VERSION "12.2.7"

NS_ :

BS_:

BU_: AMP CPD EASC HUD MHU XGW_Info PAS_Info PAS_LITE FCAM_Info

BO_ 1153 BCM_WarnMsg: 8 XGW_Info
 SG_ CHSKM_BCM_WarnMsg : 7|8@0+ (1,0) [0|255] "" MHU
 SG_ ALV_BCM_WarnMsg : 11|4@0+ (1,0) [0|14] "" MHU
 SG_ BCM_NoValidKey_1 : 12|1@0+ (1,0) [0|1] "" MHU
 SG_ BCM_SSB_defect : 13|1@0+ (1,0) [0|1] "" MHU
 SG_ BCM_WrongGearPosToStart : 14|1@0+ (1,0) [0|1] "" MHU
 SG_ BCM_NoValidKey_2 : 15|1@0+ (1,0) [0|1] "" MHU
 SG_ BCM_PressBrakeToStart : 16|1@0+ (1,0) [0|1] "" MHU
 SG_ BCM_TurnOffPosLightRemindr : 17|1@0+ (1,0) [0|1] "" MHU
 SG_ BCM_KeyFob_LowBattery : 18|1@0+ (1,0) [0|1] "" MHU
 SG_ BCM_StopLightDefect : 19|1@0+ (1,0) [0|1] "" MHU
 SG_ BCM_LowBeamDefect : 20|1@0+ (1,0) [0|1] "" MHU
 SG_ BCM_HighBeamDefect : 21|1@0+ (1,0) [0|1] "" MHU
 SG_ BCM_PositionLightDefect : 22|1@0+ (1,0) [0|1] "" MHU
 SG_ BCM_CHMLS_Defect : 23|1@0+ (1,0) [0|1] "" MHU
 SG_ BCM_LicencePlateLight_Defect : 24|1@0+ (1,0) [0|1] "" MHU
 SG_ BCM_FrontFog_Defect : 25|1@0+ (1,0) [0|1] "" MHU
 SG_ BCM_RearFog_Defect : 26|1@0+ (1,0) [0|1] "" MHU
 SG_ BCM_ReverseLightDefect : 27|1@0+ (1,0) [0|1] "" MHU
 SG_ BCM_RLS_Malfunction : 28|1@0+ (1,0) [0|1] "" MHU
 SG_ BCM_12VBattery_LowLevel : 29|1@0+ (1,0) [0|1] "" MHU
 SG_ BCM_ForgetKeyFOBInCar : 30|1@0+ (1,0) [0|1] "" MHU
 SG_ BCM_12VBattery_Discharging : 31|1@0+ (1,0) [0|1] "" MHU
 SG_ BCM_TurnIndicatorDefect : 32|1@0+ (1,0) [0|1] "" MHU,FCAM_Info
 SG_ BCM_dTPMS_Malfunc : 33|1@0+ (1,0) [0|1] "" MHU
 SG_ BCM_dTPMS_Malfunc_LostSensor : 34|1@0+ (1,0) [0|1] "" MHU
 SG_ BCM_dTPMS_LowPressure : 35|1@0+ (1,0) [0|1] "" MHU
 SG_ BCM_dTPMS_RapidLeak : 36|1@0+ (1,0) [0|1] "" MHU
 SG_ BCM_dTPMS_HighTemperature : 37|1@0+ (1,0) [0|1] "" MHU
 SG_ BCM_dTPMS_HighPressure : 38|1@0+ (1,0) [0|1] "" MHU
 SG_ BCM_dTPMS_LowBattery : 39|1@0+ (1,0) [0|1] "" MHU
 SG_ BCM_Keyfob_Leftcar : 40|1@0+ (1,0) [0|1] "" MHU
 SG_ BCM_IDB_Brakelight_Malfunction : 41|1@0+ (1,0) [0|1] "" MHU
 SG_ BCM_VCU_Brakelight_Malfunction : 42|1@0+ (1,0) [0|1] "" MHU
 SG_ BCM_ADAS_Turnlight_Malfunction : 43|1@0+ (1,0) [0|1] "" MHU
 SG_ BCM_ADAS_Highbeam_Malfunction : 44|1@0+ (1,0) [0|1] "" MHU
 SG_ BCM_ADAS_LowBeam_Malfunction : 45|1@0+ (1,0) [0|1] "" MHU
 SG_ BCM_MHU_Malfunction : 46|1@0+ (1,0) [0|1] "" MHU
 SG_ BCM_BCM_Malfunction : 47|1@0+ (1,0) [0|1] "" MHU
 SG_ BCM_SCM_Malfunction : 48|1@0+ (1,0) [0|1] "" MHU
 SG_ BCM_CrashSignalDefect : 49|1@0+ (1,0) [0|1] "" MHU
 SG_ BCM_FrontWiperDefect : 51|1@0+ (1,0) [0|1] "" MHU
 SG_ BCM_Rear_RightDoorLockDefect : 52|1@0+ (1,0) [0|1] "" MHU
 SG_ BCM_RearLeftDoorLockDefect : 53|1@0+ (1,0) [0|1] "" MHU
 SG_ BCM_Front_RightDoorLockDefect : 54|1@0+ (1,0) [0|1] "" MHU
 SG_ BCM_FrontLeftDoorLockDefect : 55|1@0+ (1,0) [0|1] "" MHU
 SG_ BCM_LDML_Malfunction : 56|1@0+ (1,0) [0|1] "" MHU
 SG_ BCM_LDMR_Malfunction : 57|1@0+ (1,0) [0|1] "" MHU
 SG_ BCM_RLBL_Malfunction : 58|1@0+ (1,0) [0|1] "" MHU
 SG_ BCM_RLBR_Malfunction : 59|1@0+ (1,0) [0|1] "" MHU
 SG_ BCM_RLT_Malfunction : 60|1@0+ (1,0) [0|1] "" MHU
 SG_ BCM_BCM_POWER_Malfunction : 61|1@0+ (1,0) [0|1] "" MHU
 SG_ BCM_IDB_AutoHazardBlinking_Malf : 62|1@0+ (1,0) [0|1] "" MHU
 SG_ BCM_AutoHLLevelingFault : 63|1@0+ (1,0) [0|1] "" MHU

BO_ 1154 XGW_WarnMsg: 8 XGW_Info
  SG_ CHSKM_XGW_WarnMsg : 7|8@0+ (1,0) [0|255] "" MHU
  SG_ ALV_XGW_WarnMsg : 11|4@0+ (1,0) [0|14] "" MHU
  SG_ XGW_AutoHLLevelingFault : 12|1@0+ (1,0) [0|1] "-" MHU
  SG_ XGW_WasherFluidLvlSw : 13|1@0+ (1,0) [0|1] "-" MHU
  SG_ XGW_Warning_Flag_3 : 14|1@0+ (1,0) [0|1] "-" MHU
  SG_ XGW_Warning_Flag_4 : 15|1@0+ (1,0) [0|1] "-" MHU
  SG_ XGW_Warning_Flag_5 : 16|1@0+ (1,0) [0|1] "-" MHU
  SG_ XGW_Warning_Flag_6 : 17|1@0+ (1,0) [0|1] "-" MHU
  SG_ XGW_Warning_Flag_7 : 18|1@0+ (1,0) [0|1] "-" MHU
  SG_ XGW_Warning_Flag_8 : 19|1@0+ (1,0) [0|1] "-" MHU
  SG_ XGW_Warning_Flag_9 : 20|1@0+ (1,0) [0|1] "-" MHU
  SG_ XGW_Warning_Flag_10 : 21|1@0+ (1,0) [0|1] "-" MHU
  SG_ XGW_Warning_Flag_11 : 22|1@0+ (1,0) [0|1] "-" MHU
  SG_ XGW_Warning_Flag_12 : 23|1@0+ (1,0) [0|1] "-" MHU
  SG_ XGW_Reserved_signal1 : 31|8@0+ (1,0) [0|255] "-" MHU
  SG_ XGW_Reserved_signal2 : 39|8@0+ (1,0) [0|255] "-" MHU
  SG_ XGW_Reserved_signal3 : 47|8@0+ (1,0) [0|255] "-" MHU
  SG_ XGW_Reserved_signal4 : 55|8@0+ (1,0) [0|255] "-" MHU
  SG_ XGW_Reserved_signal5 : 63|8@0+ (1,0) [0|255] "-" MHU

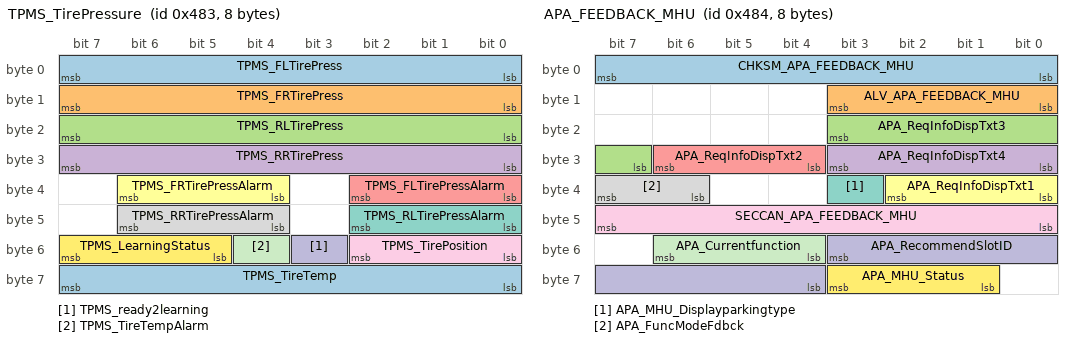
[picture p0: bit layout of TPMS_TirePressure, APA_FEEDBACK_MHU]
BO_ 1155 TPMS_TirePressure: 8 XGW_Info
  SG_ TPMS_FLTirePress : 7|8@0+ (1.373,0) [0|350] "kPa" MHU
  SG_ TPMS_FRTirePress : 15|8@0+ (1.373,0) [0|350] "kPa" MHU
  SG_ TPMS_RLTirePress : 23|8@0+ (1.373,0) [0|350] "kPa" MHU
  SG_ TPMS_RRTirePress : 31|8@0+ (1.373,0) [0|350] "kPa" MHU
  SG_ TPMS_FLTirePressAlarm : 34|3@0+ (1,0) [0|7] "" FCAM_Info,MHU
  SG_ TPMS_FRTirePressAlarm : 38|3@0+ (1,0) [0|7] "" FCAM_Info,MHU
  SG_ TPMS_RLTirePressAlarm : 42|3@0+ (1,0) [0|7] "" FCAM_Info,MHU
  SG_ TPMS_RRTirePressAlarm : 46|3@0+ (1,0) [0|7] "" FCAM_Info,MHU
  SG_ TPMS_TirePosition : 50|3@0+ (1,0) [0|7] "-" MHU
  SG_ TPMS_ready2learning : 51|1@0+ (1,0) [0|1] "-" MHU
  SG_ TPMS_TireTempAlarm : 52|1@0+ (1,0) [0|1] "-" MHU
  SG_ TPMS_LearningStatus : 55|3@0+ (1,0) [0|7] "-" MHU
  SG_ TPMS_TireTemp : 63|8@0+ (1,-40) [-40|215] "Degree C" MHU

BO_ 1156 APA_FEEDBACK_MHU: 8 PAS_Info
  SG_ CHKSM_APA_FEEDBACK_MHU : 7|8@0+ (1,0) [0|255] "" MHU,XGW_Info
  SG_ ALV_APA_FEEDBACK_MHU : 11|4@0+ (1,0) [0|14] "" MHU,XGW_Info
  SG_ APA_ReqInfoDispTxt3 : 19|5@0+ (1,0) [0|31] "-" MHU
  SG_ APA_ReqInfoDispTxt4 : 27|4@0+ (1,0) [0|15] "-" MHU
  SG_ APA_ReqInfoDispTxt2 : 30|3@0+ (1,0) [0|7] "-" MHU
  SG_ APA_ReqInfoDispTxt1 : 34|3@0+ (1,0) [0|7] "-" MHU
  SG_ APA_MHU_Displayparkingtype : 35|1@0+ (1,0) [0|1] "-" MHU
  SG_ APA_FuncModeFdbck : 39|2@0+ (1,0) [0|3] "-" MHU
  SG_ SECCAN_APA_FEEDBACK_MHU : 47|8@0+ (1,0) [0|255] ""  MHU
  SG_ APA_RecommendSlotID : 51|8@0+ (1,0) [0|255] "-" MHU
  SG_ APA_Currentfunction : 54|3@0+ (1,0) [0|7] "-" MHU
  SG_ APA_MHU_Status : 59|3@0+ (1,0) [0|7] "-" MHU,XGW_Info

BO_ 1157 TBox_RemVehCtrlAssist_SecOC3: 8 MHU
 SG_ TBOX_RPADirSel : 15|4@0+ (1,0) [0|15] ""  PAS_Info

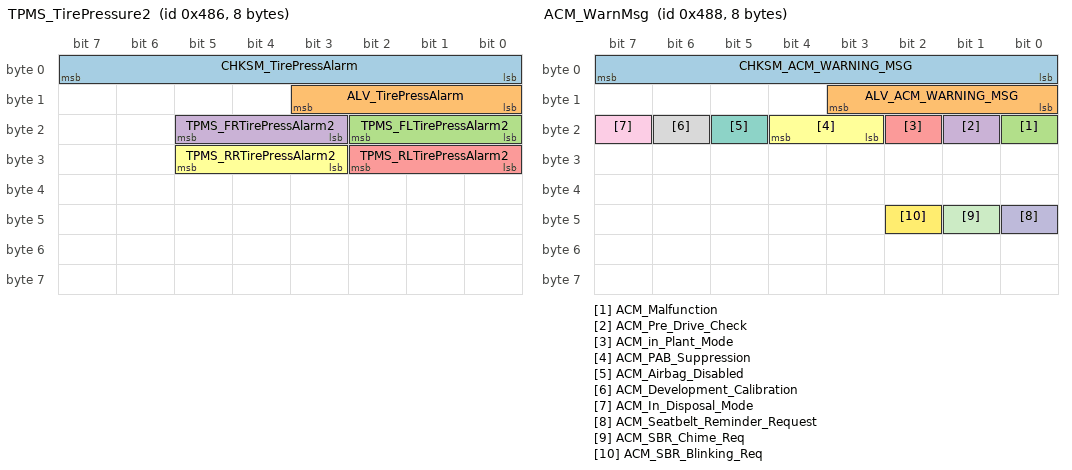
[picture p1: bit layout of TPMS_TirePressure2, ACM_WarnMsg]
BO_ 1158 TPMS_TirePressure2: 8 XGW_Info
 SG_ CHKSM_TirePressAlarm : 7|8@0+ (1,0) [0|255] ""  FCAM_Info,MHU
 SG_ ALV_TirePressAlarm : 11|4@0+ (1,0) [0|14] ""  FCAM_Info,MHU
 SG_ TPMS_FLTirePressAlarm2 : 18|3@0+ (1,0) [0|7] ""  FCAM_Info,MHU
 SG_ TPMS_FRTirePressAlarm2 : 21|3@0+ (1,0) [0|7] ""  FCAM_Info,MHU
 SG_ TPMS_RLTirePressAlarm2 : 26|3@0+ (1,0) [0|7] ""  FCAM_Info,MHU
 SG_ TPMS_RRTirePressAlarm2 : 29|3@0+ (1,0) [0|7] ""  FCAM_Info,MHU

BO_ 1160 ACM_WarnMsg: 8 XGW_Info
  SG_ CHKSM_ACM_WARNING_MSG : 7|8@0+ (1,0) [0|255] "" FCAM_Info,MHU
  SG_ ALV_ACM_WARNING_MSG : 11|4@0+ (1,0) [0|14] "" FCAM_Info,MHU
  SG_ ACM_Malfunction : 16|1@0+ (1,0) [0|1] "" FCAM_Info,MHU
  SG_ ACM_Pre_Drive_Check : 17|1@0+ (1,0) [0|1] "Bit" FCAM_Info,MHU
  SG_ ACM_in_Plant_Mode : 18|1@0+ (1,0) [0|1] "Bit" FCAM_Info,MHU
  SG_ ACM_PAB_Suppression : 20|2@0+ (1,0) [0|3] "Bit" FCAM_Info,MHU
  SG_ ACM_Airbag_Disabled : 21|1@0+ (1,0) [0|1] "" FCAM_Info,MHU
  SG_ ACM_Development_Calibration : 22|1@0+ (1,0) [0|1] "" FCAM_Info,MHU
  SG_ ACM_In_Disposal_Mode : 23|1@0+ (1,0) [0|1] "" FCAM_Info,MHU
  SG_ ACM_Seatbelt_Reminder_Request : 40|1@0+ (1,0) [0|1] "" FCAM_Info,MHU
  SG_ ACM_SBR_Chime_Req : 41|1@0+ (1,0) [0|1] "" FCAM_Info,MHU
  SG_ ACM_SBR_Blinking_Req : 42|1@0+ (1,0) [0|1] "" FCAM_Info,MHU

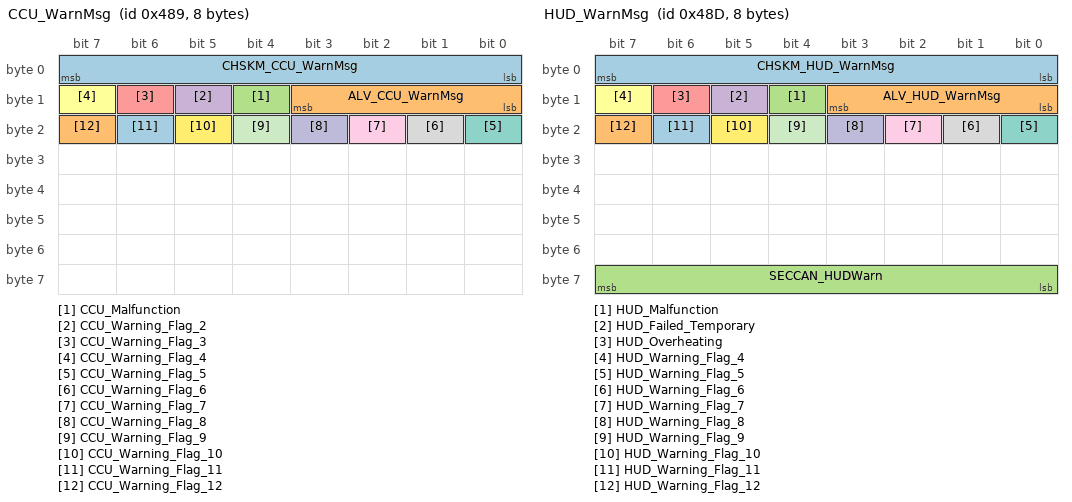
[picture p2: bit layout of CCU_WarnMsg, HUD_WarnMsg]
BO_ 1161 CCU_WarnMsg: 8 XGW_Info
  SG_ CHSKM_CCU_WarnMsg : 7|8@0+ (1,0) [0|255] "" MHU
  SG_ ALV_CCU_WarnMsg : 11|4@0+ (1,0) [0|14] "" MHU
  SG_ CCU_Malfunction : 12|1@0+ (1,0) [0|1] "" MHU
  SG_ CCU_Warning_Flag_2 : 13|1@0+ (1,0) [0|1] "-" MHU
  SG_ CCU_Warning_Flag_3 : 14|1@0+ (1,0) [0|1] "" MHU
  SG_ CCU_Warning_Flag_4 : 15|1@0+ (1,0) [0|1] "-" MHU
  SG_ CCU_Warning_Flag_5 : 16|1@0+ (1,0) [0|1] "-" MHU
  SG_ CCU_Warning_Flag_6 : 17|1@0+ (1,0) [0|1] "-" MHU
  SG_ CCU_Warning_Flag_7 : 18|1@0+ (1,0) [0|1] "-" MHU
  SG_ CCU_Warning_Flag_8 : 19|1@0+ (1,0) [0|1] "" MHU
  SG_ CCU_Warning_Flag_9 : 20|1@0+ (1,0) [0|1] "" MHU
  SG_ CCU_Warning_Flag_10 : 21|1@0+ (1,0) [0|1] "" MHU
  SG_ CCU_Warning_Flag_11 : 22|1@0+ (1,0) [0|1] "" MHU
  SG_ CCU_Warning_Flag_12 : 23|1@0+ (1,0) [0|1] "" MHU

BO_ 1165 HUD_WarnMsg: 8 HUD
  SG_ CHSKM_HUD_WarnMsg : 7|8@0+ (1,0) [0|255] "" MHU
  SG_ ALV_HUD_WarnMsg : 11|4@0+ (1,0) [0|14] "" MHU
  SG_ HUD_Malfunction : 12|1@0+ (1,0) [0|1] "-" MHU
  SG_ HUD_Failed_Temporary : 13|1@0+ (1,0) [0|1] "-" MHU
  SG_ HUD_Overheating : 14|1@0+ (1,0) [0|1] "-" MHU
  SG_ HUD_Warning_Flag_4 : 15|1@0+ (1,0) [0|1] "-" MHU
  SG_ HUD_Warning_Flag_5 : 16|1@0+ (1,0) [0|1] "-" MHU
  SG_ HUD_Warning_Flag_6 : 17|1@0+ (1,0) [0|1] "-" MHU
  SG_ HUD_Warning_Flag_7 : 18|1@0+ (1,0) [0|1] "-" MHU
  SG_ HUD_Warning_Flag_8 : 19|1@0+ (1,0) [0|1] "-" MHU
  SG_ HUD_Warning_Flag_9 : 20|1@0+ (1,0) [0|1] "-" MHU
  SG_ HUD_Warning_Flag_10 : 21|1@0+ (1,0) [0|1] "-" MHU
  SG_ HUD_Warning_Flag_11 : 22|1@0+ (1,0) [0|1] "-" MHU
  SG_ HUD_Warning_Flag_12 : 23|1@0+ (1,0) [0|1] "-" MHU
  SG_ SECCAN_HUDWarn : 63|8@0+ (1,0) [0|255] "" MHU

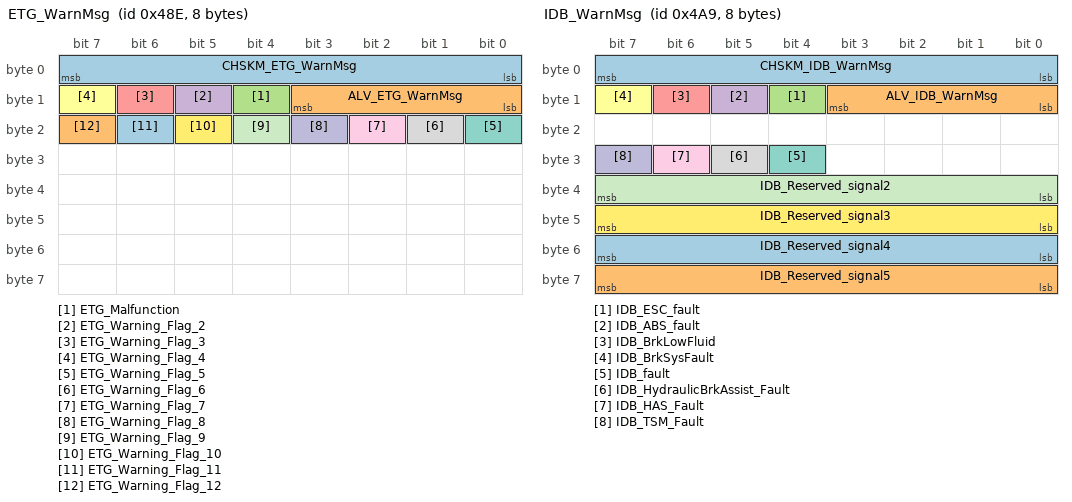
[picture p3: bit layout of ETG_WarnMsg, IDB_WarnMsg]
BO_ 1166 ETG_WarnMsg: 8 XGW_Info
  SG_ CHSKM_ETG_WarnMsg : 7|8@0+ (1,0) [0|255] "" MHU
  SG_ ALV_ETG_WarnMsg : 11|4@0+ (1,0) [0|14] "" MHU
  SG_ ETG_Malfunction : 12|1@0+ (1,0) [0|1] "-" MHU
  SG_ ETG_Warning_Flag_2 : 13|1@0+ (1,0) [0|1] "-" MHU
  SG_ ETG_Warning_Flag_3 : 14|1@0+ (1,0) [0|1] "" MHU
  SG_ ETG_Warning_Flag_4 : 15|1@0+ (1,0) [0|1] "" MHU
  SG_ ETG_Warning_Flag_5 : 16|1@0+ (1,0) [0|1] "-" MHU
  SG_ ETG_Warning_Flag_6 : 17|1@0+ (1,0) [0|1] "-" MHU
  SG_ ETG_Warning_Flag_7 : 18|1@0+ (1,0) [0|1] "-" MHU
  SG_ ETG_Warning_Flag_8 : 19|1@0+ (1,0) [0|1] "" MHU
  SG_ ETG_Warning_Flag_9 : 20|1@0+ (1,0) [0|1] "" MHU
  SG_ ETG_Warning_Flag_10 : 21|1@0+ (1,0) [0|1] "" MHU
  SG_ ETG_Warning_Flag_11 : 22|1@0+ (1,0) [0|1] "-" MHU
  SG_ ETG_Warning_Flag_12 : 23|1@0+ (1,0) [0|1] "" MHU

BO_ 1168 GS_WarnMsg: 8 XGW_Info
  SG_ CHSKM_GS_WarnMsg : 7|8@0+ (1,0) [0|255] "" MHU
  SG_ ALV_GS_WarnMsg : 11|4@0+ (1,0) [0|14] "" MHU
  SG_ GS_Warning_Flag_1 : 12|1@0+ (1,0) [0|1] "" MHU
  SG_ GS_Warning_Flag_2 : 13|1@0+ (1,0) [0|1] "" MHU
  SG_ GS_Warning_Flag_3 : 14|1@0+ (1,0) [0|1] "-" MHU
  SG_ GS_Warning_Flag_4 : 15|1@0+ (1,0) [0|1] "-" MHU
  SG_ GS_Warning_Flag_5 : 16|1@0+ (1,0) [0|1] "" MHU
  SG_ GS_Warning_Flag_6 : 17|1@0+ (1,0) [0|1] "-" MHU
  SG_ GS_Warning_Flag_7 : 18|1@0+ (1,0) [0|1] "" MHU
  SG_ GS_Warning_Flag_8 : 19|1@0+ (1,0) [0|1] "" MHU
  SG_ GS_Warning_Flag_9 : 20|1@0+ (1,0) [0|1] "-" MHU
  SG_ GS_Warning_Flag_10 : 21|1@0+ (1,0) [0|1] "-" MHU
  SG_ GS_Warning_Flag_11 : 22|1@0+ (1,0) [0|1] "" MHU
  SG_ GS_Warning_Flag_12 : 23|1@0+ (1,0) [0|1] "" MHU
  SG_ GS_Reserved_signal1 : 31|8@0+ (1,0) [0|255] "-" MHU
  SG_ GS_Reserved_signal2 : 39|8@0+ (1,0) [0|255] "" MHU
  SG_ GS_Reserved_signal3 : 47|8@0+ (1,0) [0|255] "" MHU
  SG_ GS_Reserved_signal4 : 55|8@0+ (1,0) [0|255] "-" MHU
  SG_ GS_Reserved_signal5 : 63|8@0+ (1,0) [0|255] "" MHU

BO_ 1171 BMS_WarnMsg: 8 XGW_Info
  SG_ CHSKM_BMS_WarnMsg : 7|8@0+ (1,0) [0|255] "" HUD,MHU
  SG_ ALV_BMS_WarnMsg : 11|4@0+ (1,0) [0|14] "" HUD,MHU
  SG_ BMS_PackTempSts : 13|2@0+ (1,0) [0|3] "" MHU
  SG_ BMS_ThermalRunaway : 14|1@0+ (1,0) [0|1] "" HUD,MHU
  SG_ BMS_BatteryReplacement : 15|1@0+ (1,0) [0|1] "" MHU
  SG_ BMS_Warning_PowerDegrade : 16|1@0+ (1,0) [0|1] "" MHU
  SG_ BMS_Warning_DeltaSoC : 17|1@0+ (1,0) [0|1] "" MHU
  SG_ BMS_Warning_HVILSts : 18|1@0+ (1,0) [0|1] "" MHU
  SG_ BMS_Warning_Isolation : 19|1@0+ (1,0) [0|1] "" MHU
  SG_ BMS_Warning_CoolantLeakage : 20|1@0+ (1,0) [0|1] "" MHU
  SG_ BMS_MalfunctionSts : 21|1@0+ (1,0) [0|1] "" MHU
  SG_ BMS_LowBattery : 23|2@0+ (1,0) [0|3] "" HUD,MHU
  SG_ BMS_Warning_DeltaTemperature : 31|8@0+ (1,0) [0|255] "" MHU
  SG_ BMS_Warning_BDUTemperatureSts : 39|8@0+ (1,0) [0|255] "" MHU
  SG_ BMS_Warning_Contactor_Aging : 47|1@0+ (1,0) [0|1] "" MHU
  SG_ BMS_Reserved_signal4 : 55|8@0+ (1,0) [0|255] "" MHU
  SG_ BMS_Reserved_signal5 : 63|8@0+ (1,0) [0|255] "" MHU

BO_ 1178 EDS_R_WarnMsg: 8 XGW_Info
  SG_ CHSKM_EDS_R_WarnMsg : 7|8@0+ (1,0) [0|255] "" MHU
  SG_ ALV_EDS_R_WarnMsg : 11|4@0+ (1,0) [0|14] "" MHU
  SG_ EDS_R_Warning_Flag_1 : 12|1@0+ (1,0) [0|1] "" MHU
  SG_ EDS_R_Warning_Flag_2 : 13|1@0+ (1,0) [0|1] "" MHU
  SG_ EDS_R_Warning_Flag_3 : 14|1@0+ (1,0) [0|1] "" MHU
  SG_ EDS_R_Warning_Flag_4 : 15|1@0+ (1,0) [0|1] "-" MHU
  SG_ EDS_R_Warning_Flag_5 : 16|1@0+ (1,0) [0|1] "" MHU
  SG_ EDS_R_Warning_Flag_6 : 17|1@0+ (1,0) [0|1] "-" MHU
  SG_ EDS_R_Warning_Flag_7 : 18|1@0+ (1,0) [0|1] "" MHU
  SG_ EDS_R_Warning_Flag_8 : 19|1@0+ (1,0) [0|1] "" MHU
  SG_ EDS_R_Warning_Flag_9 : 20|1@0+ (1,0) [0|1] "-" MHU
  SG_ EDS_R_Warning_Flag_10 : 21|1@0+ (1,0) [0|1] "" MHU
  SG_ EDS_R_Warning_Flag_11 : 22|1@0+ (1,0) [0|1] "" MHU
  SG_ EDS_R_Warning_Flag_12 : 23|1@0+ (1,0) [0|1] "-" MHU
  SG_ EDS_R_Reserved_signal1 : 31|8@0+ (1,0) [0|255] "" MHU
  SG_ EDS_R_Reserved_signal2 : 39|8@0+ (1,0) [0|255] "" MHU
  SG_ EDS_R_Reserved_signal3 : 47|8@0+ (1,0) [0|255] "-" MHU
  SG_ EDS_R_Reserved_signal4 : 55|8@0+ (1,0) [0|255] "-" MHU
  SG_ EDS_R_Reserved_signal5 : 63|8@0+ (1,0) [0|255] "-" MHU

BO_ 1179 EDS_F_WarnMsg: 8 XGW_Info
  SG_ CHSKM_EDS_F_WarnMsg : 7|8@0+ (1,0) [0|255] "" MHU
  SG_ ALV_EDS_F_WarnMsg : 11|4@0+ (1,0) [0|14] "" MHU
  SG_ EDS_F_Warning_Flag_1 : 12|1@0+ (1,0) [0|1] "" MHU
  SG_ EDS_F_Warning_Flag_2 : 13|1@0+ (1,0) [0|1] "-" MHU
  SG_ EDS_F_Warning_Flag_3 : 14|1@0+ (1,0) [0|1] "-" MHU
  SG_ EDS_F_Warning_Flag_4 : 15|1@0+ (1,0) [0|1] "" MHU
  SG_ EDS_F_Warning_Flag_5 : 16|1@0+ (1,0) [0|1] "" MHU
  SG_ EDS_F_Warning_Flag_6 : 17|1@0+ (1,0) [0|1] "-" MHU
  SG_ EDS_F_Warning_Flag_7 : 18|1@0+ (1,0) [0|1] "-" MHU
  SG_ EDS_F_Warning_Flag_8 : 19|1@0+ (1,0) [0|1] "" MHU
  SG_ EDS_F_Warning_Flag_9 : 20|1@0+ (1,0) [0|1] "" MHU
  SG_ EDS_F_Warning_Flag_10 : 21|1@0+ (1,0) [0|1] "-" MHU
  SG_ EDS_F_Warning_Flag_11 : 22|1@0+ (1,0) [0|1] "-" MHU
  SG_ EDS_F_Warning_Flag_12 : 23|1@0+ (1,0) [0|1] "" MHU
  SG_ EDS_F_Reserved_signal1 : 31|8@0+ (1,0) [0|255] "" MHU
  SG_ EDS_F_Reserved_signal2 : 39|8@0+ (1,0) [0|255] "-" MHU
  SG_ EDS_F_Reserved_signal3 : 47|8@0+ (1,0) [0|255] "" MHU
  SG_ EDS_F_Reserved_signal4 : 55|8@0+ (1,0) [0|255] "-" MHU
  SG_ EDS_F_Reserved_signal5 : 63|8@0+ (1,0) [0|255] "" MHU

BO_ 1191 RCU_WarnMsg: 8 XGW_Info
  SG_ CHSKM_RCU_WarnMsg : 7|8@0+ (1,0) [0|255] "" MHU
  SG_ ALV_RCU_WarnMsg : 11|4@0+ (1,0) [0|14] "" MHU
  SG_ RCU_DAA_NoOpDoorOpen : 12|1@0+ (1,0) [0|1] "" MHU
  SG_ RCU_EHandBrk_fault : 13|1@0+ (1,0) [0|1] "" MHU
  SG_ RCU_EOL_NotDone : 14|1@0+ (1,0) [0|1] "" MHU
  SG_ RCU_ECD_RWU_active : 15|1@0+ (1,0) [0|1] "" MHU
  SG_ RCU_ParkOnSteepInclination : 16|1@0+ (1,0) [0|1] "" MHU
  SG_ RCU_BrkForceNotEnough : 17|1@0+ (1,0) [0|1] "" MHU
  SG_ RCU_ReleaseEPB_Wo_PressBrk : 20|1@0+ (1,0) [0|1] "" MHU
  SG_ RCU_ParkBrkApplied : 21|1@0+ (1,0) [0|1] "" MHU
  SG_ RCU_Swch_Mafnc : 27|1@0+ (1,0) [0|1] "" MHU
  SG_ RCU_DAA_NoOpBeltUnbuckled : 28|1@0+ (1,0) [0|1] "" MHU
  SG_ RCU_RollerBenchMode : 29|1@0+ (1,0) [0|1] "" MHU
  SG_ RCU_EPB_ParkLampState : 31|2@0+ (1,0) [0|3] "" MHU
  SG_ RCU_EPB_WarnLampState : 34|2@0+ (1,0) [0|3] "" MHU
  SG_ RCU_WflagRes36 : 36|1@0+ (1,0) [0|1] "" MHU
  SG_ RCU_WflagRes37 : 37|1@0+ (1,0) [0|1] "" MHU
  SG_ RCU_WflagRes38 : 38|1@0+ (1,0) [0|1] "" MHU
  SG_ RCU_WflagRes39 : 39|1@0+ (1,0) [0|1] "" MHU
  SG_ RCU_WflagRes40 : 40|1@0+ (1,0) [0|1] "" MHU
  SG_ RCU_WflagRes41 : 41|1@0+ (1,0) [0|1] "" MHU
  SG_ RCU_WflagRes42 : 42|1@0+ (1,0) [0|1] "" MHU
  SG_ RCU_WflagRes43 : 43|1@0+ (1,0) [0|1] "" MHU
  SG_ RCU_WflagRes44 : 44|1@0+ (1,0) [0|1] "" MHU
  SG_ RCU_WflagRes45 : 45|1@0+ (1,0) [0|1] "" MHU
  SG_ RCU_WflagRes46 : 46|1@0+ (1,0) [0|1] "" MHU
  SG_ RCU_WflagRes47 : 47|1@0+ (1,0) [0|1] "" MHU
  SG_ RCU_Reserved_signal1 : 55|8@0+ (1,0) [0|255] "" MHU

BO_ 1192 EPS_WarnMsg: 8 XGW_Info
  SG_ CHSKM_EPS_WarnMsg : 7|8@0+ (1,0) [0|255] "" MHU
  SG_ ALV_EPS_WarnMsg : 11|4@0+ (1,0) [0|14] "" MHU
  SG_ EPS_Malfunction : 12|1@0+ (1,0) [0|1] "-" MHU
  SG_ EPS_Reduced : 13|1@0+ (1,0) [0|1] "-" MHU
  SG_ EPS_Overheat : 14|1@0+ (1,0) [0|1] "" MHU
  SG_ EPS_NotReady : 15|1@0+ (1,0) [0|1] "-" MHU
  SG_ EPS_Warning_Flag_5 : 16|1@0+ (1,0) [0|1] "-" MHU
  SG_ EPS_Warning_Flag_6 : 17|1@0+ (1,0) [0|1] "" MHU
  SG_ EPS_Warning_Flag_7 : 18|1@0+ (1,0) [0|1] "" MHU
  SG_ EPS_Warning_Flag_8 : 19|1@0+ (1,0) [0|1] "-" MHU
  SG_ EPS_Warning_Flag_9 : 20|1@0+ (1,0) [0|1] "-" MHU
  SG_ EPS_Warning_Flag_10 : 21|1@0+ (1,0) [0|1] "" MHU
  SG_ EPS_Warning_Flag_11 : 22|1@0+ (1,0) [0|1] "" MHU
  SG_ EPS_Warning_Flag_12 : 23|1@0+ (1,0) [0|1] "-" MHU
  SG_ EPS_Reserved_signal1 : 31|8@0+ (1,0) [0|255] "" MHU
  SG_ EPS_Reserved_signal2 : 39|8@0+ (1,0) [0|255] "" MHU
  SG_ EPS_Reserved_signal3 : 47|8@0+ (1,0) [0|255] "-" MHU
  SG_ EPS_Reserved_signal4 : 55|8@0+ (1,0) [0|255] "" MHU
  SG_ EPS_Reserved_signal5 : 63|8@0+ (1,0) [0|255] "" MHU

BO_ 1193 IDB_WarnMsg: 8 XGW_Info
  SG_ CHSKM_IDB_WarnMsg : 7|8@0+ (1,0) [0|255] "" MHU
  SG_ ALV_IDB_WarnMsg : 11|4@0+ (1,0) [0|14] "" MHU
  SG_ IDB_ESC_fault : 12|1@0+ (1,0) [0|1] "-" MHU
  SG_ IDB_ABS_fault : 13|1@0+ (1,0) [0|1] "" MHU
  SG_ IDB_BrkLowFluid : 14|1@0+ (1,0) [0|1] "" MHU
  SG_ IDB_BrkSysFault : 15|1@0+ (1,0) [0|1] "-" MHU
  SG_ IDB_fault : 28|1@0+ (1,0) [0|1] "" MHU
  SG_ IDB_HydraulicBrkAssist_Fault : 29|1@0+ (1,0) [0|1] "-" MHU
  SG_ IDB_HAS_Fault : 30|1@0+ (1,0) [0|1] "" MHU
  SG_ IDB_TSM_Fault : 31|1@0+ (1,0) [0|1] "" MHU
  SG_ IDB_Reserved_signal2 : 39|8@0+ (1,0) [0|255] "-" MHU
  SG_ IDB_Reserved_signal3 : 47|8@0+ (1,0) [0|255] "-" MHU
  SG_ IDB_Reserved_signal4 : 55|8@0+ (1,0) [0|255] "-" MHU
  SG_ IDB_Reserved_signal5 : 63|8@0+ (1,0) [0|255] "" MHU

BO_ 1196 VCU_WarnMsg: 8 XGW_Info
  SG_ CHSKM_VCU_WarnMsg : 7|8@0+ (1,0) [0|255] "" MHU
  SG_ ALV_VCU_WarnMsg : 11|4@0+ (1,0) [0|14] "" MHU
  SG_ VCU_GearPOnlyAtStationaryAlert : 12|1@0+ (1,0) [0|1] "" MHU
  SG_ VCU_GearP_NotPossibleAlert : 13|1@0+ (1,0) [0|1] "" MHU
  SG_ VCU_PressBrakeToEngageGear : 14|1@0+ (1,0) [0|1] "" MHU
  SG_ VCU_CantChangeGear : 15|1@0+ (1,0) [0|1] "" MHU
  SG_ VCU_GearMalfunction : 16|1@0+ (1,0) [0|1] "" MHU
  SG_ VCU_RangeAlert : 17|1@0+ (1,0) [0|1] "" MHU
  SG_ VCU_HVSystemReduced : 18|1@0+ (1,0) [0|1] "" MHU
  SG_ VCU_FrontEDSReduced : 19|1@0+ (1,0) [0|1] "" MHU
  SG_ VCU_FrontEDS_Malfunc : 20|1@0+ (1,0) [0|1] "" MHU
  SG_ VCU_RearEDSReduced : 21|1@0+ (1,0) [0|1] "" MHU
  SG_ VCU_RearEDS_Malfunc : 22|1@0+ (1,0) [0|1] "" MHU
  SG_ VCU_CoolingSystem_Malfunc : 23|1@0+ (1,0) [0|1] "" MHU
  SG_ VCU_NeutralRequest : 24|1@0+ (1,0) [0|1] "" MHU
  SG_ VCU_SoftShutdown : 25|1@0+ (1,0) [0|1] "" MHU
  SG_ VCU_EmergencyShutdown : 26|1@0+ (1,0) [0|1] "" MHU
  SG_ VCU_ChgPortDoorSys_Malfunc : 27|1@0+ (1,0) [0|1] "" MHU
  SG_ VCU_Gearchange_NotPossible : 28|1@0+ (1,0) [0|1] "" MHU
  SG_ VCU_12v_Warning : 29|1@0+ (1,0) [0|1] "" MHU
  SG_ VCU_WflagRes19 : 30|1@0+ (1,0) [0|1] "" MHU
  SG_ VCU_WflagRes20 : 31|1@0+ (1,0) [0|1] "" MHU
  SG_ VCU_WflagRes21 : 32|1@0+ (1,0) [0|1] "" MHU
  SG_ VCU_WflagRes22 : 33|1@0+ (1,0) [0|1] "" MHU
  SG_ VCU_WflagRes23 : 34|1@0+ (1,0) [0|1] "" MHU
  SG_ VCU_WflagRes24 : 35|1@0+ (1,0) [0|1] "" MHU
  SG_ VCU_WflagRes25 : 36|1@0+ (1,0) [0|1] "" MHU
  SG_ VCU_WflagRes26 : 37|1@0+ (1,0) [0|1] "" MHU
  SG_ VCU_WflagRes27 : 38|1@0+ (1,0) [0|1] "" MHU
  SG_ VCU_SuperFastCharge_longer : 39|1@0+ (1,0) [0|1] "" MHU
  SG_ VCU_InvalidLimitSpeed : 46|1@0+ (1,0) [0|1] "" MHU
  SG_ VCU_InvalidCruiseSpeed : 47|1@0+ (1,0) [0|1] "" MHU
  SG_ VCU_Reserved_signal2 : 55|8@0+ (1,0) [0|255] "" MHU
  SG_ VCU_Reserved_signal3 : 63|8@0+ (1,0) [0|255] "" MHU

BO_ 1198 EASC_WarnMsg: 8 EASC
  SG_ CHSKM_EASC_WarnMsg : 7|8@0+ (1,0) [0|255] "" MHU
  SG_ ALV_EASC_WarnMsg : 11|4@0+ (1,0) [0|14] "" MHU
  SG_ EASC_Warning_Flag_1 : 12|1@0+ (1,0) [0|1] "-" MHU
  SG_ EASC_Warning_Flag_2 : 13|1@0+ (1,0) [0|1] "-" MHU
  SG_ EASC_Warning_Flag_3 : 14|1@0+ (1,0) [0|1] "-" MHU
  SG_ EASC_Warning_Flag_4 : 15|1@0+ (1,0) [0|1] "-" MHU
  SG_ EASC_Warning_Flag_5 : 16|1@0+ (1,0) [0|1] "-" MHU
  SG_ EASC_Warning_Flag_6 : 17|1@0+ (1,0) [0|1] "-" MHU
  SG_ EASC_Warning_Flag_7 : 18|1@0+ (1,0) [0|1] "-" MHU
  SG_ EASC_Warning_Flag_8 : 19|1@0+ (1,0) [0|1] "-" MHU
  SG_ EASC_Warning_Flag_9 : 20|1@0+ (1,0) [0|1] "-" MHU
  SG_ EASC_Warning_Flag_10 : 21|1@0+ (1,0) [0|1] "-" MHU
  SG_ EASC_Warning_Flag_11 : 22|1@0+ (1,0) [0|1] "-" MHU
  SG_ EASC_Warning_Flag_12 : 23|1@0+ (1,0) [0|1] "-" MHU
  SG_ EASC_Reserved_signal1 : 31|8@0+ (1,0) [0|255] "-" MHU
  SG_ EASC_Reserved_signal2 : 39|8@0+ (1,0) [0|255] "-" MHU
  SG_ EASC_Reserved_signal3 : 47|8@0+ (1,0) [0|255] "-" MHU
  SG_ EASC_Reserved_signal4 : 55|8@0+ (1,0) [0|255] "-" MHU
  SG_ EASC_Reserved_signal5 : 63|8@0+ (1,0) [0|255] "-" MHU

BO_ 1199 CPD_WarnMsg: 8 CPD
  SG_ CHSKM_CPD_WarnMsg : 7|8@0+ (1,0) [0|255] "" MHU
  SG_ ALV_CPD_WarnMsg : 11|4@0+ (1,0) [0|14] "" MHU
  SG_ CPD_Malfunction : 12|1@0+ (1,0) [0|1] "" MHU
  SG_ CPD_SensorFault : 14|2@0+ (1,0) [0|3] "" MHU
  SG_ CPD_Warning_Flag_4 : 15|1@0+ (1,0) [0|1] "" MHU
  SG_ CPD_Warning_Flag_5 : 16|1@0+ (1,0) [0|1] "" MHU
  SG_ CPD_Warning_Flag_6 : 17|1@0+ (1,0) [0|1] "" MHU
  SG_ CPD_Warning_Flag_7 : 18|1@0+ (1,0) [0|1] "" MHU
  SG_ CPD_Warning_Flag_8 : 19|1@0+ (1,0) [0|1] "" MHU
  SG_ CPD_Warning_Flag_9 : 20|1@0+ (1,0) [0|1] "" MHU
  SG_ CPD_Warning_Flag_10 : 21|1@0+ (1,0) [0|1] "" MHU
  SG_ CPD_Warning_Flag_11 : 22|1@0+ (1,0) [0|1] "" MHU
  SG_ CPD_Warning_Flag_12 : 23|1@0+ (1,0) [0|1] "" MHU
  SG_ CPD_Reserved_signal1 : 31|8@0+ (1,0) [0|255] "" MHU
  SG_ CPD_Reserved_signal2 : 39|8@0+ (1,0) [0|255] "" MHU
  SG_ CPD_Reserved_signal3 : 47|8@0+ (1,0) [0|255] "" MHU
  SG_ CPD_Reserved_signal4 : 55|8@0+ (1,0) [0|255] "" MHU
  SG_ CPD_Reserved_signal5 : 63|8@0+ (1,0) [0|255] "" MHU

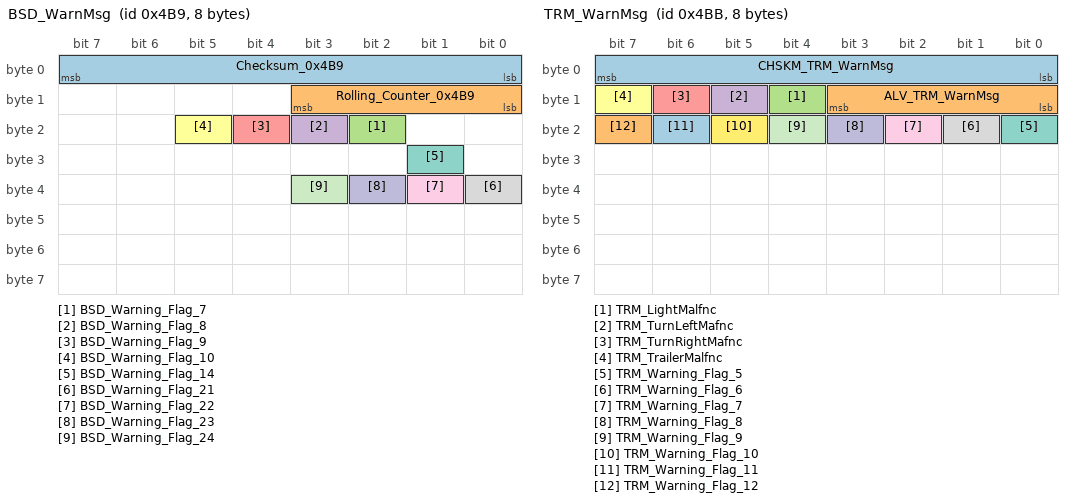
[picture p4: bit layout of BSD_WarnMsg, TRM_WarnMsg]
BO_ 1209 BSD_WarnMsg: 8 XGW_Info
 SG_ Checksum_0x4B9 : 7|8@0+ (1,0) [0|255] "" MHU
 SG_ Rolling_Counter_0x4B9 : 11|4@0+ (1,0) [0|15] "" MHU
 SG_ BSD_Warning_Flag_7 : 18|1@0+ (1,0) [0|1] "" MHU
 SG_ BSD_Warning_Flag_8 : 19|1@0+ (1,0) [0|1] "" MHU
 SG_ BSD_Warning_Flag_9 : 20|1@0+ (1,0) [0|1] "" MHU
 SG_ BSD_Warning_Flag_10 : 21|1@0+ (1,0) [0|1] "" MHU
 SG_ BSD_Warning_Flag_14 : 25|1@0+ (1,0) [0|1] "" MHU
 SG_ BSD_Warning_Flag_21 : 32|1@0+ (1,0) [0|1] "" MHU
 SG_ BSD_Warning_Flag_22 : 33|1@0+ (1,0) [0|1] "" MHU
 SG_ BSD_Warning_Flag_23 : 34|1@0+ (1,0) [0|1] "" MHU
 SG_ BSD_Warning_Flag_24 : 35|1@0+ (1,0) [0|1] "" MHU

BO_ 1211 TRM_WarnMsg: 8 XGW_Info
  SG_ CHSKM_TRM_WarnMsg : 7|8@0+ (1,0) [0|255] "" MHU
  SG_ ALV_TRM_WarnMsg : 11|4@0+ (1,0) [0|14] "" MHU
  SG_ TRM_LightMalfnc : 12|1@0+ (1,0) [0|1] "-" MHU
  SG_ TRM_TurnLeftMafnc : 13|1@0+ (1,0) [0|1] "-" MHU
  SG_ TRM_TurnRightMafnc : 14|1@0+ (1,0) [0|1] "" MHU
  SG_ TRM_TrailerMalfnc : 15|1@0+ (1,0) [0|1] "" MHU
  SG_ TRM_Warning_Flag_5 : 16|1@0+ (1,0) [0|1] "-" MHU
  SG_ TRM_Warning_Flag_6 : 17|1@0+ (1,0) [0|1] "" MHU
  SG_ TRM_Warning_Flag_7 : 18|1@0+ (1,0) [0|1] "" MHU
  SG_ TRM_Warning_Flag_8 : 19|1@0+ (1,0) [0|1] "-" MHU
  SG_ TRM_Warning_Flag_9 : 20|1@0+ (1,0) [0|1] "-" MHU
  SG_ TRM_Warning_Flag_10 : 21|1@0+ (1,0) [0|1] "-" MHU
  SG_ TRM_Warning_Flag_11 : 22|1@0+ (1,0) [0|1] "" MHU
  SG_ TRM_Warning_Flag_12 : 23|1@0+ (1,0) [0|1] "" MHU

BO_ 1213 POD_WarnMsg: 8 XGW_Info
  SG_ CHSKM_POD_WarnMsg : 7|8@0+ (1,0) [0|255] "" MHU
  SG_ ALV_POD_WarnMsg : 11|4@0+ (1,0) [0|14] "" MHU
  SG_ POD_Warning_Flag_1 : 12|1@0+ (1,0) [0|1] "-" MHU
  SG_ POD_Warning_Flag_2 : 13|1@0+ (1,0) [0|1] "-" MHU
  SG_ POD_Warning_Flag_3 : 14|1@0+ (1,0) [0|1] "-" MHU
  SG_ POD_Warning_Flag_4 : 15|1@0+ (1,0) [0|1] "-" MHU
  SG_ POD_Warning_Flag_5 : 16|1@0+ (1,0) [0|1] "-" MHU
  SG_ POD_Warning_Flag_6 : 17|1@0+ (1,0) [0|1] "-" MHU
  SG_ POD_Warning_Flag_7 : 18|1@0+ (1,0) [0|1] "-" MHU
  SG_ POD_Warning_Flag_8 : 19|1@0+ (1,0) [0|1] "-" MHU
  SG_ POD_Warning_Flag_9 : 20|1@0+ (1,0) [0|1] "-" MHU
  SG_ POD_Warning_Flag_10 : 21|1@0+ (1,0) [0|1] "-" MHU
  SG_ POD_Warning_Flag_11 : 22|1@0+ (1,0) [0|1] "-" MHU
  SG_ POD_Warning_Flag_12 : 23|1@0+ (1,0) [0|1] "-" MHU
  SG_ POD_Warning_Flag_13 : 24|1@0+ (1,0) [0|1] "-" MHU
  SG_ POD_Warning_Flag_14 : 25|1@0+ (1,0) [0|1] "-" MHU
  SG_ POD_Warning_Flag_15 : 26|1@0+ (1,0) [0|1] "-" MHU
  SG_ POD_Warning_Flag_16 : 27|1@0+ (1,0) [0|1] "-" MHU
  SG_ POD_Warning_Flag_17 : 28|1@0+ (1,0) [0|1] "-" MHU
  SG_ POD_Warning_Flag_18 : 29|1@0+ (1,0) [0|1] "-" MHU
  SG_ POD_Warning_Flag_19 : 30|1@0+ (1,0) [0|1] "-" MHU
  SG_ POD_Warning_Flag_20 : 31|1@0+ (1,0) [0|1] "-" MHU
  SG_ POD_Warning_Flag_21 : 32|1@0+ (1,0) [0|1] "-" MHU
  SG_ POD_Warning_Flag_22 : 33|1@0+ (1,0) [0|1] "-" MHU
  SG_ POD_Warning_Flag_23 : 34|1@0+ (1,0) [0|1] "-" MHU
  SG_ POD_Warning_Flag_24 : 35|1@0+ (1,0) [0|1] "-" MHU
  SG_ POD_Warning_Flag_25 : 36|1@0+ (1,0) [0|1] "-" MHU
  SG_ POD_Warning_Flag_26 : 37|1@0+ (1,0) [0|1] "-" MHU
  SG_ POD_Warning_Flag_27 : 38|1@0+ (1,0) [0|1] "-" MHU
  SG_ POD_Warning_Flag_28 : 39|1@0+ (1,0) [0|1] "-" MHU
  SG_ POD_Reserved_signal3 : 47|8@0+ (1,0) [0|255] "-" MHU
  SG_ POD_Reserved_signal4 : 55|8@0+ (1,0) [0|255] "-" MHU
  SG_ POD_Reserved_signal5 : 63|8@0+ (1,0) [0|255] "-" MHU

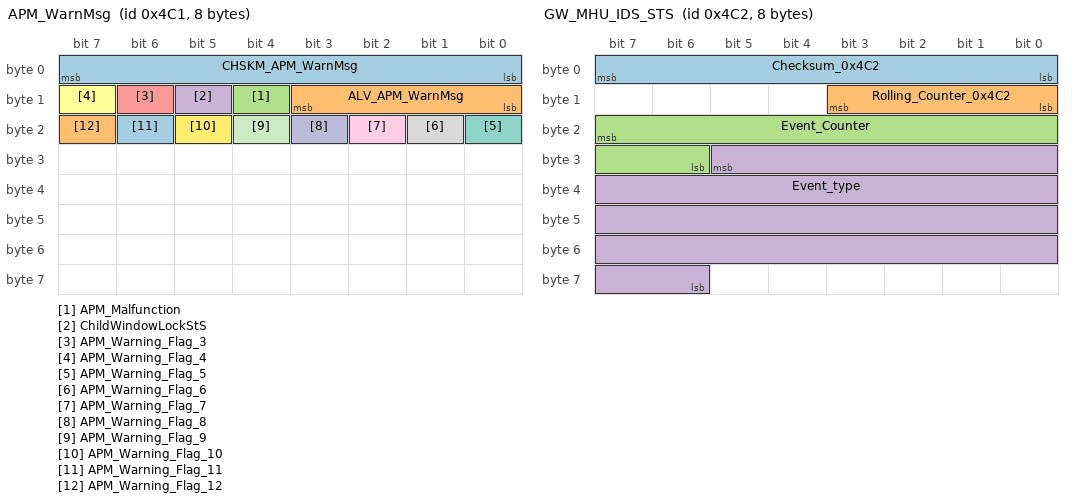
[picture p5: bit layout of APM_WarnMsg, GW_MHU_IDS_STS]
BO_ 1217 APM_WarnMsg: 8 XGW_Info
  SG_ CHSKM_APM_WarnMsg : 7|8@0+ (1,0) [0|255] "" MHU
  SG_ ALV_APM_WarnMsg : 11|4@0+ (1,0) [0|14] "" MHU
  SG_ APM_Malfunction : 12|1@0+ (1,0) [0|1] "" MHU
  SG_ ChildWindowLockStS : 13|1@0+ (1,0) [0|1] "-" MHU
  SG_ APM_Warning_Flag_3 : 14|1@0+ (1,0) [0|1] "" MHU
  SG_ APM_Warning_Flag_4 : 15|1@0+ (1,0) [0|1] "" MHU
  SG_ APM_Warning_Flag_5 : 16|1@0+ (1,0) [0|1] "-" MHU
  SG_ APM_Warning_Flag_6 : 17|1@0+ (1,0) [0|1] "" MHU
  SG_ APM_Warning_Flag_7 : 18|1@0+ (1,0) [0|1] "-" MHU
  SG_ APM_Warning_Flag_8 : 19|1@0+ (1,0) [0|1] "" MHU
  SG_ APM_Warning_Flag_9 : 20|1@0+ (1,0) [0|1] "" MHU
  SG_ APM_Warning_Flag_10 : 21|1@0+ (1,0) [0|1] "" MHU
  SG_ APM_Warning_Flag_11 : 22|1@0+ (1,0) [0|1] "" MHU
  SG_ APM_Warning_Flag_12 : 23|1@0+ (1,0) [0|1] "-" MHU

BO_ 1218 GW_MHU_IDS_STS: 8 XGW_Info
  SG_ Checksum_0x4C2 : 7|8@0+ (1,0) [0|255] "" MHU
  SG_ Rolling_Counter_0x4C2 : 11|4@0+ (1,0) [0|14] "" MHU
  SG_ Event_Counter : 23|10@0+ (1,0) [0|1023] "-" MHU
  SG_ Event_type : 29|32@0+ (1,0) [0|4294967295] "-" MHU

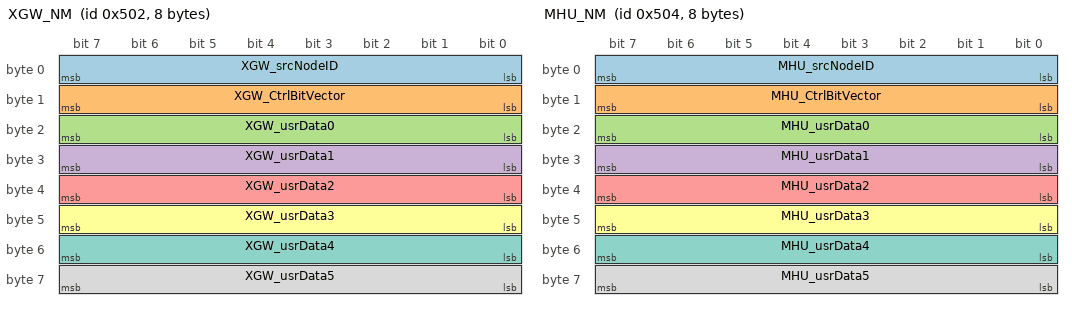
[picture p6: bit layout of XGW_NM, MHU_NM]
BO_ 1282 XGW_NM: 8 XGW_Info
  SG_ XGW_srcNodeID : 7|8@0+ (1,0) [0|255] "" Vector__XXX,CPD,EASC,HUD,MHU,PAS_Info,FCAM_Info
  SG_ XGW_CtrlBitVector : 15|8@0+ (1,0) [0|255] "" Vector__XXX,CPD,EASC,HUD,MHU,PAS_Info,FCAM_Info
  SG_ XGW_usrData0 : 23|8@0+ (1,0) [0|255] "" Vector__XXX,CPD,EASC,HUD,MHU,PAS_Info,FCAM_Info
  SG_ XGW_usrData1 : 31|8@0+ (1,0) [0|255] "" Vector__XXX,CPD,EASC,HUD,MHU,PAS_Info,FCAM_Info
  SG_ XGW_usrData2 : 39|8@0+ (1,0) [0|255] "" Vector__XXX,CPD,EASC,HUD,MHU,PAS_Info,FCAM_Info
  SG_ XGW_usrData3 : 47|8@0+ (1,0) [0|255] "" Vector__XXX,CPD,EASC,HUD,MHU,PAS_Info,FCAM_Info
  SG_ XGW_usrData4 : 55|8@0+ (1,0) [0|255] "" Vector__XXX,CPD,EASC,HUD,MHU,PAS_Info,FCAM_Info
  SG_ XGW_usrData5 : 63|8@0+ (1,0) [0|255] "" Vector__XXX,CPD,EASC,HUD,MHU,PAS_Info,FCAM_Info

BO_ 1284 MHU_NM: 8 MHU
  SG_ MHU_srcNodeID : 7|8@0+ (1,0) [0|255] "-" Vector__XXX,CPD,EASC,HUD,XGW_Info,PAS_Info,FCAM_Info
  SG_ MHU_CtrlBitVector : 15|8@0+ (1,0) [0|255] "-" Vector__XXX,CPD,EASC,HUD,XGW_Info,PAS_Info,FCAM_Info
  SG_ MHU_usrData0 : 23|8@0+ (1,0) [0|255] "-" Vector__XXX,CPD,EASC,HUD,XGW_Info,PAS_Info,FCAM_Info
  SG_ MHU_usrData1 : 31|8@0+ (1,0) [0|255] "-" Vector__XXX,CPD,EASC,HUD,XGW_Info,PAS_Info,FCAM_Info
  SG_ MHU_usrData2 : 39|8@0+ (1,0) [0|255] "-" Vector__XXX,CPD,EASC,HUD,XGW_Info,PAS_Info,FCAM_Info
  SG_ MHU_usrData3 : 47|8@0+ (1,0) [0|255] "-" Vector__XXX,CPD,EASC,HUD,XGW_Info,PAS_Info,FCAM_Info
  SG_ MHU_usrData4 : 55|8@0+ (1,0) [0|255] "-" Vector__XXX,CPD,EASC,HUD,XGW_Info,PAS_Info,FCAM_Info
  SG_ MHU_usrData5 : 63|8@0+ (1,0) [0|255] "-" Vector__XXX,CPD,EASC,HUD,XGW_Info,PAS_Info,FCAM_Info

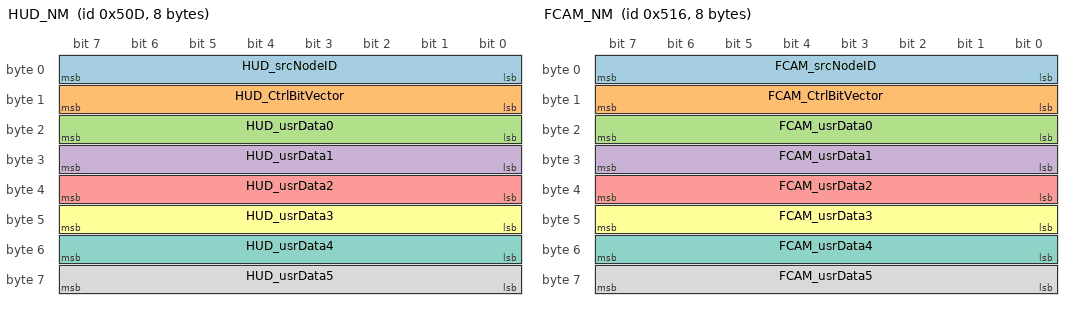
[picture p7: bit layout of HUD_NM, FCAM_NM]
BO_ 1293 HUD_NM: 8 HUD
  SG_ HUD_srcNodeID : 7|8@0+ (1,0) [0|255] "-" Vector__XXX,CPD,EASC,MHU,XGW_Info,PAS_Info,FCAM_Info
  SG_ HUD_CtrlBitVector : 15|8@0+ (1,0) [0|255] "-" Vector__XXX,CPD,EASC,MHU,XGW_Info,PAS_Info,FCAM_Info
  SG_ HUD_usrData0 : 23|8@0+ (1,0) [0|255] "-" Vector__XXX,CPD,EASC,MHU,XGW_Info,PAS_Info,FCAM_Info
  SG_ HUD_usrData1 : 31|8@0+ (1,0) [0|255] "-" Vector__XXX,CPD,EASC,MHU,XGW_Info,PAS_Info,FCAM_Info
  SG_ HUD_usrData2 : 39|8@0+ (1,0) [0|255] "-" Vector__XXX,CPD,EASC,MHU,XGW_Info,PAS_Info,FCAM_Info
  SG_ HUD_usrData3 : 47|8@0+ (1,0) [0|255] "-" Vector__XXX,CPD,EASC,MHU,XGW_Info,PAS_Info,FCAM_Info
  SG_ HUD_usrData4 : 55|8@0+ (1,0) [0|255] "-" Vector__XXX,CPD,EASC,MHU,XGW_Info,PAS_Info,FCAM_Info
  SG_ HUD_usrData5 : 63|8@0+ (1,0) [0|255] "-" CPD,EASC,MHU,XGW_Info,PAS_Info,FCAM_Info

BO_ 1302 FCAM_NM: 8 FCAM_Info
 SG_ FCAM_srcNodeID : 7|8@0+ (1,0) [0|255] ""  CPD,HUD,MHU,PAS_Info,XGW_Info
 SG_ FCAM_CtrlBitVector : 15|8@0+ (1,0) [0|255] ""  CPD,HUD,MHU,PAS_Info,XGW_Info
 SG_ FCAM_usrData0 : 23|8@0+ (1,0) [0|255] ""  CPD,HUD,MHU,PAS_Info,XGW_Info
 SG_ FCAM_usrData1 : 31|8@0+ (1,0) [0|255] ""  CPD,HUD,MHU,PAS_Info,XGW_Info
 SG_ FCAM_usrData2 : 39|8@0+ (1,0) [0|255] ""  CPD,HUD,MHU,PAS_Info,XGW_Info
 SG_ FCAM_usrData3 : 47|8@0+ (1,0) [0|255] ""  CPD,HUD,MHU,PAS_Info,XGW_Info
 SG_ FCAM_usrData4 : 55|8@0+ (1,0) [0|255] ""  CPD,HUD,MHU,PAS_Info,XGW_Info
 SG_ FCAM_usrData5 : 63|8@0+ (1,0) [0|255] ""  CPD,HUD,MHU,PAS_Info,XGW_Info

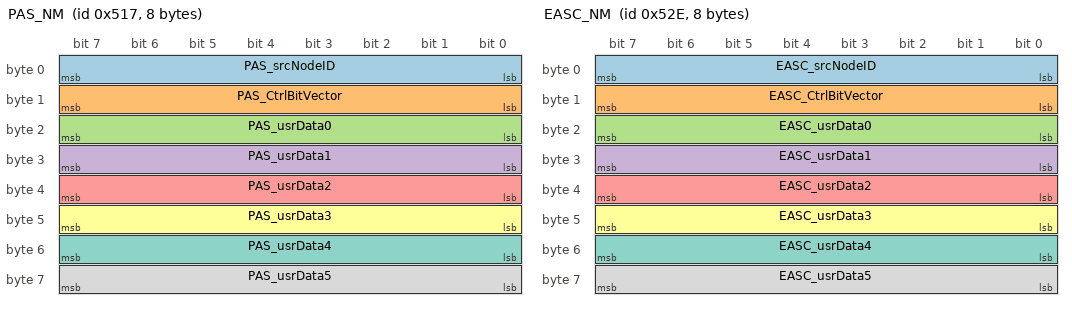
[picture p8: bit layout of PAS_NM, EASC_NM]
BO_ 1303 PAS_NM: 8 PAS_Info
 SG_ PAS_srcNodeID : 7|8@0+ (1,0) [0|255] ""  CPD,FCAM_Info,HUD,MHU,XGW_Info
 SG_ PAS_CtrlBitVector : 15|8@0+ (1,0) [0|255] ""  CPD,FCAM_Info,HUD,MHU,XGW_Info
 SG_ PAS_usrData0 : 23|8@0+ (1,0) [0|255] ""  CPD,FCAM_Info,HUD,MHU,XGW_Info
 SG_ PAS_usrData1 : 31|8@0+ (1,0) [0|255] ""  CPD,FCAM_Info,HUD,MHU,XGW_Info
 SG_ PAS_usrData2 : 39|8@0+ (1,0) [0|255] ""  CPD,FCAM_Info,HUD,MHU,XGW_Info
 SG_ PAS_usrData3 : 47|8@0+ (1,0) [0|255] ""  CPD,FCAM_Info,HUD,MHU,XGW_Info
 SG_ PAS_usrData4 : 55|8@0+ (1,0) [0|255] ""  CPD,FCAM_Info,HUD,MHU,XGW_Info
 SG_ PAS_usrData5 : 63|8@0+ (1,0) [0|255] ""  CPD,FCAM_Info,HUD,MHU,XGW_Info

BO_ 1326 EASC_NM: 8 EASC
  SG_ EASC_srcNodeID : 7|8@0+ (1,0) [0|255] "-" Vector__XXX,CPD,HUD,MHU,XGW_Info
  SG_ EASC_CtrlBitVector : 15|8@0+ (1,0) [0|255] "-" Vector__XXX,CPD,HUD,MHU,XGW_Info
  SG_ EASC_usrData0 : 23|8@0+ (1,0) [0|255] "-" Vector__XXX,CPD,HUD,MHU,XGW_Info
  SG_ EASC_usrData1 : 31|8@0+ (1,0) [0|255] "-" Vector__XXX,CPD,HUD,MHU,XGW_Info
  SG_ EASC_usrData2 : 39|8@0+ (1,0) [0|255] "-" Vector__XXX,CPD,HUD,MHU,XGW_Info
  SG_ EASC_usrData3 : 47|8@0+ (1,0) [0|255] "-" Vector__XXX,CPD,HUD,MHU,XGW_Info
  SG_ EASC_usrData4 : 55|8@0+ (1,0) [0|255] "-" Vector__XXX,CPD,HUD,MHU,XGW_Info
  SG_ EASC_usrData5 : 63|8@0+ (1,0) [0|255] "-" Vector__XXX,CPD,HUD,MHU,XGW_Info

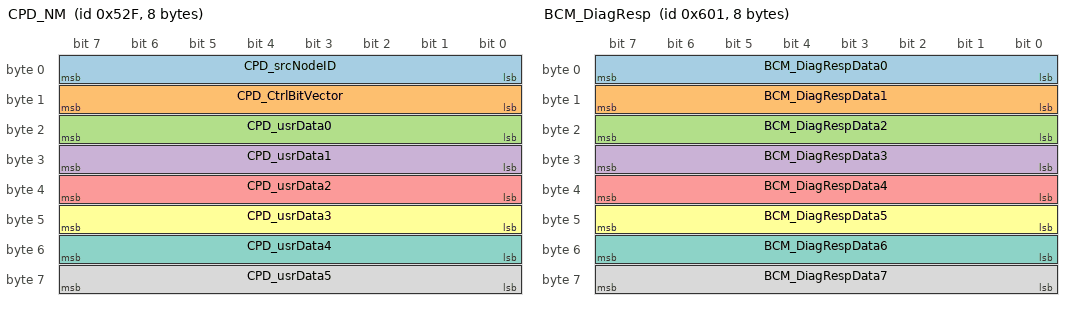
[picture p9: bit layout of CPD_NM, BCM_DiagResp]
BO_ 1327 CPD_NM: 8 CPD
  SG_ CPD_srcNodeID : 7|8@0+ (1,0) [0|255] "-" Vector__XXX,EASC,HUD,MHU,XGW_Info,PAS_Info,FCAM_Info
  SG_ CPD_CtrlBitVector : 15|8@0+ (1,0) [0|255] "-" Vector__XXX,EASC,HUD,MHU,XGW_Info,PAS_Info,FCAM_Info
  SG_ CPD_usrData0 : 23|8@0+ (1,0) [0|255] "-" Vector__XXX,EASC,HUD,MHU,XGW_Info,PAS_Info,FCAM_Info
  SG_ CPD_usrData1 : 31|8@0+ (1,0) [0|255] "-" Vector__XXX,EASC,HUD,MHU,XGW_Info,PAS_Info,FCAM_Info
  SG_ CPD_usrData2 : 39|8@0+ (1,0) [0|255] "-" Vector__XXX,EASC,HUD,MHU,XGW_Info,PAS_Info,FCAM_Info
  SG_ CPD_usrData3 : 47|8@0+ (1,0) [0|255] "-" Vector__XXX,EASC,HUD,MHU,XGW_Info,PAS_Info,FCAM_Info
  SG_ CPD_usrData4 : 55|8@0+ (1,0) [0|255] "-" Vector__XXX,EASC,HUD,MHU,XGW_Info,PAS_Info,FCAM_Info
  SG_ CPD_usrData5 : 63|8@0+ (1,0) [0|255] "-" EASC,HUD,MHU,XGW_Info,PAS_Info,FCAM_Info

BO_ 1537 BCM_DiagResp: 8 XGW_Info
  SG_ BCM_DiagRespData0 : 7|8@0+ (1,0) [0|255] "" MHU
  SG_ BCM_DiagRespData1 : 15|8@0+ (1,0) [0|255] "-" MHU
  SG_ BCM_DiagRespData2 : 23|8@0+ (1,0) [0|255] "" MHU
  SG_ BCM_DiagRespData3 : 31|8@0+ (1,0) [0|255] "" MHU
  SG_ BCM_DiagRespData4 : 39|8@0+ (1,0) [0|255] "" MHU
  SG_ BCM_DiagRespData5 : 47|8@0+ (1,0) [0|255] "" MHU
  SG_ BCM_DiagRespData6 : 55|8@0+ (1,0) [0|255] "-" MHU
  SG_ BCM_DiagRespData7 : 63|8@0+ (1,0) [0|255] "" MHU

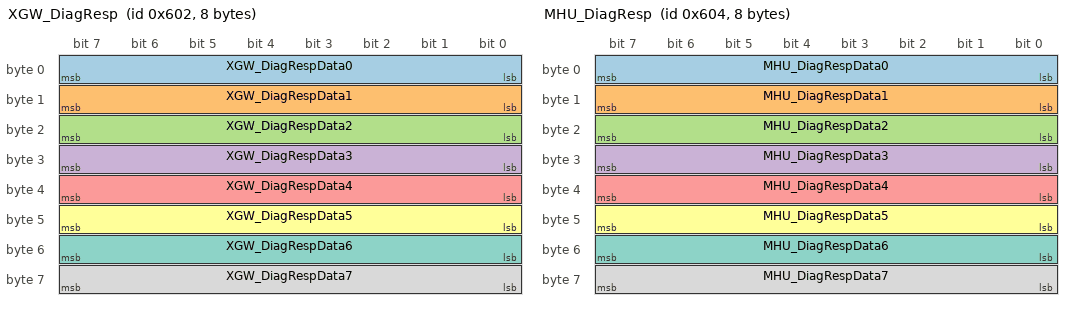
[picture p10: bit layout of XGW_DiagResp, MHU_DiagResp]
BO_ 1538 XGW_DiagResp: 8 XGW_Info
  SG_ XGW_DiagRespData0 : 7|8@0+ (1,0) [0|255] "-" MHU
  SG_ XGW_DiagRespData1 : 15|8@0+ (1,0) [0|255] "-" MHU
  SG_ XGW_DiagRespData2 : 23|8@0+ (1,0) [0|255] "-" MHU
  SG_ XGW_DiagRespData3 : 31|8@0+ (1,0) [0|255] "" MHU
  SG_ XGW_DiagRespData4 : 39|8@0+ (1,0) [0|255] "" MHU
  SG_ XGW_DiagRespData5 : 47|8@0+ (1,0) [0|255] "-" MHU
  SG_ XGW_DiagRespData6 : 55|8@0+ (1,0) [0|255] "" MHU
  SG_ XGW_DiagRespData7 : 63|8@0+ (1,0) [0|255] "-" MHU

BO_ 1540 MHU_DiagResp: 8 MHU
  SG_ MHU_DiagRespData0 : 7|8@0+ (1,0) [0|255] "-" XGW_Info
  SG_ MHU_DiagRespData1 : 15|8@0+ (1,0) [0|255] "-" XGW_Info
  SG_ MHU_DiagRespData2 : 23|8@0+ (1,0) [0|255] "" XGW_Info
  SG_ MHU_DiagRespData3 : 31|8@0+ (1,0) [0|255] "-" XGW_Info
  SG_ MHU_DiagRespData4 : 39|8@0+ (1,0) [0|255] "-" XGW_Info
  SG_ MHU_DiagRespData5 : 47|8@0+ (1,0) [0|255] "-" XGW_Info
  SG_ MHU_DiagRespData6 : 55|8@0+ (1,0) [0|255] "-" XGW_Info
  SG_ MHU_DiagRespData7 : 63|8@0+ (1,0) [0|255] "" XGW_Info

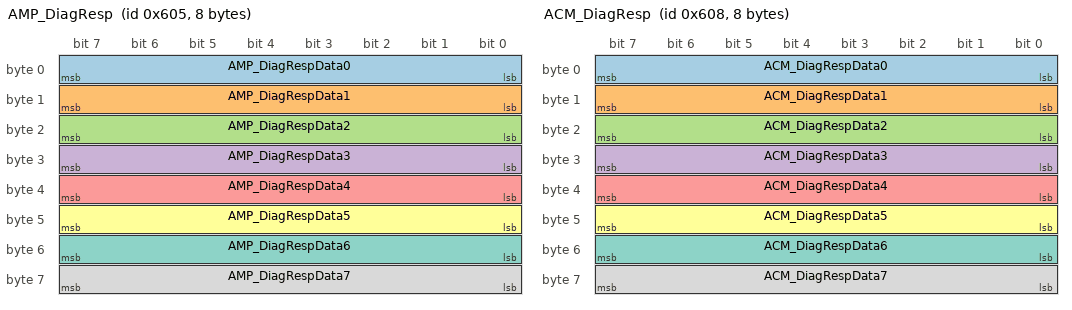
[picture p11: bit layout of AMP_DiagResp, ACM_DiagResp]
BO_ 1541 AMP_DiagResp: 8 AMP
  SG_ AMP_DiagRespData0 : 7|8@0+ (1,0) [0|255] "-" XGW_Info
  SG_ AMP_DiagRespData1 : 15|8@0+ (1,0) [0|255] "-" XGW_Info
  SG_ AMP_DiagRespData2 : 23|8@0+ (1,0) [0|255] "-" XGW_Info
  SG_ AMP_DiagRespData3 : 31|8@0+ (1,0) [0|255] "" XGW_Info
  SG_ AMP_DiagRespData4 : 39|8@0+ (1,0) [0|255] "-" XGW_Info
  SG_ AMP_DiagRespData5 : 47|8@0+ (1,0) [0|255] "" XGW_Info
  SG_ AMP_DiagRespData6 : 55|8@0+ (1,0) [0|255] "" XGW_Info
  SG_ AMP_DiagRespData7 : 63|8@0+ (1,0) [0|255] "-" XGW_Info

BO_ 1544 ACM_DiagResp: 8 XGW_Info
  SG_ ACM_DiagRespData0 : 7|8@0+ (1,0) [0|255] "" MHU
  SG_ ACM_DiagRespData1 : 15|8@0+ (1,0) [0|255] "-" MHU
  SG_ ACM_DiagRespData2 : 23|8@0+ (1,0) [0|255] "" MHU
  SG_ ACM_DiagRespData3 : 31|8@0+ (1,0) [0|255] "-" MHU
  SG_ ACM_DiagRespData4 : 39|8@0+ (1,0) [0|255] "" MHU
  SG_ ACM_DiagRespData5 : 47|8@0+ (1,0) [0|255] "-" MHU
  SG_ ACM_DiagRespData6 : 55|8@0+ (1,0) [0|255] "" MHU
  SG_ ACM_DiagRespData7 : 63|8@0+ (1,0) [0|255] "-" MHU

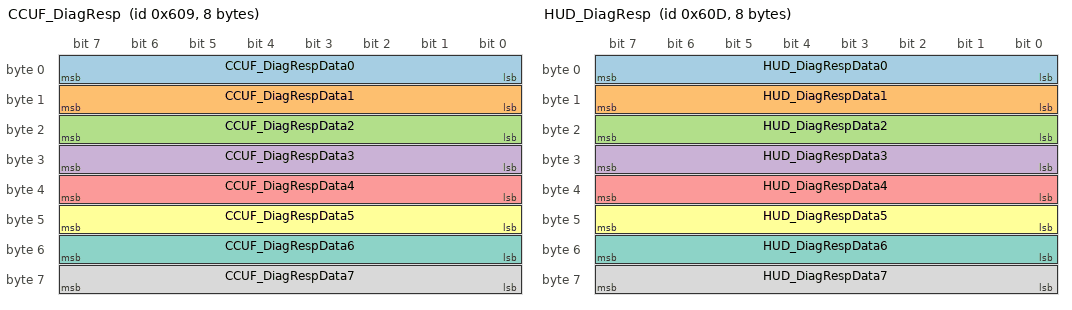
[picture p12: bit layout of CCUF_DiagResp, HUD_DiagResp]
BO_ 1545 CCUF_DiagResp: 8 XGW_Info
  SG_ CCUF_DiagRespData0 : 7|8@0+ (1,0) [0|255] "" MHU
  SG_ CCUF_DiagRespData1 : 15|8@0+ (1,0) [0|255] "-" MHU
  SG_ CCUF_DiagRespData2 : 23|8@0+ (1,0) [0|255] "-" MHU
  SG_ CCUF_DiagRespData3 : 31|8@0+ (1,0) [0|255] "" MHU
  SG_ CCUF_DiagRespData4 : 39|8@0+ (1,0) [0|255] "" MHU
  SG_ CCUF_DiagRespData5 : 47|8@0+ (1,0) [0|255] "-" MHU
  SG_ CCUF_DiagRespData6 : 55|8@0+ (1,0) [0|255] "-" MHU
  SG_ CCUF_DiagRespData7 : 63|8@0+ (1,0) [0|255] "" MHU

BO_ 1549 HUD_DiagResp: 8 HUD
  SG_ HUD_DiagRespData0 : 7|8@0+ (1,0) [0|255] "" XGW_Info
  SG_ HUD_DiagRespData1 : 15|8@0+ (1,0) [0|255] "" XGW_Info
  SG_ HUD_DiagRespData2 : 23|8@0+ (1,0) [0|255] "" XGW_Info
  SG_ HUD_DiagRespData3 : 31|8@0+ (1,0) [0|255] "" XGW_Info
  SG_ HUD_DiagRespData4 : 39|8@0+ (1,0) [0|255] "-" XGW_Info
  SG_ HUD_DiagRespData5 : 47|8@0+ (1,0) [0|255] "" XGW_Info
  SG_ HUD_DiagRespData6 : 55|8@0+ (1,0) [0|255] "-" XGW_Info
  SG_ HUD_DiagRespData7 : 63|8@0+ (1,0) [0|255] "" XGW_Info

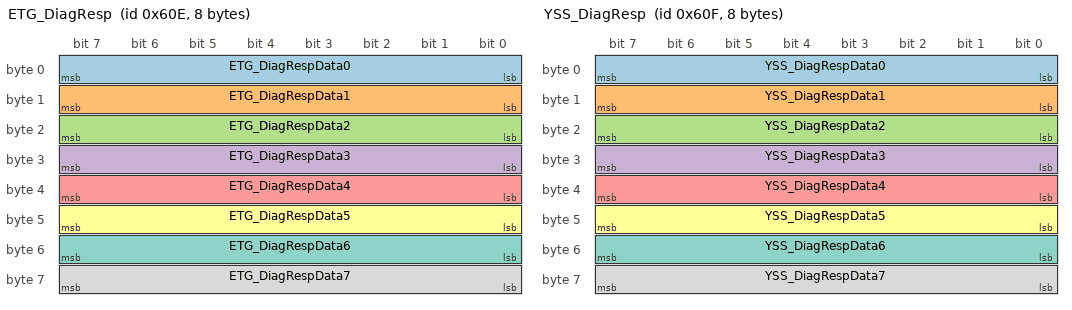
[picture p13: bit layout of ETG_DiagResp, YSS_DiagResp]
BO_ 1550 ETG_DiagResp: 8 XGW_Info
  SG_ ETG_DiagRespData0 : 7|8@0+ (1,0) [0|255] "" MHU
  SG_ ETG_DiagRespData1 : 15|8@0+ (1,0) [0|255] "" MHU
  SG_ ETG_DiagRespData2 : 23|8@0+ (1,0) [0|255] "" MHU
  SG_ ETG_DiagRespData3 : 31|8@0+ (1,0) [0|255] "-" MHU
  SG_ ETG_DiagRespData4 : 39|8@0+ (1,0) [0|255] "" MHU
  SG_ ETG_DiagRespData5 : 47|8@0+ (1,0) [0|255] "" MHU
  SG_ ETG_DiagRespData6 : 55|8@0+ (1,0) [0|255] "" MHU
  SG_ ETG_DiagRespData7 : 63|8@0+ (1,0) [0|255] "" MHU

BO_ 1551 YSS_DiagResp: 8 XGW_Info
  SG_ YSS_DiagRespData0 : 7|8@0+ (1,0) [0|255] "" MHU
  SG_ YSS_DiagRespData1 : 15|8@0+ (1,0) [0|255] "" MHU
  SG_ YSS_DiagRespData2 : 23|8@0+ (1,0) [0|255] "-" MHU
  SG_ YSS_DiagRespData3 : 31|8@0+ (1,0) [0|255] "" MHU
  SG_ YSS_DiagRespData4 : 39|8@0+ (1,0) [0|255] "" MHU
  SG_ YSS_DiagRespData5 : 47|8@0+ (1,0) [0|255] "" MHU
  SG_ YSS_DiagRespData6 : 55|8@0+ (1,0) [0|255] "" MHU
  SG_ YSS_DiagRespData7 : 63|8@0+ (1,0) [0|255] "" MHU

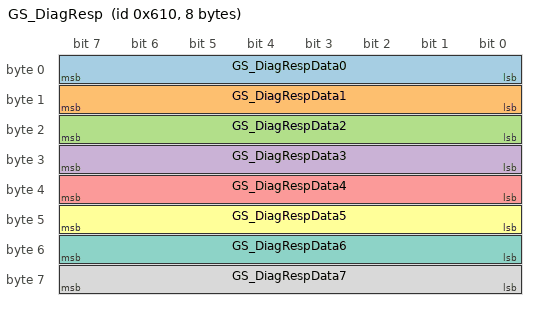
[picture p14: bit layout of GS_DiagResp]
BO_ 1552 GS_DiagResp: 8 XGW_Info
  SG_ GS_DiagRespData0 : 7|8@0+ (1,0) [0|255] "-" MHU
  SG_ GS_DiagRespData1 : 15|8@0+ (1,0) [0|255] "" MHU
  SG_ GS_DiagRespData2 : 23|8@0+ (1,0) [0|255] "-" MHU
  SG_ GS_DiagRespData3 : 31|8@0+ (1,0) [0|255] "" MHU
  SG_ GS_DiagRespData4 : 39|8@0+ (1,0) [0|255] "" MHU
  SG_ GS_DiagRespData5 : 47|8@0+ (1,0) [0|255] "" MHU
  SG_ GS_DiagRespData6 : 55|8@0+ (1,0) [0|255] "-" MHU
  SG_ GS_DiagRespData7 : 63|8@0+ (1,0) [0|255] "" MHU

CM_ BO_ 1153 "BCM Warn Msg";
CM_ BO_ 1154 "XGW WarnMsg";
CM_ BO_ 1155 "TPMS TirePressure";
CM_ BO_ 1156 "APA FEEDBACK MHU ";
CM_ BO_ 1160 "ACM WarnMsg";
CM_ BO_ 1161 "CCU WarnMsg";
CM_ BO_ 1165 "HUD WarnMsg";
CM_ BO_ 1166 "ETG WarnMsg";
CM_ BO_ 1168 "GS Warning message";
CM_ BO_ 1171 "BMS Warning message";
CM_ BO_ 1178 "EDS Rear Warning message";
CM_ BO_ 1179 "EDS Front Warning message";
CM_ BO_ 1191 "RCU warning message";
CM_ BO_ 1192 "EPS warning message";
CM_ BO_ 1193 "IDB warning message";
CM_ BO_ 1196 "VCU Warning message";
CM_ BO_ 1198 "EASC WarnMsg";
CM_ BO_ 1199 "CPD WarnMsg";
CM_ BO_ 1209  "BSD WarnMsg";
CM_ BO_ 1211 "TRM WarnMsg";
CM_ BO_ 1213 "POD WarnMsg";
CM_ BO_ 1217 "APM WarnMsg";
CM_ BO_ 1218 "TRANSFERING LOGS BETWEEN XGW TBOX";
CM_ BO_ 1282 "XGW Network Management";
CM_ BO_ 1284 "MHU NM";
CM_ BO_ 1293 "HUD NM";
CM_ BO_ 1303 "PAS Network Management";
CM_ BO_ 1326 "EASC NM";
CM_ BO_ 1327 "CPD NM";
CM_ BO_ 1537 "BCM DiagResp";
CM_ BO_ 1538 "XGW DiagResp";
CM_ BO_ 1540 "MHU DiagResp";
CM_ BO_ 1541 "Diagnostic Response for AMP ";
CM_ BO_ 1544 "ACM DiagResp";
CM_ BO_ 1545 "CCU DiagResp";
CM_ BO_ 1549 "HUD DiagResp";
CM_ BO_ 1550 "ETG DiagResp";
CM_ BO_ 1551 "Diagnostic Response for YSS     ";
CM_ BO_ 1552 "GS Diagnostic Responde";
CM_ SG_ 1153 CHSKM_BCM_WarnMsg "Checksum BCM Warning Message";
CM_ SG_ 1153 ALV_BCM_WarnMsg "Alive counter";
CM_ SG_ 1153 BCM_NoValidKey_2 "Key FOBs are not in the car";
CM_ SG_ 1153 BCM_WrongGearPosToStart "Gear position is not P/N, Gear in wrong position to start";
CM_ SG_ 1153 BCM_SSB_defect "SSB button defect";
CM_ SG_ 1153 BCM_NoValidKey_1 "Illegal key in the car";
CM_ SG_ 1153 BCM_CHMLS_Defect "CHMSL defect";
CM_ SG_ 1153 BCM_PositionLightDefect "Position light defect";
CM_ SG_ 1153 BCM_HighBeamDefect "High beam defect";
CM_ SG_ 1153 BCM_LowBeamDefect "Low beam defect";
CM_ SG_ 1153 BCM_StopLightDefect "Stop light defect";
CM_ SG_ 1153 BCM_KeyFob_LowBattery "Keyfob battery low";
CM_ SG_ 1153 BCM_TurnOffPosLightRemindr "Driver forget to turn off Position Lights during leaving car";
CM_ SG_ 1153 BCM_PressBrakeToStart "Brake padel not pressed to start the car";
CM_ SG_ 1153 BCM_12VBattery_Discharging "12V battery discharging";
CM_ SG_ 1153 BCM_ForgetKeyFOBInCar "Locking the car when the key in the car";
CM_ SG_ 1153 BCM_12VBattery_LowLevel "Low level 12V Battery";
CM_ SG_ 1153 BCM_RLS_Malfunction "Rain/Light sensor malfunction";
CM_ SG_ 1153 BCM_ReverseLightDefect "Reverse lamp defect";
CM_ SG_ 1153 BCM_RearFog_Defect "Rear fog lamp defect";
CM_ SG_ 1153 BCM_FrontFog_Defect "Front fog lamp defect";
CM_ SG_ 1153 BCM_LicencePlateLight_Defect "License plate light defect";
CM_ SG_ 1153 BCM_dTPMS_LowBattery "TPMS sensor Low battery";
CM_ SG_ 1153 BCM_dTPMS_HighPressure "High tire pressure";
CM_ SG_ 1153 BCM_dTPMS_HighTemperature "High tire temperature";
CM_ SG_ 1153 BCM_dTPMS_RapidLeak "Rapid air leak alarm";
CM_ SG_ 1153 BCM_dTPMS_LowPressure "Low tire pressure";
CM_ SG_ 1153 BCM_dTPMS_Malfunc_LostSensor "TPMS Malfunction, Lost sensor alarm";
CM_ SG_ 1153 BCM_dTPMS_Malfunc "TPMS malfunction";
CM_ SG_ 1153 BCM_TurnIndicatorDefect "Turn indicator defect";
CM_ SG_ 1153 BCM_Keyfob_Leftcar "Keyfob left the car warning";
CM_ SG_ 1153 BCM_FrontLeftDoorLockDefect "FrontLeftDoorLock Fail";
CM_ SG_ 1153 BCM_Front_RightDoorLockDefect "FrontRightDoorLock Fail";
CM_ SG_ 1153 BCM_RearLeftDoorLockDefect "BCM rearLeft door fail";
CM_ SG_ 1153 BCM_Rear_RightDoorLockDefect "BCM RearDoor Fail";
CM_ SG_ 1153 BCM_FrontWiperDefect "Front wiper Fail";
CM_ SG_ 1153 BCM_CrashSignalDefect "Crash Unlcokxa0Signalxa0error";
CM_ SG_ 1153 BCM_SCM_Malfunction "SCM Malfunction";
CM_ SG_ 1153 BCM_RLT_Malfunction "Tailgate ligth driver module Malfunction";
CM_ SG_ 1153 BCM_RLBR_Malfunction "Rear right ligth driver module Malfunction";
CM_ SG_ 1153 BCM_RLBL_Malfunction "Rear left ligth driver module Malfunction";
CM_ SG_ 1153 BCM_LDMR_Malfunction "Rear right ligth driver module Malfunction";
CM_ SG_ 1153 BCM_LDML_Malfunction "Front right ligth driver module Malfunction";
CM_ SG_ 1153 BCM_AutoHLLevelingFault "Auto headlamp leveling fault";
CM_ SG_ 1154 CHSKM_XGW_WarnMsg "Checksum";
CM_ SG_ 1154 ALV_XGW_WarnMsg "Alive Counter";
CM_ SG_ 1154 XGW_AutoHLLevelingFault "Auto leveling malfunction: Front/rear height sensor fault or front left/right headlamp motor fault.";
CM_ SG_ 1154 XGW_WasherFluidLvlSw "Washer fluid is low";
CM_ SG_ 1154 XGW_Warning_Flag_3 "Warning Message Flag, Component owner, Supplier align and define for this signal";
CM_ SG_ 1154 XGW_Warning_Flag_4 "Warning Message Flag, Component owner, Supplier align and define for this signal";
CM_ SG_ 1154 XGW_Warning_Flag_5 "Warning Message Flag, Component owner, Supplier align and define for this signal";
CM_ SG_ 1154 XGW_Warning_Flag_6 "Warning Message Flag, Component owner, Supplier align and define for this signal";
CM_ SG_ 1154 XGW_Warning_Flag_7 "Warning Message Flag, Component owner, Supplier align and define for this signal";
CM_ SG_ 1154 XGW_Warning_Flag_8 "Warning Message Flag, Component owner, Supplier align and define for this signal";
CM_ SG_ 1154 XGW_Warning_Flag_9 "Warning Message Flag, Component owner, Supplier align and define for this signal";
CM_ SG_ 1154 XGW_Warning_Flag_10 "Warning Message Flag, Component owner, Supplier align and define for this signal";
CM_ SG_ 1154 XGW_Warning_Flag_11 "Warning Message Flag, Component owner, Supplier align and define for this signal";
CM_ SG_ 1154 XGW_Warning_Flag_12 "Warning Message Flag, Component owner, Supplier align and define for this signal";
CM_ SG_ 1154 XGW_Reserved_signal1 "Warning Message Flag, Component owner, Supplier align and define for this signal";
CM_ SG_ 1154 XGW_Reserved_signal2 "Warning Message Flag, Component owner, Supplier align and define for this signal";
CM_ SG_ 1154 XGW_Reserved_signal3 "Warning Message Flag, Component owner, Supplier align and define for this signal";
CM_ SG_ 1154 XGW_Reserved_signal4 "Warning Message Flag, Component owner, Supplier align and define for this signal";
CM_ SG_ 1154 XGW_Reserved_signal5 "Warning Message Flag, Component owner, Supplier align and define for this signal";
CM_ SG_ 1155 TPMS_FLTirePress "Front left tire pressure signal";
CM_ SG_ 1155 TPMS_FRTirePress "Front right tire pressure signal";
CM_ SG_ 1155 TPMS_RLTirePress "Rear left tire pressure signal";
CM_ SG_ 1155 TPMS_RRTirePress "Rear right tire pressure signal";
CM_ SG_ 1155 TPMS_FLTirePressAlarm "Front left tire pressure alarm  signal";
CM_ SG_ 1155 TPMS_FRTirePressAlarm "Front right tire pressure alarm signal";
CM_ SG_ 1155 TPMS_RLTirePressAlarm "Rear left tire pressure alarm signal";
CM_ SG_ 1155 TPMS_RRTirePressAlarm "Rear right tire pressure alarm signal";
CM_ SG_ 1155 TPMS_TirePosition "Tire position signal";
CM_ SG_ 1155 TPMS_ready2learning "BCM feedback signal ready to learning";
CM_ SG_ 1155 TPMS_TireTempAlarm "Tire temperature alarm signal";
CM_ SG_ 1155 TPMS_LearningStatus "BCM feedback signal for learning status";
CM_ SG_ 1155 TPMS_TireTemp "Tire temperature signal";
CM_ SG_ 1156 CHKSM_APA_FEEDBACK_MHU "Checksum";
CM_ SG_ 1156 ALV_APA_FEEDBACK_MHU "Alive Counter";
CM_ SG_ 1156 APA_ReqInfoDispTxt3 "Parking process abnormal reminder";
CM_ SG_ 1156 APA_ReqInfoDispTxt4 "searching progress  infomation reminder";
CM_ SG_ 1156 APA_ReqInfoDispTxt2 "Parking process text reminder";
CM_ SG_ 1156 APA_ReqInfoDispTxt1 "APA function mode request feedback";
CM_ SG_ 1156 APA_MHU_Displayparkingtype "APA request MHU display function select interface";
CM_ SG_ 1156 APA_FuncModeFdbck "APA function mode request feedback";
CM_ SG_ 1156 APA_RecommendSlotID "APA_Recommend Slot";
CM_ SG_ 1156 APA_Currentfunction "FAPA current running sub-function";
CM_ SG_ 1156 APA_MHU_Status "APA_Status";
CM_ SG_ 1157 TBOX_RPADirSel "Remote Parking Direction Selection: During remote parking, the user clicks the available parking direction displayed on the APP for selection, and TBOX forwards TBOX_RPADirSel to ANRC to feedback the specific parking direction selected by the user. ANRC feeds back the user's choice of direction signals sent by the APP
";
CM_ SG_ 1158 CHKSM_TirePressAlarm "Checksum";
CM_ SG_ 1158 ALV_TirePressAlarm "Alive Counter";
CM_ SG_ 1158 TPMS_FLTirePressAlarm2 "Front left tire pressure alarm  signal";
CM_ SG_ 1158 TPMS_FRTirePressAlarm2 "Front right tire pressure alarm signal";
CM_ SG_ 1158 TPMS_RLTirePressAlarm2 "Rear left tire pressure alarm signal";
CM_ SG_ 1158 TPMS_RRTirePressAlarm2 "Rear right tire pressure alarm signal";
CM_ SG_ 1160 CHKSM_ACM_WARNING_MSG "Checksum for ACM warning message";
CM_ SG_ 1160 ALV_ACM_WARNING_MSG "Alive counter for ACM warning message";
CM_ SG_ 1160 ACM_Malfunction "ACM Malfunction (trigger airbag warning lamp)";
CM_ SG_ 1160 ACM_Pre_Drive_Check "ACM status after pre-drive check (trigger airbag warning lamp if any failure) ";
CM_ SG_ 1160 ACM_in_Plant_Mode "ACM plant mode status (trigger airbag warning lamp) ";
CM_ SG_ 1160 ACM_PAB_Suppression "ACM suppress passenger airbag (front AB 1st stage, front AB 2nd stage, knee AB). This is used to trigger PAB indicator in MHU's display. ";
CM_ SG_ 1160 ACM_Airbag_Disabled "ACM airbag disabled status due to Algo disabled or Firing disabled due to diagnostic or inert calibration file is flashed (trigger Airbag warning lamp when airbag is disabled)";
CM_ SG_ 1160 ACM_Development_Calibration "ACM calibration file status indicate whether ACM is flashed with calibration file for development purpose only (trigger Airbag warning lamp and chime when ACM is flashed with development calibration file)";
CM_ SG_ 1160 ACM_In_Disposal_Mode "ACM disposal mode status (trigger airbag warning lamp when ACM in disposal mode)";
CM_ SG_ 1160 ACM_Seatbelt_Reminder_Request "ACM request seatbelt reminder (1 signal for whole front and rear seats)";
CM_ SG_ 1160 ACM_SBR_Chime_Req "ACM request chime to MHU for seatbelt reminder front row";
CM_ SG_ 1160 ACM_SBR_Blinking_Req "ACM send blinking request to MHU (trigger blinking of seatbelt reminder lamp)";
CM_ SG_ 1161 CHSKM_CCU_WarnMsg "Checksum";
CM_ SG_ 1161 ALV_CCU_WarnMsg "Alive Counter";
CM_ SG_ 1161 CCU_Malfunction "Warning Message Flag, Component owner, Supplier align and define for this signal";
CM_ SG_ 1161 CCU_Warning_Flag_2 "Warning Message Flag, Component owner, Supplier align and define for this signal";
CM_ SG_ 1161 CCU_Warning_Flag_3 "Warning Message Flag, Component owner, Supplier align and define for this signal";
CM_ SG_ 1161 CCU_Warning_Flag_4 "Warning Message Flag, Component owner, Supplier align and define for this signal";
CM_ SG_ 1161 CCU_Warning_Flag_5 "Warning Message Flag, Component owner, Supplier align and define for this signal";
CM_ SG_ 1161 CCU_Warning_Flag_6 "Warning Message Flag, Component owner, Supplier align and define for this signal";
CM_ SG_ 1161 CCU_Warning_Flag_7 "Warning Message Flag, Component owner, Supplier align and define for this signal";
CM_ SG_ 1161 CCU_Warning_Flag_8 "Warning Message Flag, Component owner, Supplier align and define for this signal";
CM_ SG_ 1161 CCU_Warning_Flag_9 "Warning Message Flag, Component owner, Supplier align and define for this signal";
CM_ SG_ 1161 CCU_Warning_Flag_10 "Warning Message Flag, Component owner, Supplier align and define for this signal";
CM_ SG_ 1161 CCU_Warning_Flag_11 "Warning Message Flag, Component owner, Supplier align and define for this signal";
CM_ SG_ 1161 CCU_Warning_Flag_12 "Warning Message Flag, Component owner, Supplier align and define for this signal";
CM_ SG_ 1165 CHSKM_HUD_WarnMsg "Checksum";
CM_ SG_ 1165 ALV_HUD_WarnMsg "Alive Counter";
CM_ SG_ 1165 HUD_Malfunction "HUD defect - need to replace";
CM_ SG_ 1165 HUD_Failed_Temporary "HUD temporary unavailable";
CM_ SG_ 1165 HUD_Overheating "HUD overheating - temporary unavailable";
CM_ SG_ 1165 HUD_Warning_Flag_4 "Warning Message Flag, Component owner, Supplier align and define for this signal";
CM_ SG_ 1165 HUD_Warning_Flag_5 "Warning Message Flag, Component owner, Supplier align and define for this signal";
CM_ SG_ 1165 HUD_Warning_Flag_6 "Warning Message Flag, Component owner, Supplier align and define for this signal";
CM_ SG_ 1165 HUD_Warning_Flag_7 "Warning Message Flag, Component owner, Supplier align and define for this signal";
CM_ SG_ 1165 HUD_Warning_Flag_8 "Warning Message Flag, Component owner, Supplier align and define for this signal";
CM_ SG_ 1165 HUD_Warning_Flag_9 "Warning Message Flag, Component owner, Supplier align and define for this signal";
CM_ SG_ 1165 HUD_Warning_Flag_10 "Warning Message Flag, Component owner, Supplier align and define for this signal";
CM_ SG_ 1165 HUD_Warning_Flag_11 "Warning Message Flag, Component owner, Supplier align and define for this signal";
CM_ SG_ 1165 HUD_Warning_Flag_12 "Warning Message Flag, Component owner, Supplier align and define for this signal";
CM_ SG_ 1165 SECCAN_HUDWarn "Seed portion from Secure CAN algorithm";
CM_ SG_ 1166 CHSKM_ETG_WarnMsg "Checksum";
CM_ SG_ 1166 ALV_ETG_WarnMsg "Alive Counter";
CM_ SG_ 1166 ETG_Malfunction "ETG_Malfunction";
CM_ SG_ 1166 ETG_Warning_Flag_2 "Warning Message Flag, Component owner, Supplier align and define for this signal";
CM_ SG_ 1166 ETG_Warning_Flag_3 "Warning Message Flag, Component owner, Supplier align and define for this signal";
CM_ SG_ 1166 ETG_Warning_Flag_4 "Warning Message Flag, Component owner, Supplier align and define for this signal";
CM_ SG_ 1166 ETG_Warning_Flag_5 "Warning Message Flag, Component owner, Supplier align and define for this signal";
CM_ SG_ 1166 ETG_Warning_Flag_6 "Warning Message Flag, Component owner, Supplier align and define for this signal";
CM_ SG_ 1166 ETG_Warning_Flag_7 "Warning Message Flag, Component owner, Supplier align and define for this signal";
CM_ SG_ 1166 ETG_Warning_Flag_8 "Warning Message Flag, Component owner, Supplier align and define for this signal";
CM_ SG_ 1166 ETG_Warning_Flag_9 "Warning Message Flag, Component owner, Supplier align and define for this signal";
CM_ SG_ 1166 ETG_Warning_Flag_10 "Warning Message Flag, Component owner, Supplier align and define for this signal";
CM_ SG_ 1166 ETG_Warning_Flag_11 "Warning Message Flag, Component owner, Supplier align and define for this signal";
CM_ SG_ 1166 ETG_Warning_Flag_12 "Warning Message Flag, Component owner, Supplier align and define for this signal";
CM_ SG_ 1168 CHSKM_GS_WarnMsg "Checksum";
CM_ SG_ 1168 ALV_GS_WarnMsg "Alive Counter";
CM_ SG_ 1168 GS_Warning_Flag_1 "P BUTTON FAULT ERROR";
CM_ SG_ 1168 GS_Warning_Flag_2 "R BUTTON FAULT ERROR";
CM_ SG_ 1168 GS_Warning_Flag_3 "N BUTTON FAULT ERROR";
CM_ SG_ 1168 GS_Warning_Flag_4 "D BUTTON FAULT ERROR";
CM_ SG_ 1168 GS_Warning_Flag_5 "P BUTTON STUCK FAULT ERROR";
CM_ SG_ 1168 GS_Warning_Flag_6 "R BUTTON STUCK FAULT ERROR";
CM_ SG_ 1168 GS_Warning_Flag_7 "N BUTTON STUCK FAULT ERROR";
CM_ SG_ 1168 GS_Warning_Flag_8 "D BUTTON STUCK FAULT ERROR";
CM_ SG_ 1168 GS_Warning_Flag_9 "Warning Message Flag, Component owner, Supplier align and define for this signal";
CM_ SG_ 1168 GS_Warning_Flag_10 "Warning Message Flag, Component owner, Supplier align and define for this signal";
CM_ SG_ 1168 GS_Warning_Flag_11 "Warning Message Flag, Component owner, Supplier align and define for this signal";
CM_ SG_ 1168 GS_Warning_Flag_12 "Warning Message Flag, Component owner, Supplier align and define for this signal";
CM_ SG_ 1168 GS_Reserved_signal1 "Warning Message Flag, Component owner, Supplier align and define for this signal";
CM_ SG_ 1168 GS_Reserved_signal2 "Warning Message Flag, Component owner, Supplier align and define for this signal";
CM_ SG_ 1168 GS_Reserved_signal3 "Warning Message Flag, Component owner, Supplier align and define for this signal";
CM_ SG_ 1168 GS_Reserved_signal4 "Warning Message Flag, Component owner, Supplier align and define for this signal";
CM_ SG_ 1168 GS_Reserved_signal5 "Warning Message Flag, Component owner, Supplier align and define for this signal";
CM_ SG_ 1171 CHSKM_BMS_WarnMsg "Checksum";
CM_ SG_ 1171 ALV_BMS_WarnMsg "Alive Counter";
CM_ SG_ 1171 BMS_PackTempSts "Pack temperature warning";
CM_ SG_ 1171 BMS_ThermalRunaway "Thermal runaway warning";
CM_ SG_ 1171 BMS_BatteryReplacement "Separate signal to indicate the battery replacement information(Battery replacement MHU)";
CM_ SG_ 1171 BMS_Warning_PowerDegrade "Pack Power Degrade: Battery is cold & limited capacity, please charge";
CM_ SG_ 1171 BMS_Warning_DeltaSoC "EV Battery Delta SOC is high, range reduction in vehicle will be absorbed
";
CM_ SG_ 1171 BMS_Warning_HVILSts "HVIL warning signal
";
CM_ SG_ 1171 BMS_Warning_Isolation "Coolant Leakage warning";
CM_ SG_ 1171 BMS_Warning_CoolantLeakage "Coolant Leakage warning
";
CM_ SG_ 1171 BMS_MalfunctionSts "Malfunction status of battery for MHU display";
CM_ SG_ 1171 BMS_LowBattery "Low Battery Warning";
CM_ SG_ 1171 BMS_Warning_DeltaTemperature "Delta temperature warning signal";
CM_ SG_ 1171 BMS_Warning_BDUTemperatureSts "BDU temperature warning signal";
CM_ SG_ 1171 BMS_Warning_Contactor_Aging "Contactor Aging Warning";
CM_ SG_ 1171 BMS_Reserved_signal4 "Warning Message Flag, Component owner, Supplier align and define for this signal";
CM_ SG_ 1171 BMS_Reserved_signal5 "Warning Message Flag, Component owner, Supplier align and define for this signal";
CM_ SG_ 1178 CHSKM_EDS_R_WarnMsg "Checksum";
CM_ SG_ 1178 ALV_EDS_R_WarnMsg "Alive Counter";
CM_ SG_ 1178 EDS_R_Warning_Flag_1 "Warning Message Flag, Component owner, Supplier align and define for this signal";
CM_ SG_ 1178 EDS_R_Warning_Flag_2 "Warning Message Flag, Component owner, Supplier align and define for this signal";
CM_ SG_ 1178 EDS_R_Warning_Flag_3 "Warning Message Flag, Component owner, Supplier align and define for this signal";
CM_ SG_ 1178 EDS_R_Warning_Flag_4 "Warning Message Flag, Component owner, Supplier align and define for this signal";
CM_ SG_ 1178 EDS_R_Warning_Flag_5 "Warning Message Flag, Component owner, Supplier align and define for this signal";
CM_ SG_ 1178 EDS_R_Warning_Flag_6 "Warning Message Flag, Component owner, Supplier align and define for this signal";
CM_ SG_ 1178 EDS_R_Warning_Flag_7 "Warning Message Flag, Component owner, Supplier align and define for this signal";
CM_ SG_ 1178 EDS_R_Warning_Flag_8 "Warning Message Flag, Component owner, Supplier align and define for this signal";
CM_ SG_ 1178 EDS_R_Warning_Flag_9 "Warning Message Flag, Component owner, Supplier align and define for this signal";
CM_ SG_ 1178 EDS_R_Warning_Flag_10 "Warning Message Flag, Component owner, Supplier align and define for this signal";
CM_ SG_ 1178 EDS_R_Warning_Flag_11 "Warning Message Flag, Component owner, Supplier align and define for this signal";
CM_ SG_ 1178 EDS_R_Warning_Flag_12 "Warning Message Flag, Component owner, Supplier align and define for this signal";
CM_ SG_ 1178 EDS_R_Reserved_signal1 "Warning Message Flag, Component owner, Supplier align and define for this signal";
CM_ SG_ 1178 EDS_R_Reserved_signal2 "Warning Message Flag, Component owner, Supplier align and define for this signal";
CM_ SG_ 1178 EDS_R_Reserved_signal3 "Warning Message Flag, Component owner, Supplier align and define for this signal";
CM_ SG_ 1178 EDS_R_Reserved_signal4 "Warning Message Flag, Component owner, Supplier align and define for this signal";
CM_ SG_ 1178 EDS_R_Reserved_signal5 "Warning Message Flag, Component owner, Supplier align and define for this signal";
CM_ SG_ 1179 CHSKM_EDS_F_WarnMsg "Checksum";
CM_ SG_ 1179 ALV_EDS_F_WarnMsg "Alive Counter";
CM_ SG_ 1179 EDS_F_Warning_Flag_1 "Warning Message Flag, Component owner, Supplier align and define for this signal";
CM_ SG_ 1179 EDS_F_Warning_Flag_2 "Warning Message Flag, Component owner, Supplier align and define for this signal";
CM_ SG_ 1179 EDS_F_Warning_Flag_3 "Warning Message Flag, Component owner, Supplier align and define for this signal";
CM_ SG_ 1179 EDS_F_Warning_Flag_4 "Warning Message Flag, Component owner, Supplier align and define for this signal";
CM_ SG_ 1179 EDS_F_Warning_Flag_5 "Warning Message Flag, Component owner, Supplier align and define for this signal";
CM_ SG_ 1179 EDS_F_Warning_Flag_6 "Warning Message Flag, Component owner, Supplier align and define for this signal";
CM_ SG_ 1179 EDS_F_Warning_Flag_7 "Warning Message Flag, Component owner, Supplier align and define for this signal";
CM_ SG_ 1179 EDS_F_Warning_Flag_8 "Warning Message Flag, Component owner, Supplier align and define for this signal";
CM_ SG_ 1179 EDS_F_Warning_Flag_9 "Warning Message Flag, Component owner, Supplier align and define for this signal";
CM_ SG_ 1179 EDS_F_Warning_Flag_10 "Warning Message Flag, Component owner, Supplier align and define for this signal";
CM_ SG_ 1179 EDS_F_Warning_Flag_11 "Warning Message Flag, Component owner, Supplier align and define for this signal";
CM_ SG_ 1179 EDS_F_Warning_Flag_12 "Warning Message Flag, Component owner, Supplier align and define for this signal";
CM_ SG_ 1179 EDS_F_Reserved_signal1 "Warning Message Flag, Component owner, Supplier align and define for this signal";
CM_ SG_ 1179 EDS_F_Reserved_signal2 "Warning Message Flag, Component owner, Supplier align and define for this signal";
CM_ SG_ 1179 EDS_F_Reserved_signal3 "Warning Message Flag, Component owner, Supplier align and define for this signal";
CM_ SG_ 1179 EDS_F_Reserved_signal4 "Warning Message Flag, Component owner, Supplier align and define for this signal";
CM_ SG_ 1179 EDS_F_Reserved_signal5 "Warning Message Flag, Component owner, Supplier align and define for this signal";
CM_ SG_ 1191 CHSKM_RCU_WarnMsg "Checksum";
CM_ SG_ 1191 ALV_RCU_WarnMsg "Alive Counter";
CM_ SG_ 1191 RCU_DAA_NoOpDoorOpen "EPB DAA can not be operated due to Driver Door open";
CM_ SG_ 1191 RCU_EHandBrk_fault "Electric park brake malfunction, HU mode, Maintenance mode, Bulb check";
CM_ SG_ 1191 RCU_EOL_NotDone "EOL configuration is not completely done";
CM_ SG_ 1191 RCU_ECD_RWU_active "ECD/RWU active";
CM_ SG_ 1191 RCU_ParkOnSteepInclination "Vehicle park on a steep inclination";
CM_ SG_ 1191 RCU_BrkForceNotEnough "Brake force not enough, Demand clamp force not achieved";
CM_ SG_ 1191 RCU_ReleaseEPB_Wo_PressBrk "Driver Try to release EPB without press brake pedal";
CM_ SG_ 1191 RCU_ParkBrkApplied "Parking Brake applied";
CM_ SG_ 1191 RCU_Swch_Mafnc "EPB switch is malfunction or brakes are incoherent";
CM_ SG_ 1191 RCU_DAA_NoOpBeltUnbuckled "EPB DAA can not be operated due to Driver unbuckled";
CM_ SG_ 1191 RCU_RollerBenchMode "Roller Bench mode of RCU";
CM_ SG_ 1191 RCU_EPB_ParkLampState "Electric Parking Brake Lamp request";
CM_ SG_ 1191 RCU_EPB_WarnLampState "EPB Warning Lamp request";
CM_ SG_ 1191 RCU_WflagRes36 "Reserved VCU Warning message";
CM_ SG_ 1191 RCU_WflagRes37 "Reserved VCU Warning message";
CM_ SG_ 1191 RCU_WflagRes38 "Reserved VCU Warning message";
CM_ SG_ 1191 RCU_WflagRes39 "Reserved VCU Warning message";
CM_ SG_ 1191 RCU_WflagRes40 "Reserved VCU Warning message";
CM_ SG_ 1191 RCU_WflagRes41 "Reserved VCU Warning message";
CM_ SG_ 1191 RCU_WflagRes42 "Reserved VCU Warning message";
CM_ SG_ 1191 RCU_WflagRes43 "Reserved VCU Warning message";
CM_ SG_ 1191 RCU_WflagRes44 "Reserved VCU Warning message";
CM_ SG_ 1191 RCU_WflagRes45 "Reserved VCU Warning message";
CM_ SG_ 1191 RCU_WflagRes46 "Reserved VCU Warning message";
CM_ SG_ 1191 RCU_WflagRes47 "Reserved VCU Warning message";
CM_ SG_ 1191 RCU_Reserved_signal1 "Warning Message Flag, Component owner, Supplier align and define for this signal";
CM_ SG_ 1192 CHSKM_EPS_WarnMsg "Checksum";
CM_ SG_ 1192 ALV_EPS_WarnMsg "Alive Counter";
CM_ SG_ 1192 EPS_Malfunction "EPS malfunction, No Power Assistance Steering Available";
CM_ SG_ 1192 EPS_Reduced "EPS reduced, Power Steering Assistance Reduced";
CM_ SG_ 1192 EPS_Overheat " EPS Overheat, No Power Assistance Steering Available";
CM_ SG_ 1192 EPS_NotReady "EPS is not ready, No Power Assistance Steering Available";
CM_ SG_ 1192 EPS_Warning_Flag_5 "Warning Message Flag, Component owner, Supplier align and define for this signal";
CM_ SG_ 1192 EPS_Warning_Flag_6 "Warning Message Flag, Component owner, Supplier align and define for this signal";
CM_ SG_ 1192 EPS_Warning_Flag_7 "Warning Message Flag, Component owner, Supplier align and define for this signal";
CM_ SG_ 1192 EPS_Warning_Flag_8 "Warning Message Flag, Component owner, Supplier align and define for this signal";
CM_ SG_ 1192 EPS_Warning_Flag_9 "Warning Message Flag, Component owner, Supplier align and define for this signal";
CM_ SG_ 1192 EPS_Warning_Flag_10 "Warning Message Flag, Component owner, Supplier align and define for this signal";
CM_ SG_ 1192 EPS_Warning_Flag_11 "Warning Message Flag, Component owner, Supplier align and define for this signal";
CM_ SG_ 1192 EPS_Warning_Flag_12 "Warning Message Flag, Component owner, Supplier align and define for this signal";
CM_ SG_ 1192 EPS_Reserved_signal1 "Warning Message Flag, Component owner, Supplier align and define for this signal";
CM_ SG_ 1192 EPS_Reserved_signal2 "Warning Message Flag, Component owner, Supplier align and define for this signal";
CM_ SG_ 1192 EPS_Reserved_signal3 "Warning Message Flag, Component owner, Supplier align and define for this signal";
CM_ SG_ 1192 EPS_Reserved_signal4 "Warning Message Flag, Component owner, Supplier align and define for this signal";
CM_ SG_ 1192 EPS_Reserved_signal5 "Warning Message Flag, Component owner, Supplier align and define for this signal";
CM_ SG_ 1193 CHSKM_IDB_WarnMsg "Checksum";
CM_ SG_ 1193 ALV_IDB_WarnMsg "Alive Counter";
CM_ SG_ 1193 IDB_ESC_fault "IDB Malfunction warning";
CM_ SG_ 1193 IDB_ABS_fault "Anti-lock Braking System fault warning";
CM_ SG_ 1193 IDB_BrkLowFluid "Brake Fluid low warning";
CM_ SG_ 1193 IDB_BrkSysFault "Brake system fault warning";
CM_ SG_ 1193 IDB_fault "IDB Malfunction warning";
CM_ SG_ 1193 IDB_HydraulicBrkAssist_Fault "HBA malfunction warning, Hydraulic brake assist ";
CM_ SG_ 1193 IDB_HAS_Fault "Hill start assist malfunction warning";
CM_ SG_ 1193 IDB_TSM_Fault "Trailer Sway mitigation malfunction warning";
CM_ SG_ 1193 IDB_Reserved_signal2 "Warning Message Flag, Component owner, Supplier align and define for this signal";
CM_ SG_ 1193 IDB_Reserved_signal3 "Warning Message Flag, Component owner, Supplier align and define for this signal";
CM_ SG_ 1193 IDB_Reserved_signal4 "Warning Message Flag, Component owner, Supplier align and define for this signal";
CM_ SG_ 1193 IDB_Reserved_signal5 "Warning Message Flag, Component owner, Supplier align and define for this signal";
CM_ SG_ 1196 CHSKM_VCU_WarnMsg "Checksum";
CM_ SG_ 1196 ALV_VCU_WarnMsg "Alive Counter";
CM_ SG_ 1196 VCU_GearPOnlyAtStationaryAlert "Gear position P only when stationary";
CM_ SG_ 1196 VCU_GearP_NotPossibleAlert "Gear P not possible,  Due to EPP lock is not possible, gear position P may not be possible.";
CM_ SG_ 1196 VCU_PressBrakeToEngageGear "Press Brake to engage gear hint";
CM_ SG_ 1196 VCU_CantChangeGear "Unable to change gear position";
CM_ SG_ 1196 VCU_GearMalfunction "Gear change might be not possible, Possibly faulty selector lever";
CM_ SG_ 1196 VCU_RangeAlert "The range warning, charging soon";
CM_ SG_ 1196 VCU_HVSystemReduced "Reduced HV System Power";
CM_ SG_ 1196 VCU_FrontEDSReduced "Reduced Front EDS Power";
CM_ SG_ 1196 VCU_FrontEDS_Malfunc "Front EDS malfunction";
CM_ SG_ 1196 VCU_RearEDSReduced "Reduced Rear EDS Power";
CM_ SG_ 1196 VCU_RearEDS_Malfunc "Rear EDS malfunction";
CM_ SG_ 1196 VCU_CoolingSystem_Malfunc "EV Cooling system malfunction";
CM_ SG_ 1196 VCU_NeutralRequest "Neutral request warning";
CM_ SG_ 1196 VCU_SoftShutdown "Soft shutdown warning";
CM_ SG_ 1196 VCU_EmergencyShutdown "Emergency Shutdown warning";
CM_ SG_ 1196 VCU_ChgPortDoorSys_Malfunc "Charging Port Door Defective";
CM_ SG_ 1196 VCU_Gearchange_NotPossible "During Game Mode, or charging gun attached, gear change not possible";
CM_ SG_ 1196 VCU_12v_Warning "VCU warning for 12v battery based on data received from BCM ";
CM_ SG_ 1196 VCU_WflagRes19 "Reserved VCU Warning message";
CM_ SG_ 1196 VCU_WflagRes20 "Reserved VCU Warning message";
CM_ SG_ 1196 VCU_WflagRes21 "Reserved VCU Warning message";
CM_ SG_ 1196 VCU_WflagRes22 "Reserved VCU Warning message";
CM_ SG_ 1196 VCU_WflagRes23 "Reserved VCU Warning message";
CM_ SG_ 1196 VCU_WflagRes24 "Reserved VCU Warning message";
CM_ SG_ 1196 VCU_WflagRes25 "Reserved VCU Warning message";
CM_ SG_ 1196 VCU_WflagRes26 "Reserved VCU Warning message";
CM_ SG_ 1196 VCU_WflagRes27 "Reserved VCU Warning message";
CM_ SG_ 1196 VCU_SuperFastCharge_longer "VCU SuperFastCharge longer";
CM_ SG_ 1196 VCU_InvalidLimitSpeed "Warning for Invalid Speed limit";
CM_ SG_ 1196 VCU_InvalidCruiseSpeed "Warning for Invalid Cruise Speed";
CM_ SG_ 1196 VCU_Reserved_signal2 "Warning Message Flag, Component owner, Supplier align and define for this signal";
CM_ SG_ 1196 VCU_Reserved_signal3 "Warning Message Flag, Component owner, Supplier align and define for this signal";
CM_ SG_ 1198 CHSKM_EASC_WarnMsg "Checksum";
CM_ SG_ 1198 ALV_EASC_WarnMsg "Alive Counter";
CM_ SG_ 1198 EASC_Warning_Flag_1 "Warning Message Flag, Component owner, Supplier align and define for this signal";
CM_ SG_ 1198 EASC_Warning_Flag_2 "Warning Message Flag, Component owner, Supplier align and define for this signal";
CM_ SG_ 1198 EASC_Warning_Flag_3 "Warning Message Flag, Component owner, Supplier align and define for this signal";
CM_ SG_ 1198 EASC_Warning_Flag_4 "Warning Message Flag, Component owner, Supplier align and define for this signal";
CM_ SG_ 1198 EASC_Warning_Flag_5 "Warning Message Flag, Component owner, Supplier align and define for this signal";
CM_ SG_ 1198 EASC_Warning_Flag_6 "Warning Message Flag, Component owner, Supplier align and define for this signal";
CM_ SG_ 1198 EASC_Warning_Flag_7 "Warning Message Flag, Component owner, Supplier align and define for this signal";
CM_ SG_ 1198 EASC_Warning_Flag_8 "Warning Message Flag, Component owner, Supplier align and define for this signal";
CM_ SG_ 1198 EASC_Warning_Flag_9 "Warning Message Flag, Component owner, Supplier align and define for this signal";
CM_ SG_ 1198 EASC_Warning_Flag_10 "Warning Message Flag, Component owner, Supplier align and define for this signal";
CM_ SG_ 1198 EASC_Warning_Flag_11 "Warning Message Flag, Component owner, Supplier align and define for this signal";
CM_ SG_ 1198 EASC_Warning_Flag_12 "Warning Message Flag, Component owner, Supplier align and define for this signal";
CM_ SG_ 1198 EASC_Reserved_signal1 "Warning Message Flag, Component owner, Supplier align and define for this signal";
CM_ SG_ 1198 EASC_Reserved_signal2 "Warning Message Flag, Component owner, Supplier align and define for this signal";
CM_ SG_ 1198 EASC_Reserved_signal3 "Warning Message Flag, Component owner, Supplier align and define for this signal";
CM_ SG_ 1198 EASC_Reserved_signal4 "Warning Message Flag, Component owner, Supplier align and define for this signal";
CM_ SG_ 1198 EASC_Reserved_signal5 "Warning Message Flag, Component owner, Supplier align and define for this signal";
CM_ SG_ 1199 CHSKM_CPD_WarnMsg "Checksum";
CM_ SG_ 1199 ALV_CPD_WarnMsg "Alive Counter";
CM_ SG_ 1199 CPD_Malfunction "CPD malfunction";
CM_ SG_ 1199 CPD_SensorFault "CPD Sensor fault status";
CM_ SG_ 1199 CPD_Warning_Flag_4 "Warning Message Flag, Component owner, Supplier align and define for this signal";
CM_ SG_ 1199 CPD_Warning_Flag_5 "Warning Message Flag, Component owner, Supplier align and define for this signal";
CM_ SG_ 1199 CPD_Warning_Flag_6 "Warning Message Flag, Component owner, Supplier align and define for this signal";
CM_ SG_ 1199 CPD_Warning_Flag_7 "Warning Message Flag, Component owner, Supplier align and define for this signal";
CM_ SG_ 1199 CPD_Warning_Flag_8 "Warning Message Flag, Component owner, Supplier align and define for this signal";
CM_ SG_ 1199 CPD_Warning_Flag_9 "Warning Message Flag, Component owner, Supplier align and define for this signal";
CM_ SG_ 1199 CPD_Warning_Flag_10 "Warning Message Flag, Component owner, Supplier align and define for this signal";
CM_ SG_ 1199 CPD_Warning_Flag_11 "Warning Message Flag, Component owner, Supplier align and define for this signal";
CM_ SG_ 1199 CPD_Warning_Flag_12 "Warning Message Flag, Component owner, Supplier align and define for this signal";
CM_ SG_ 1199 CPD_Reserved_signal1 "Warning Message Flag, Component owner, Supplier align and define for this signal";
CM_ SG_ 1199 CPD_Reserved_signal2 "Warning Message Flag, Component owner, Supplier align and define for this signal";
CM_ SG_ 1199 CPD_Reserved_signal3 "Warning Message Flag, Component owner, Supplier align and define for this signal";
CM_ SG_ 1199 CPD_Reserved_signal4 "Warning Message Flag, Component owner, Supplier align and define for this signal";
CM_ SG_ 1199 CPD_Reserved_signal5 "Warning Message Flag, Component owner, Supplier align and define for this signal";
CM_ SG_ 1209 Checksum_0x4B9 "Checksum";
CM_ SG_ 1209 Rolling_Counter_0x4B9 "Rolling_Counter";
CM_ SG_ 1209 BSD_Warning_Flag_7 "Corner Short Range Rear Left Radar temporary not available";
CM_ SG_ 1209 BSD_Warning_Flag_8 "Corner Short Range Rear Left Radar permanently not available";
CM_ SG_ 1209 BSD_Warning_Flag_9 "Corner Short Range Rear Right Radar temporary not available";
CM_ SG_ 1209 BSD_Warning_Flag_10 "Corner Short Range Rear Right Radar permanently not available";
CM_ SG_ 1209 BSD_Warning_Flag_14 "I-ECU has BSD function fault : speed /gear loss";
CM_ SG_ 1209 BSD_Warning_Flag_21 "LeftCornerRadaar Install Faulty";
CM_ SG_ 1209 BSD_Warning_Flag_22 "RightCornerRadaar Install Faulty";
CM_ SG_ 1209 BSD_Warning_Flag_23 "LeftCornerRadaar Calib Faulty";
CM_ SG_ 1209 BSD_Warning_Flag_24 "RightCornerRadaar Calib Faulty";
CM_ SG_ 1211 CHSKM_TRM_WarnMsg "Checksum";
CM_ SG_ 1211 ALV_TRM_WarnMsg "Alive Counter";
CM_ SG_ 1211 TRM_LightMalfnc "Trailer light malffunction";
CM_ SG_ 1211 TRM_TurnLeftMafnc "Trailer turn indicator left malfunction";
CM_ SG_ 1211 TRM_TurnRightMafnc "Trailer turn indicator right malfunction";
CM_ SG_ 1211 TRM_TrailerMalfnc "Trailer system malfunction";
CM_ SG_ 1211 TRM_Warning_Flag_5 "Warning Message Flag, Component owner, Supplier align and define for this signal";
CM_ SG_ 1211 TRM_Warning_Flag_6 "Warning Message Flag, Component owner, Supplier align and define for this signal";
CM_ SG_ 1211 TRM_Warning_Flag_7 "Warning Message Flag, Component owner, Supplier align and define for this signal";
CM_ SG_ 1211 TRM_Warning_Flag_8 "Warning Message Flag, Component owner, Supplier align and define for this signal";
CM_ SG_ 1211 TRM_Warning_Flag_9 "Warning Message Flag, Component owner, Supplier align and define for this signal";
CM_ SG_ 1211 TRM_Warning_Flag_10 "Warning Message Flag, Component owner, Supplier align and define for this signal";
CM_ SG_ 1211 TRM_Warning_Flag_11 "Warning Message Flag, Component owner, Supplier align and define for this signal";
CM_ SG_ 1211 TRM_Warning_Flag_12 "Warning Message Flag, Component owner, Supplier align and define for this signal";
CM_ SG_ 1213 CHSKM_POD_WarnMsg "Checksum";
CM_ SG_ 1213 ALV_POD_WarnMsg "Alive Counter";
CM_ SG_ 1213 POD_Warning_Flag_1 "Warning Message Flag, Component owner, Supplier align and define for this signal";
CM_ SG_ 1213 POD_Warning_Flag_2 "Warning Message Flag, Component owner, Supplier align and define for this signal";
CM_ SG_ 1213 POD_Warning_Flag_3 "Warning Message Flag, Component owner, Supplier align and define for this signal";
CM_ SG_ 1213 POD_Warning_Flag_4 "Warning Message Flag, Component owner, Supplier align and define for this signal";
CM_ SG_ 1213 POD_Warning_Flag_5 "Warning Message Flag, Component owner, Supplier align and define for this signal";
CM_ SG_ 1213 POD_Warning_Flag_6 "Warning Message Flag, Component owner, Supplier align and define for this signal";
CM_ SG_ 1213 POD_Warning_Flag_7 "Warning Message Flag, Component owner, Supplier align and define for this signal";
CM_ SG_ 1213 POD_Warning_Flag_8 "Warning Message Flag, Component owner, Supplier align and define for this signal";
CM_ SG_ 1213 POD_Warning_Flag_9 "Warning Message Flag, Component owner, Supplier align and define for this signal";
CM_ SG_ 1213 POD_Warning_Flag_10 "Warning Message Flag, Component owner, Supplier align and define for this signal";
CM_ SG_ 1213 POD_Warning_Flag_11 "Warning Message Flag, Component owner, Supplier align and define for this signal";
CM_ SG_ 1213 POD_Warning_Flag_12 "Warning Message Flag, Component owner, Supplier align and define for this signal";
CM_ SG_ 1213 POD_Warning_Flag_13 "Warning Message Flag, Component owner, Supplier align and define for this signal";
CM_ SG_ 1213 POD_Warning_Flag_14 "Warning Message Flag, Component owner, Supplier align and define for this signal";
CM_ SG_ 1213 POD_Warning_Flag_15 "Warning Message Flag, Component owner, Supplier align and define for this signal";
CM_ SG_ 1213 POD_Warning_Flag_16 "Warning Message Flag, Component owner, Supplier align and define for this signal";
CM_ SG_ 1213 POD_Warning_Flag_17 "Warning Message Flag, Component owner, Supplier align and define for this signal";
CM_ SG_ 1213 POD_Warning_Flag_18 "Warning Message Flag, Component owner, Supplier align and define for this signal";
CM_ SG_ 1213 POD_Warning_Flag_19 "Warning Message Flag, Component owner, Supplier align and define for this signal";
CM_ SG_ 1213 POD_Warning_Flag_20 "Warning Message Flag, Component owner, Supplier align and define for this signal";
CM_ SG_ 1213 POD_Warning_Flag_21 "Warning Message Flag, Component owner, Supplier align and define for this signal";
CM_ SG_ 1213 POD_Warning_Flag_22 "Warning Message Flag, Component owner, Supplier align and define for this signal";
CM_ SG_ 1213 POD_Warning_Flag_23 "Warning Message Flag, Component owner, Supplier align and define for this signal";
CM_ SG_ 1213 POD_Warning_Flag_24 "Warning Message Flag, Component owner, Supplier align and define for this signal";
CM_ SG_ 1213 POD_Warning_Flag_25 "Warning Message Flag, Component owner, Supplier align and define for this signal";
CM_ SG_ 1213 POD_Warning_Flag_26 "Warning Message Flag, Component owner, Supplier align and define for this signal";
CM_ SG_ 1213 POD_Warning_Flag_27 "Warning Message Flag, Component owner, Supplier align and define for this signal";
CM_ SG_ 1213 POD_Warning_Flag_28 "Warning Message Flag, Component owner, Supplier align and define for this signal";
CM_ SG_ 1213 POD_Reserved_signal3 "Warning Message Flag, Component owner, Supplier align and define for this signal";
CM_ SG_ 1213 POD_Reserved_signal4 "Warning Message Flag, Component owner, Supplier align and define for this signal";
CM_ SG_ 1213 POD_Reserved_signal5 "Warning Message Flag, Component owner, Supplier align and define for this signal";
CM_ SG_ 1217 CHSKM_APM_WarnMsg "Checksum";
CM_ SG_ 1217 ALV_APM_WarnMsg "Alive Counter";
CM_ SG_ 1217 APM_Malfunction "Anti-pinch module malfunction";
CM_ SG_ 1217 ChildWindowLockStS "Child window lock status";
CM_ SG_ 1217 APM_Warning_Flag_3 "Warning Message Flag, Component owner, Supplier align and define for this signal";
CM_ SG_ 1217 APM_Warning_Flag_4 "Warning Message Flag, Component owner, Supplier align and define for this signal";
CM_ SG_ 1217 APM_Warning_Flag_5 "Warning Message Flag, Component owner, Supplier align and define for this signal";
CM_ SG_ 1217 APM_Warning_Flag_6 "Warning Message Flag, Component owner, Supplier align and define for this signal";
CM_ SG_ 1217 APM_Warning_Flag_7 "Warning Message Flag, Component owner, Supplier align and define for this signal";
CM_ SG_ 1217 APM_Warning_Flag_8 "Warning Message Flag, Component owner, Supplier align and define for this signal";
CM_ SG_ 1217 APM_Warning_Flag_9 "Warning Message Flag, Component owner, Supplier align and define for this signal";
CM_ SG_ 1217 APM_Warning_Flag_10 "Warning Message Flag, Component owner, Supplier align and define for this signal";
CM_ SG_ 1217 APM_Warning_Flag_11 "Warning Message Flag, Component owner, Supplier align and define for this signal";
CM_ SG_ 1217 APM_Warning_Flag_12 "Warning Message Flag, Component owner, Supplier align and define for this signal";
CM_ SG_ 1218 Checksum_0x4C2 "Checksum";
CM_ SG_ 1218 Rolling_Counter_0x4C2 "Alive Counter";
CM_ SG_ 1218 Event_Counter "Number of event in XGW buffer";
CM_ SG_ 1218 Event_type "Store current attack types";
CM_ SG_ 1282 XGW_srcNodeID "Network Management Signal";
CM_ SG_ 1282 XGW_CtrlBitVector "Network Management Signal";
CM_ SG_ 1282 XGW_usrData0 "Network Management Signal";
CM_ SG_ 1282 XGW_usrData1 "Network Management Signal";
CM_ SG_ 1282 XGW_usrData2 "Network Management Signal";
CM_ SG_ 1282 XGW_usrData3 "Network Management Signal";
CM_ SG_ 1282 XGW_usrData4 "Network Management Signal";
CM_ SG_ 1282 XGW_usrData5 "Network Management Signal";
CM_ SG_ 1284 MHU_srcNodeID "Network Management Signal";
CM_ SG_ 1284 MHU_CtrlBitVector "Network Management Signal";
CM_ SG_ 1284 MHU_usrData0 "Network Management Signal";
CM_ SG_ 1284 MHU_usrData1 "Network Management Signal";
CM_ SG_ 1284 MHU_usrData2 "Network Management Signal";
CM_ SG_ 1284 MHU_usrData3 "Network Management Signal";
CM_ SG_ 1284 MHU_usrData4 "Network Management Signal";
CM_ SG_ 1284 MHU_usrData5 "Network Management Signal";
CM_ SG_ 1293 HUD_srcNodeID "Network Management Signal";
CM_ SG_ 1293 HUD_CtrlBitVector "Network Management Signal";
CM_ SG_ 1293 HUD_usrData0 "Network Management Signal";
CM_ SG_ 1293 HUD_usrData1 "Network Management Signal";
CM_ SG_ 1293 HUD_usrData2 "Network Management Signal";
CM_ SG_ 1293 HUD_usrData3 "Network Management Signal";
CM_ SG_ 1293 HUD_usrData4 "Network Management Signal";
CM_ SG_ 1293 HUD_usrData5 "Network Management Signal";
CM_ SG_ 1302 FCAM_srcNodeID "Network Management Signal";
CM_ SG_ 1302 FCAM_CtrlBitVector "Network Management Signal";
CM_ SG_ 1302 FCAM_usrData0 "Network Management Signal";
CM_ SG_ 1302 FCAM_usrData1 "Network Management Signal";
CM_ SG_ 1302 FCAM_usrData2 "Network Management Signal";
CM_ SG_ 1302 FCAM_usrData3 "Network Management Signal";
CM_ SG_ 1302 FCAM_usrData4 "Network Management Signal";
CM_ SG_ 1302 FCAM_usrData5 "Network Management Signal";
CM_ SG_ 1303 PAS_srcNodeID "Network Management signal";
CM_ SG_ 1303 PAS_CtrlBitVector "Network Management signal";
CM_ SG_ 1303 PAS_usrData0 "Network Management signal";
CM_ SG_ 1303 PAS_usrData1 "Network Management signal";
CM_ SG_ 1303 PAS_usrData2 "Network Management signal";
CM_ SG_ 1303 PAS_usrData3 "Network Management signal";
CM_ SG_ 1303 PAS_usrData4 "Network Management signal";
CM_ SG_ 1303 PAS_usrData5 "Network Management signal";
CM_ SG_ 1326 EASC_srcNodeID "Network Management Signal";
CM_ SG_ 1326 EASC_CtrlBitVector "Network Management Signal";
CM_ SG_ 1326 EASC_usrData0 "Network Management Signal";
CM_ SG_ 1326 EASC_usrData1 "Network Management Signal";
CM_ SG_ 1326 EASC_usrData2 "Network Management Signal";
CM_ SG_ 1326 EASC_usrData3 "Network Management Signal";
CM_ SG_ 1326 EASC_usrData4 "Network Management Signal";
CM_ SG_ 1326 EASC_usrData5 "Network Management Signal";
CM_ SG_ 1327 CPD_srcNodeID "Network Management Signal";
CM_ SG_ 1327 CPD_CtrlBitVector "Network Management Signal";
CM_ SG_ 1327 CPD_usrData0 "Network Management Signal";
CM_ SG_ 1327 CPD_usrData1 "Network Management Signal";
CM_ SG_ 1327 CPD_usrData2 "Network Management Signal";
CM_ SG_ 1327 CPD_usrData3 "Network Management Signal";
CM_ SG_ 1327 CPD_usrData4 "Network Management Signal";
CM_ SG_ 1327 CPD_usrData5 "Network Management Signal";
CM_ SG_ 1537 BCM_DiagRespData0 "Diagnostic signal Data response";
CM_ SG_ 1537 BCM_DiagRespData1 "Remote Diagnostic signal Data response";
CM_ SG_ 1537 BCM_DiagRespData2 "Diagnostic signal Data response";
CM_ SG_ 1537 BCM_DiagRespData3 "Diagnostic signal Data response";
CM_ SG_ 1537 BCM_DiagRespData4 "Diagnostic signal Data response";
CM_ SG_ 1537 BCM_DiagRespData5 "Diagnostic signal Data response";
CM_ SG_ 1537 BCM_DiagRespData6 "Remote Diagnostic signal Data response";
CM_ SG_ 1537 BCM_DiagRespData7 "Diagnostic signal Data response";
CM_ SG_ 1538 XGW_DiagRespData0 "Remote Diagnostic signal Data response";
CM_ SG_ 1538 XGW_DiagRespData1 "Remote Diagnostic signal Data response";
CM_ SG_ 1538 XGW_DiagRespData2 "Remote Diagnostic signal Data response";
CM_ SG_ 1538 XGW_DiagRespData3 "Diagnostic signal Data response";
CM_ SG_ 1538 XGW_DiagRespData4 "Diagnostic signal Data response";
CM_ SG_ 1538 XGW_DiagRespData5 "Remote Diagnostic signal Data response";
CM_ SG_ 1538 XGW_DiagRespData6 "Diagnostic signal Data response";
CM_ SG_ 1538 XGW_DiagRespData7 "Remote Diagnostic signal Data response";
CM_ SG_ 1540 MHU_DiagRespData0 "Diagnostic signal Data response";
CM_ SG_ 1540 MHU_DiagRespData1 "Diagnostic signal Data response";
CM_ SG_ 1540 MHU_DiagRespData2 "Diagnostic signal Data response";
CM_ SG_ 1540 MHU_DiagRespData3 "Diagnostic signal Data response";
CM_ SG_ 1540 MHU_DiagRespData4 "Diagnostic signal Data response";
CM_ SG_ 1540 MHU_DiagRespData5 "Diagnostic signal Data response";
CM_ SG_ 1540 MHU_DiagRespData6 "Diagnostic signal Data response";
CM_ SG_ 1540 MHU_DiagRespData7 "Diagnostic signal Data response";
CM_ SG_ 1541 AMP_DiagRespData0 "Remote Diagnostic signal Data response";
CM_ SG_ 1541 AMP_DiagRespData1 "Remote Diagnostic signal Data response";
CM_ SG_ 1541 AMP_DiagRespData2 "Remote Diagnostic signal Data response";
CM_ SG_ 1541 AMP_DiagRespData3 "Diagnostic signal Data response";
CM_ SG_ 1541 AMP_DiagRespData4 "Remote Diagnostic signal Data response";
CM_ SG_ 1541 AMP_DiagRespData5 "Diagnostic signal Data response";
CM_ SG_ 1541 AMP_DiagRespData6 "Diagnostic signal Data response";
CM_ SG_ 1541 AMP_DiagRespData7 "Remote Diagnostic signal Data response";
CM_ SG_ 1544 ACM_DiagRespData0 "Diagnostic signal Data response";
CM_ SG_ 1544 ACM_DiagRespData1 "Remote Diagnostic signal Data response";
CM_ SG_ 1544 ACM_DiagRespData2 "Diagnostic signal Data response";
CM_ SG_ 1544 ACM_DiagRespData3 "Remote Diagnostic signal Data response";
CM_ SG_ 1544 ACM_DiagRespData4 "Diagnostic signal Data response";
CM_ SG_ 1544 ACM_DiagRespData5 "Remote Diagnostic signal Data response";
CM_ SG_ 1544 ACM_DiagRespData6 "Diagnostic signal Data response";
CM_ SG_ 1544 ACM_DiagRespData7 "Remote Diagnostic signal Data response";
CM_ SG_ 1545 CCUF_DiagRespData0 "Diagnostic signal Data response";
CM_ SG_ 1545 CCUF_DiagRespData1 "Remote Diagnostic signal Data response";
CM_ SG_ 1545 CCUF_DiagRespData2 "Remote Diagnostic signal Data response";
CM_ SG_ 1545 CCUF_DiagRespData3 "Diagnostic signal Data response";
CM_ SG_ 1545 CCUF_DiagRespData4 "Diagnostic signal Data response";
CM_ SG_ 1545 CCUF_DiagRespData5 "Remote Diagnostic signal Data response";
CM_ SG_ 1545 CCUF_DiagRespData6 "Remote Diagnostic signal Data response";
CM_ SG_ 1545 CCUF_DiagRespData7 "Diagnostic signal Data response";
CM_ SG_ 1549 HUD_DiagRespData0 "Diagnostic signal Data response";
CM_ SG_ 1549 HUD_DiagRespData1 "Diagnostic signal Data response";
CM_ SG_ 1549 HUD_DiagRespData2 "Diagnostic signal Data response";
CM_ SG_ 1549 HUD_DiagRespData3 "Diagnostic signal Data response";
CM_ SG_ 1549 HUD_DiagRespData4 "Diagnostic signal Data response";
CM_ SG_ 1549 HUD_DiagRespData5 "Diagnostic signal Data response";
CM_ SG_ 1549 HUD_DiagRespData6 "Diagnostic signal Data response";
CM_ SG_ 1549 HUD_DiagRespData7 "Diagnostic signal Data response";
CM_ SG_ 1550 ETG_DiagRespData0 "Diagnostic signal Data response";
CM_ SG_ 1550 ETG_DiagRespData1 "Diagnostic signal Data response";
CM_ SG_ 1550 ETG_DiagRespData2 "Diagnostic signal Data response";
CM_ SG_ 1550 ETG_DiagRespData3 "Remote Diagnostic signal Data response";
CM_ SG_ 1550 ETG_DiagRespData4 "Diagnostic signal Data response";
CM_ SG_ 1550 ETG_DiagRespData5 "Diagnostic signal Data response";
CM_ SG_ 1550 ETG_DiagRespData6 "Diagnostic signal Data response";
CM_ SG_ 1550 ETG_DiagRespData7 "Diagnostic signal Data response";
CM_ SG_ 1551 YSS_DiagRespData0 "Diagnostic signal Data response";
CM_ SG_ 1551 YSS_DiagRespData1 "Diagnostic signal Data response";
CM_ SG_ 1551 YSS_DiagRespData2 "Diagnostic signal Data response";
CM_ SG_ 1551 YSS_DiagRespData3 "Diagnostic signal Data response";
CM_ SG_ 1551 YSS_DiagRespData4 "Diagnostic signal Data response";
CM_ SG_ 1551 YSS_DiagRespData5 "Diagnostic signal Data response";
CM_ SG_ 1551 YSS_DiagRespData6 "Diagnostic signal Data response";
CM_ SG_ 1551 YSS_DiagRespData7 "Diagnostic signal Data response";
CM_ SG_ 1552 GS_DiagRespData0 "Remote Diagnostic signal Data response";
CM_ SG_ 1552 GS_DiagRespData1 "Diagnostic signal Data response";
CM_ SG_ 1552 GS_DiagRespData2 "Remote Diagnostic signal Data response";
CM_ SG_ 1552 GS_DiagRespData3 "Diagnostic signal Data response";
CM_ SG_ 1552 GS_DiagRespData4 "Diagnostic signal Data response";
CM_ SG_ 1552 GS_DiagRespData5 "Diagnostic signal Data response";
CM_ SG_ 1552 GS_DiagRespData6 "Remote Diagnostic signal Data response";
CM_ SG_ 1552 GS_DiagRespData7 "Diagnostic signal Data response";

BA_DEF_ BO_  "GenMsgSendType" ENUM "Cyclic","NotUsed","NotUsed","NotUsed","NotUsed","NotUsed","NotUsed","IfActive","NoMsgSendType","NotUsed";
BA_DEF_ BO_  "GenMsgILSupport" ENUM "No","Yes";
BA_DEF_ BO_  "DiagResponse" ENUM "No","Yes";
BA_DEF_ BO_  "DiagRequest" ENUM "No","Yes";
BA_DEF_ BO_  "NmAsrMessage" ENUM "No","Yes";
BA_DEF_ BO_  "DiagState" ENUM "No","Yes";
BA_DEF_ BO_  "DiagUudtResponse" ENUM "False","True";
BA_DEF_ BO_  "GenMsgStartDelayTime" INT 0 65535;
BA_DEF_ BO_  "GenMsgDelayTime" INT 0 0;
BA_DEF_ BO_  "GenMsgNrOfRepetition" INT 0 0;
BA_DEF_ BO_  "GenMsgCycleTimeFast" INT 0 0;
BA_DEF_ BO_  "GenMsgCycleTime" INT 0 0;
BA_DEF_ SG_  "GenSigSendType" ENUM "Cyclic","OnWrite","OnWriteWithRepetition","OnChange","OnChangeWithRepetition","IfActive","IfActiveWithRepetition","NoSigSendType","NotUsed","NotUsed","NotUsed","NotUsed","NotUsed";
BA_DEF_ SG_  "InvalidValue" STRING;
BA_DEF_ SG_  "GenSigStartValue" INT 0 0;
BA_DEF_ SG_  "GenSigTimeoutTime_ALL" INT 0 65535;
BA_DEF_DEF_  "DiagRequest" "No";
BA_DEF_DEF_  "DiagResponse" "No";
BA_DEF_DEF_  "DiagState" "No";
BA_DEF_DEF_  "DiagUudtResponse" "False";
BA_DEF_DEF_  "GenMsgCycleTime" 0;
BA_DEF_DEF_  "GenMsgCycleTimeFast" 0;
BA_DEF_DEF_  "GenMsgDelayTime" 0;
BA_DEF_DEF_  "GenMsgILSupport" "Yes";
BA_DEF_DEF_  "GenMsgNrOfRepetition" 0;
BA_DEF_DEF_  "GenMsgSendType" "NoMsgSendType";
BA_DEF_DEF_  "GenMsgStartDelayTime" 0;
BA_DEF_DEF_  "GenSigSendType" "Cyclic";
BA_DEF_DEF_  "GenSigStartValue" 0;
BA_DEF_DEF_  "GenSigTimeoutTime_ALL" 0;
BA_DEF_DEF_  "NmAsrMessage" "No";
BA_ "GenMsgCycleTime" BO_ 1153 1000;
BA_ "GenMsgCycleTimeFast" BO_ 1153 100;
BA_ "GenMsgDelayTime" BO_ 1153 25;
BA_ "GenMsgNrOfRepetition" BO_ 1153 2;
BA_ "GenMsgSendType" BO_ 1153 0;
BA_ "GenMsgCycleTime" BO_ 1154 1000;
BA_ "GenMsgCycleTimeFast" BO_ 1154 100;
BA_ "GenMsgNrOfRepetition" BO_ 1154 2;
BA_ "GenMsgSendType" BO_ 1154 0;
BA_ "GenMsgCycleTime" BO_ 1155 50;
BA_ "GenMsgSendType" BO_ 1155 0;
BA_ "GenMsgCycleTime" BO_ 1156 50;
BA_ "GenMsgSendType" BO_ 1156 0;
BA_ "GenMsgSendType" BO_ 1157 0;
BA_ "GenMsgCycleTime" BO_ 1157 50;
BA_ "GenMsgSendType" BO_ 1158 0;
BA_ "GenMsgCycleTime" BO_ 1158 50;
BA_ "GenMsgCycleTime" BO_ 1160 1000;
BA_ "GenMsgCycleTimeFast" BO_ 1160 100;
BA_ "GenMsgNrOfRepetition" BO_ 1160 2;
BA_ "GenMsgSendType" BO_ 1160 0;
BA_ "GenMsgCycleTime" BO_ 1161 1000;
BA_ "GenMsgCycleTimeFast" BO_ 1161 100;
BA_ "GenMsgNrOfRepetition" BO_ 1161 2;
BA_ "GenMsgSendType" BO_ 1161 0;
BA_ "GenMsgCycleTime" BO_ 1165 1000;
BA_ "GenMsgCycleTimeFast" BO_ 1165 100;
BA_ "GenMsgNrOfRepetition" BO_ 1165 2;
BA_ "GenMsgSendType" BO_ 1165 0;
BA_ "GenMsgCycleTime" BO_ 1166 100;
BA_ "GenMsgSendType" BO_ 1166 0;
BA_ "GenMsgCycleTime" BO_ 1168 1000;
BA_ "GenMsgCycleTimeFast" BO_ 1168 100;
BA_ "GenMsgNrOfRepetition" BO_ 1168 2;
BA_ "GenMsgSendType" BO_ 1168 0;
BA_ "GenMsgCycleTime" BO_ 1171 1000;
BA_ "GenMsgCycleTimeFast" BO_ 1171 100;
BA_ "GenMsgILSupport" BO_ 1171 0;
BA_ "GenMsgNrOfRepetition" BO_ 1171 2;
BA_ "GenMsgSendType" BO_ 1171 0;
BA_ "GenMsgCycleTime" BO_ 1178 1000;
BA_ "GenMsgCycleTimeFast" BO_ 1178 100;
BA_ "GenMsgNrOfRepetition" BO_ 1178 2;
BA_ "GenMsgSendType" BO_ 1178 0;
BA_ "GenMsgCycleTime" BO_ 1179 1000;
BA_ "GenMsgCycleTimeFast" BO_ 1179 100;
BA_ "GenMsgNrOfRepetition" BO_ 1179 2;
BA_ "GenMsgSendType" BO_ 1179 0;
BA_ "GenMsgCycleTime" BO_ 1191 1000;
BA_ "GenMsgCycleTimeFast" BO_ 1191 100;
BA_ "GenMsgNrOfRepetition" BO_ 1191 2;
BA_ "GenMsgSendType" BO_ 1191 0;
BA_ "GenMsgCycleTime" BO_ 1192 1000;
BA_ "GenMsgCycleTimeFast" BO_ 1192 100;
BA_ "GenMsgNrOfRepetition" BO_ 1192 2;
BA_ "GenMsgSendType" BO_ 1192 0;
BA_ "GenMsgCycleTime" BO_ 1193 1000;
BA_ "GenMsgCycleTimeFast" BO_ 1193 100;
BA_ "GenMsgNrOfRepetition" BO_ 1193 2;
BA_ "GenMsgSendType" BO_ 1193 0;
BA_ "GenMsgCycleTime" BO_ 1196 1000;
BA_ "GenMsgCycleTimeFast" BO_ 1196 100;
BA_ "GenMsgNrOfRepetition" BO_ 1196 2;
BA_ "GenMsgSendType" BO_ 1196 0;
BA_ "GenMsgCycleTime" BO_ 1198 1000;
BA_ "GenMsgCycleTimeFast" BO_ 1198 100;
BA_ "GenMsgNrOfRepetition" BO_ 1198 2;
BA_ "GenMsgSendType" BO_ 1198 0;
BA_ "GenMsgCycleTime" BO_ 1199 1000;
BA_ "GenMsgCycleTimeFast" BO_ 1199 100;
BA_ "GenMsgNrOfRepetition" BO_ 1199 2;
BA_ "GenMsgSendType" BO_ 1199 0;
BA_ "GenMsgSendType" BO_ 1209 0;
BA_ "GenMsgCycleTime" BO_ 1209 1000;
BA_ "GenMsgCycleTime" BO_ 1211 100;
BA_ "GenMsgCycleTimeFast" BO_ 1211 25;
BA_ "GenMsgDelayTime" BO_ 1211 25;
BA_ "GenMsgNrOfRepetition" BO_ 1211 3;
BA_ "GenMsgSendType" BO_ 1211 0;
BA_ "GenMsgCycleTime" BO_ 1213 1000;
BA_ "GenMsgCycleTimeFast" BO_ 1213 100;
BA_ "GenMsgNrOfRepetition" BO_ 1213 2;
BA_ "GenMsgSendType" BO_ 1213 0;
BA_ "GenMsgCycleTime" BO_ 1217 1000;
BA_ "GenMsgSendType" BO_ 1217 0;
BA_ "GenMsgCycleTime" BO_ 1218 500;
BA_ "GenMsgSendType" BO_ 1218 0;
BA_ "GenMsgCycleTime" BO_ 1282 640;
BA_ "GenMsgILSupport" BO_ 1282 0;
BA_ "GenMsgSendType" BO_ 1282 0;
BA_ "NmAsrMessage" BO_ 1282 1;
BA_ "GenMsgCycleTime" BO_ 1284 640;
BA_ "GenMsgILSupport" BO_ 1284 0;
BA_ "GenMsgSendType" BO_ 1284 0;
BA_ "NmAsrMessage" BO_ 1284 1;
BA_ "GenMsgCycleTime" BO_ 1293 640;
BA_ "GenMsgILSupport" BO_ 1293 0;
BA_ "GenMsgSendType" BO_ 1293 0;
BA_ "NmAsrMessage" BO_ 1293 1;
BA_ "GenMsgSendType" BO_ 1302 0;
BA_ "GenMsgCycleTime" BO_ 1302 640;
BA_ "GenMsgSendType" BO_ 1303 0;
BA_ "GenMsgCycleTime" BO_ 1303 640;
BA_ "GenMsgCycleTime" BO_ 1326 640;
BA_ "GenMsgILSupport" BO_ 1326 0;
BA_ "GenMsgSendType" BO_ 1326 0;
BA_ "NmAsrMessage" BO_ 1326 1;
BA_ "GenMsgCycleTime" BO_ 1327 640;
BA_ "GenMsgILSupport" BO_ 1327 0;
BA_ "GenMsgSendType" BO_ 1327 0;
BA_ "NmAsrMessage" BO_ 1327 1;
BA_ "DiagResponse" BO_ 1537 1;
BA_ "GenMsgILSupport" BO_ 1537 0;
BA_ "DiagResponse" BO_ 1538 1;
BA_ "GenMsgILSupport" BO_ 1538 0;
BA_ "DiagResponse" BO_ 1540 1;
BA_ "GenMsgILSupport" BO_ 1540 0;
BA_ "DiagResponse" BO_ 1541 1;
BA_ "GenMsgILSupport" BO_ 1541 0;
BA_ "DiagResponse" BO_ 1544 1;
BA_ "GenMsgILSupport" BO_ 1544 0;
BA_ "DiagResponse" BO_ 1545 1;
BA_ "GenMsgILSupport" BO_ 1545 0;
BA_ "DiagResponse" BO_ 1549 1;
BA_ "GenMsgILSupport" BO_ 1549 0;
BA_ "DiagResponse" BO_ 1550 1;
BA_ "GenMsgILSupport" BO_ 1550 0;
BA_ "DiagResponse" BO_ 1551 1;
BA_ "GenMsgILSupport" BO_ 1551 0;
BA_ "DiagResponse" BO_ 1552 1;
BA_ "GenMsgILSupport" BO_ 1552 0;
BA_ "GenSigSendType" SG_ 1153 CHSKM_BCM_WarnMsg 3;
BA_ "GenSigTimeoutTime_ALL" SG_ 1153 CHSKM_BCM_WarnMsg 5000;
BA_ "InvalidValue" SG_ 1153 CHSKM_BCM_WarnMsg "-";
BA_ "GenSigSendType" SG_ 1153 ALV_BCM_WarnMsg 3;
BA_ "GenSigTimeoutTime_ALL" SG_ 1153 ALV_BCM_WarnMsg 5000;
BA_ "InvalidValue" SG_ 1153 ALV_BCM_WarnMsg "Fh";
BA_ "GenSigSendType" SG_ 1153 BCM_NoValidKey_1 4;
BA_ "GenSigTimeoutTime_ALL" SG_ 1153 BCM_NoValidKey_1 5000;
BA_ "InvalidValue" SG_ 1153 BCM_NoValidKey_1 "-";
BA_ "GenSigSendType" SG_ 1153 BCM_SSB_defect 4;
BA_ "GenSigTimeoutTime_ALL" SG_ 1153 BCM_SSB_defect 5000;
BA_ "InvalidValue" SG_ 1153 BCM_SSB_defect "-";
BA_ "GenSigSendType" SG_ 1153 BCM_WrongGearPosToStart 4;
BA_ "GenSigTimeoutTime_ALL" SG_ 1153 BCM_WrongGearPosToStart 5000;
BA_ "InvalidValue" SG_ 1153 BCM_WrongGearPosToStart "-";
BA_ "GenSigSendType" SG_ 1153 BCM_NoValidKey_2 4;
BA_ "GenSigTimeoutTime_ALL" SG_ 1153 BCM_NoValidKey_2 5000;
BA_ "InvalidValue" SG_ 1153 BCM_NoValidKey_2 "-";
BA_ "GenSigSendType" SG_ 1153 BCM_PressBrakeToStart 4;
BA_ "GenSigTimeoutTime_ALL" SG_ 1153 BCM_PressBrakeToStart 5000;
BA_ "InvalidValue" SG_ 1153 BCM_PressBrakeToStart "-";
BA_ "GenSigSendType" SG_ 1153 BCM_TurnOffPosLightRemindr 4;
BA_ "GenSigTimeoutTime_ALL" SG_ 1153 BCM_TurnOffPosLightRemindr 5000;
BA_ "InvalidValue" SG_ 1153 BCM_TurnOffPosLightRemindr "-";
BA_ "GenSigSendType" SG_ 1153 BCM_KeyFob_LowBattery 4;
BA_ "GenSigTimeoutTime_ALL" SG_ 1153 BCM_KeyFob_LowBattery 5000;
BA_ "InvalidValue" SG_ 1153 BCM_KeyFob_LowBattery "-";
BA_ "GenSigSendType" SG_ 1153 BCM_StopLightDefect 4;
BA_ "GenSigTimeoutTime_ALL" SG_ 1153 BCM_StopLightDefect 5000;
BA_ "InvalidValue" SG_ 1153 BCM_StopLightDefect "-";
BA_ "GenSigSendType" SG_ 1153 BCM_LowBeamDefect 4;
BA_ "GenSigTimeoutTime_ALL" SG_ 1153 BCM_LowBeamDefect 5000;
BA_ "InvalidValue" SG_ 1153 BCM_LowBeamDefect "-";
BA_ "GenSigSendType" SG_ 1153 BCM_HighBeamDefect 4;
BA_ "GenSigTimeoutTime_ALL" SG_ 1153 BCM_HighBeamDefect 5000;
BA_ "InvalidValue" SG_ 1153 BCM_HighBeamDefect "-";
BA_ "GenSigSendType" SG_ 1153 BCM_PositionLightDefect 4;
BA_ "GenSigTimeoutTime_ALL" SG_ 1153 BCM_PositionLightDefect 5000;
BA_ "InvalidValue" SG_ 1153 BCM_PositionLightDefect "-";
BA_ "GenSigSendType" SG_ 1153 BCM_CHMLS_Defect 4;
BA_ "GenSigTimeoutTime_ALL" SG_ 1153 BCM_CHMLS_Defect 5000;
BA_ "InvalidValue" SG_ 1153 BCM_CHMLS_Defect "-";
BA_ "GenSigSendType" SG_ 1153 BCM_LicencePlateLight_Defect 4;
BA_ "GenSigTimeoutTime_ALL" SG_ 1153 BCM_LicencePlateLight_Defect 5000;
BA_ "InvalidValue" SG_ 1153 BCM_LicencePlateLight_Defect "-";
BA_ "GenSigSendType" SG_ 1153 BCM_FrontFog_Defect 4;
BA_ "GenSigTimeoutTime_ALL" SG_ 1153 BCM_FrontFog_Defect 5000;
BA_ "InvalidValue" SG_ 1153 BCM_FrontFog_Defect "-";
BA_ "GenSigSendType" SG_ 1153 BCM_RearFog_Defect 4;
BA_ "GenSigTimeoutTime_ALL" SG_ 1153 BCM_RearFog_Defect 5000;
BA_ "InvalidValue" SG_ 1153 BCM_RearFog_Defect "-";
BA_ "GenSigSendType" SG_ 1153 BCM_ReverseLightDefect 4;
BA_ "GenSigTimeoutTime_ALL" SG_ 1153 BCM_ReverseLightDefect 5000;
BA_ "InvalidValue" SG_ 1153 BCM_ReverseLightDefect "-";
BA_ "GenSigSendType" SG_ 1153 BCM_RLS_Malfunction 4;
BA_ "GenSigTimeoutTime_ALL" SG_ 1153 BCM_RLS_Malfunction 5000;
BA_ "InvalidValue" SG_ 1153 BCM_RLS_Malfunction "-";
BA_ "GenSigSendType" SG_ 1153 BCM_12VBattery_LowLevel 4;
BA_ "GenSigTimeoutTime_ALL" SG_ 1153 BCM_12VBattery_LowLevel 5000;
BA_ "InvalidValue" SG_ 1153 BCM_12VBattery_LowLevel "-";
BA_ "GenSigSendType" SG_ 1153 BCM_ForgetKeyFOBInCar 4;
BA_ "GenSigTimeoutTime_ALL" SG_ 1153 BCM_ForgetKeyFOBInCar 5000;
BA_ "InvalidValue" SG_ 1153 BCM_ForgetKeyFOBInCar "-";
BA_ "GenSigSendType" SG_ 1153 BCM_12VBattery_Discharging 4;
BA_ "GenSigTimeoutTime_ALL" SG_ 1153 BCM_12VBattery_Discharging 5000;
BA_ "InvalidValue" SG_ 1153 BCM_12VBattery_Discharging "-";
BA_ "GenSigSendType" SG_ 1153 BCM_TurnIndicatorDefect 4;
BA_ "GenSigTimeoutTime_ALL" SG_ 1153 BCM_TurnIndicatorDefect 5000;
BA_ "InvalidValue" SG_ 1153 BCM_TurnIndicatorDefect "-";
BA_ "GenSigSendType" SG_ 1153 BCM_dTPMS_Malfunc 4;
BA_ "GenSigTimeoutTime_ALL" SG_ 1153 BCM_dTPMS_Malfunc 5000;
BA_ "InvalidValue" SG_ 1153 BCM_dTPMS_Malfunc "-";
BA_ "GenSigSendType" SG_ 1153 BCM_dTPMS_Malfunc_LostSensor 4;
BA_ "GenSigTimeoutTime_ALL" SG_ 1153 BCM_dTPMS_Malfunc_LostSensor 5000;
BA_ "InvalidValue" SG_ 1153 BCM_dTPMS_Malfunc_LostSensor "-";
BA_ "GenSigSendType" SG_ 1153 BCM_dTPMS_LowPressure 4;
BA_ "GenSigTimeoutTime_ALL" SG_ 1153 BCM_dTPMS_LowPressure 5000;
BA_ "InvalidValue" SG_ 1153 BCM_dTPMS_LowPressure "-";
BA_ "GenSigSendType" SG_ 1153 BCM_dTPMS_RapidLeak 4;
BA_ "GenSigTimeoutTime_ALL" SG_ 1153 BCM_dTPMS_RapidLeak 5000;
BA_ "InvalidValue" SG_ 1153 BCM_dTPMS_RapidLeak "-";
BA_ "GenSigSendType" SG_ 1153 BCM_dTPMS_HighTemperature 4;
BA_ "GenSigTimeoutTime_ALL" SG_ 1153 BCM_dTPMS_HighTemperature 5000;
BA_ "InvalidValue" SG_ 1153 BCM_dTPMS_HighTemperature "-";
BA_ "GenSigSendType" SG_ 1153 BCM_dTPMS_HighPressure 4;
BA_ "GenSigTimeoutTime_ALL" SG_ 1153 BCM_dTPMS_HighPressure 5000;
BA_ "InvalidValue" SG_ 1153 BCM_dTPMS_HighPressure "-";
BA_ "GenSigSendType" SG_ 1153 BCM_dTPMS_LowBattery 4;
BA_ "GenSigTimeoutTime_ALL" SG_ 1153 BCM_dTPMS_LowBattery 5000;
BA_ "InvalidValue" SG_ 1153 BCM_dTPMS_LowBattery "-";
BA_ "GenSigSendType" SG_ 1153 BCM_Keyfob_Leftcar 4;
BA_ "GenSigTimeoutTime_ALL" SG_ 1153 BCM_Keyfob_Leftcar 5000;
BA_ "InvalidValue" SG_ 1153 BCM_Keyfob_Leftcar "-";
BA_ "GenSigSendType" SG_ 1153 BCM_IDB_Brakelight_Malfunction 4;
BA_ "GenSigTimeoutTime_ALL" SG_ 1153 BCM_IDB_Brakelight_Malfunction 5000;
BA_ "InvalidValue" SG_ 1153 BCM_IDB_Brakelight_Malfunction "-";
BA_ "GenSigSendType" SG_ 1153 BCM_VCU_Brakelight_Malfunction 4;
BA_ "GenSigTimeoutTime_ALL" SG_ 1153 BCM_VCU_Brakelight_Malfunction 5000;
BA_ "InvalidValue" SG_ 1153 BCM_VCU_Brakelight_Malfunction "-";
BA_ "GenSigSendType" SG_ 1153 BCM_ADAS_Turnlight_Malfunction 4;
BA_ "GenSigTimeoutTime_ALL" SG_ 1153 BCM_ADAS_Turnlight_Malfunction 5000;
BA_ "InvalidValue" SG_ 1153 BCM_ADAS_Turnlight_Malfunction "-";
BA_ "GenSigSendType" SG_ 1153 BCM_ADAS_Highbeam_Malfunction 4;
BA_ "GenSigTimeoutTime_ALL" SG_ 1153 BCM_ADAS_Highbeam_Malfunction 5000;
BA_ "InvalidValue" SG_ 1153 BCM_ADAS_Highbeam_Malfunction "-";
BA_ "GenSigSendType" SG_ 1153 BCM_ADAS_LowBeam_Malfunction 4;
BA_ "GenSigTimeoutTime_ALL" SG_ 1153 BCM_ADAS_LowBeam_Malfunction 5000;
BA_ "InvalidValue" SG_ 1153 BCM_ADAS_LowBeam_Malfunction "-";
BA_ "GenSigSendType" SG_ 1153 BCM_MHU_Malfunction 4;
BA_ "GenSigTimeoutTime_ALL" SG_ 1153 BCM_MHU_Malfunction 5000;
BA_ "InvalidValue" SG_ 1153 BCM_MHU_Malfunction "-";
BA_ "GenSigSendType" SG_ 1153 BCM_BCM_Malfunction 4;
BA_ "GenSigTimeoutTime_ALL" SG_ 1153 BCM_BCM_Malfunction 5000;
BA_ "InvalidValue" SG_ 1153 BCM_BCM_Malfunction "-";
BA_ "GenSigSendType" SG_ 1153 BCM_SCM_Malfunction 4;
BA_ "GenSigTimeoutTime_ALL" SG_ 1153 BCM_SCM_Malfunction 5000;
BA_ "InvalidValue" SG_ 1153 BCM_SCM_Malfunction "-";
BA_ "GenSigSendType" SG_ 1153 BCM_CrashSignalDefect 4;
BA_ "GenSigTimeoutTime_ALL" SG_ 1153 BCM_CrashSignalDefect 5000;
BA_ "InvalidValue" SG_ 1153 BCM_CrashSignalDefect "-";
BA_ "GenSigSendType" SG_ 1153 BCM_FrontWiperDefect 4;
BA_ "GenSigTimeoutTime_ALL" SG_ 1153 BCM_FrontWiperDefect 5000;
BA_ "InvalidValue" SG_ 1153 BCM_FrontWiperDefect "-";
BA_ "GenSigSendType" SG_ 1153 BCM_Rear_RightDoorLockDefect 4;
BA_ "GenSigTimeoutTime_ALL" SG_ 1153 BCM_Rear_RightDoorLockDefect 5000;
BA_ "InvalidValue" SG_ 1153 BCM_Rear_RightDoorLockDefect "-";
BA_ "GenSigSendType" SG_ 1153 BCM_RearLeftDoorLockDefect 4;
BA_ "GenSigTimeoutTime_ALL" SG_ 1153 BCM_RearLeftDoorLockDefect 5000;
BA_ "InvalidValue" SG_ 1153 BCM_RearLeftDoorLockDefect "-";
BA_ "GenSigSendType" SG_ 1153 BCM_Front_RightDoorLockDefect 4;
BA_ "GenSigTimeoutTime_ALL" SG_ 1153 BCM_Front_RightDoorLockDefect 5000;
BA_ "InvalidValue" SG_ 1153 BCM_Front_RightDoorLockDefect "-";
BA_ "GenSigSendType" SG_ 1153 BCM_FrontLeftDoorLockDefect 4;
BA_ "GenSigTimeoutTime_ALL" SG_ 1153 BCM_FrontLeftDoorLockDefect 5000;
BA_ "InvalidValue" SG_ 1153 BCM_FrontLeftDoorLockDefect "-";
BA_ "GenSigSendType" SG_ 1153 BCM_LDML_Malfunction 4;
BA_ "GenSigTimeoutTime_ALL" SG_ 1153 BCM_LDML_Malfunction 5000;
BA_ "InvalidValue" SG_ 1153 BCM_LDML_Malfunction "-";
BA_ "GenSigSendType" SG_ 1153 BCM_LDMR_Malfunction 4;
BA_ "GenSigTimeoutTime_ALL" SG_ 1153 BCM_LDMR_Malfunction 5000;
BA_ "InvalidValue" SG_ 1153 BCM_LDMR_Malfunction "-";
BA_ "GenSigSendType" SG_ 1153 BCM_RLBL_Malfunction 4;
BA_ "GenSigTimeoutTime_ALL" SG_ 1153 BCM_RLBL_Malfunction 5000;
BA_ "InvalidValue" SG_ 1153 BCM_RLBL_Malfunction "-";
BA_ "GenSigSendType" SG_ 1153 BCM_RLBR_Malfunction 4;
BA_ "GenSigTimeoutTime_ALL" SG_ 1153 BCM_RLBR_Malfunction 5000;
BA_ "InvalidValue" SG_ 1153 BCM_RLBR_Malfunction "-";
BA_ "GenSigSendType" SG_ 1153 BCM_RLT_Malfunction 4;
BA_ "GenSigTimeoutTime_ALL" SG_ 1153 BCM_RLT_Malfunction 5000;
BA_ "InvalidValue" SG_ 1153 BCM_RLT_Malfunction "-";
BA_ "GenSigSendType" SG_ 1153 BCM_BCM_POWER_Malfunction 4;
BA_ "GenSigTimeoutTime_ALL" SG_ 1153 BCM_BCM_POWER_Malfunction 5000;
BA_ "InvalidValue" SG_ 1153 BCM_BCM_POWER_Malfunction "-";
BA_ "GenSigSendType" SG_ 1153 BCM_IDB_AutoHazardBlinking_Malf 4;
BA_ "GenSigTimeoutTime_ALL" SG_ 1153 BCM_IDB_AutoHazardBlinking_Malf 5000;
BA_ "InvalidValue" SG_ 1153 BCM_IDB_AutoHazardBlinking_Malf "-";
BA_ "GenSigTimeoutTime_ALL" SG_ 1153 BCM_AutoHLLevelingFault 5000;
BA_ "InvalidValue" SG_ 1153 BCM_AutoHLLevelingFault "-";
BA_ "GenSigSendType" SG_ 1154 CHSKM_XGW_WarnMsg 3;
BA_ "GenSigTimeoutTime_ALL" SG_ 1154 CHSKM_XGW_WarnMsg 5000;
BA_ "GenSigSendType" SG_ 1154 ALV_XGW_WarnMsg 3;
BA_ "GenSigTimeoutTime_ALL" SG_ 1154 ALV_XGW_WarnMsg 5000;
BA_ "InvalidValue" SG_ 1154 ALV_XGW_WarnMsg "Fh";
BA_ "GenSigSendType" SG_ 1154 XGW_AutoHLLevelingFault 4;
BA_ "GenSigTimeoutTime_ALL" SG_ 1154 XGW_AutoHLLevelingFault 5000;
BA_ "GenSigSendType" SG_ 1154 XGW_WasherFluidLvlSw 4;
BA_ "GenSigTimeoutTime_ALL" SG_ 1154 XGW_WasherFluidLvlSw 5000;
BA_ "GenSigSendType" SG_ 1154 XGW_Warning_Flag_3 4;
BA_ "GenSigTimeoutTime_ALL" SG_ 1154 XGW_Warning_Flag_3 5000;
BA_ "GenSigSendType" SG_ 1154 XGW_Warning_Flag_4 4;
BA_ "GenSigTimeoutTime_ALL" SG_ 1154 XGW_Warning_Flag_4 5000;
BA_ "GenSigSendType" SG_ 1154 XGW_Warning_Flag_5 4;
BA_ "GenSigTimeoutTime_ALL" SG_ 1154 XGW_Warning_Flag_5 5000;
BA_ "GenSigSendType" SG_ 1154 XGW_Warning_Flag_6 4;
BA_ "GenSigTimeoutTime_ALL" SG_ 1154 XGW_Warning_Flag_6 5000;
BA_ "GenSigSendType" SG_ 1154 XGW_Warning_Flag_7 4;
BA_ "GenSigTimeoutTime_ALL" SG_ 1154 XGW_Warning_Flag_7 5000;
BA_ "GenSigSendType" SG_ 1154 XGW_Warning_Flag_8 4;
BA_ "GenSigTimeoutTime_ALL" SG_ 1154 XGW_Warning_Flag_8 5000;
BA_ "GenSigSendType" SG_ 1154 XGW_Warning_Flag_9 4;
BA_ "GenSigTimeoutTime_ALL" SG_ 1154 XGW_Warning_Flag_9 5000;
BA_ "GenSigSendType" SG_ 1154 XGW_Warning_Flag_10 4;
BA_ "GenSigTimeoutTime_ALL" SG_ 1154 XGW_Warning_Flag_10 5000;
BA_ "GenSigSendType" SG_ 1154 XGW_Warning_Flag_11 4;
BA_ "GenSigTimeoutTime_ALL" SG_ 1154 XGW_Warning_Flag_11 5000;
BA_ "GenSigSendType" SG_ 1154 XGW_Warning_Flag_12 4;
BA_ "GenSigTimeoutTime_ALL" SG_ 1154 XGW_Warning_Flag_12 5000;
BA_ "GenSigSendType" SG_ 1154 XGW_Reserved_signal1 4;
BA_ "GenSigTimeoutTime_ALL" SG_ 1154 XGW_Reserved_signal1 5000;
BA_ "GenSigSendType" SG_ 1154 XGW_Reserved_signal2 4;
BA_ "GenSigTimeoutTime_ALL" SG_ 1154 XGW_Reserved_signal2 5000;
BA_ "GenSigSendType" SG_ 1154 XGW_Reserved_signal3 4;
BA_ "GenSigTimeoutTime_ALL" SG_ 1154 XGW_Reserved_signal3 5000;
BA_ "GenSigSendType" SG_ 1154 XGW_Reserved_signal4 4;
BA_ "GenSigTimeoutTime_ALL" SG_ 1154 XGW_Reserved_signal4 5000;
BA_ "GenSigSendType" SG_ 1154 XGW_Reserved_signal5 4;
BA_ "GenSigTimeoutTime_ALL" SG_ 1154 XGW_Reserved_signal5 5000;
BA_ "GenSigTimeoutTime_ALL" SG_ 1155 TPMS_FLTirePress 500;
BA_ "InvalidValue" SG_ 1155 TPMS_FLTirePress "FFh";
BA_ "GenSigTimeoutTime_ALL" SG_ 1155 TPMS_FRTirePress 500;
BA_ "InvalidValue" SG_ 1155 TPMS_FRTirePress "FFh";
BA_ "GenSigTimeoutTime_ALL" SG_ 1155 TPMS_RLTirePress 500;
BA_ "InvalidValue" SG_ 1155 TPMS_RLTirePress "FFh";
BA_ "GenSigTimeoutTime_ALL" SG_ 1155 TPMS_RRTirePress 500;
BA_ "InvalidValue" SG_ 1155 TPMS_RRTirePress "FFh";
BA_ "GenSigTimeoutTime_ALL" SG_ 1155 TPMS_FLTirePressAlarm 500;
BA_ "InvalidValue" SG_ 1155 TPMS_FLTirePressAlarm "null";
BA_ "GenSigTimeoutTime_ALL" SG_ 1155 TPMS_FRTirePressAlarm 500;
BA_ "InvalidValue" SG_ 1155 TPMS_FRTirePressAlarm "null";
BA_ "GenSigTimeoutTime_ALL" SG_ 1155 TPMS_RLTirePressAlarm 500;
BA_ "InvalidValue" SG_ 1155 TPMS_RLTirePressAlarm "null";
BA_ "GenSigTimeoutTime_ALL" SG_ 1155 TPMS_RRTirePressAlarm 500;
BA_ "InvalidValue" SG_ 1155 TPMS_RRTirePressAlarm "null";
BA_ "GenSigTimeoutTime_ALL" SG_ 1155 TPMS_TirePosition 500;
BA_ "InvalidValue" SG_ 1155 TPMS_TirePosition "null";
BA_ "GenSigTimeoutTime_ALL" SG_ 1155 TPMS_ready2learning 500;
BA_ "GenSigTimeoutTime_ALL" SG_ 1155 TPMS_TireTempAlarm 500;
BA_ "InvalidValue" SG_ 1155 TPMS_TireTempAlarm "null";
BA_ "GenSigTimeoutTime_ALL" SG_ 1155 TPMS_LearningStatus 500;
BA_ "GenSigStartValue" SG_ 1155 TPMS_TireTemp 68;
BA_ "GenSigTimeoutTime_ALL" SG_ 1155 TPMS_TireTemp 500;
BA_ "InvalidValue" SG_ 1155 TPMS_TireTemp "FFh";
BA_ "GenSigTimeoutTime_ALL" SG_ 1156 CHKSM_APA_FEEDBACK_MHU 500;
BA_ "GenSigTimeoutTime_ALL" SG_ 1156 ALV_APA_FEEDBACK_MHU 500;
BA_ "InvalidValue" SG_ 1156 ALV_APA_FEEDBACK_MHU "Fh";
BA_ "GenSigTimeoutTime_ALL" SG_ 1156 APA_ReqInfoDispTxt3 500;
BA_ "InvalidValue" SG_ 1156 APA_ReqInfoDispTxt3 "1Fh";
BA_ "GenSigTimeoutTime_ALL" SG_ 1156 APA_ReqInfoDispTxt4 500;
BA_ "InvalidValue" SG_ 1156 APA_ReqInfoDispTxt4 "Fh";
BA_ "GenSigTimeoutTime_ALL" SG_ 1156 APA_ReqInfoDispTxt2 500;
BA_ "InvalidValue" SG_ 1156 APA_ReqInfoDispTxt2 "7h";
BA_ "GenSigTimeoutTime_ALL" SG_ 1156 APA_ReqInfoDispTxt1 500;
BA_ "InvalidValue" SG_ 1156 APA_ReqInfoDispTxt1 "7h";
BA_ "GenSigTimeoutTime_ALL" SG_ 1156 APA_MHU_Displayparkingtype 500;
BA_ "GenSigTimeoutTime_ALL" SG_ 1156 APA_FuncModeFdbck 500;
BA_ "InvalidValue" SG_ 1156 APA_FuncModeFdbck "3h";
BA_ "GenSigTimeoutTime_ALL" SG_ 1156 SECCAN_APA_FEEDBACK_MHU 500;
BA_ "GenSigTimeoutTime_ALL" SG_ 1156 APA_RecommendSlotID 500;
BA_ "InvalidValue" SG_ 1156 APA_RecommendSlotID "FFh";
BA_ "GenSigTimeoutTime_ALL" SG_ 1156 APA_Currentfunction 500;
BA_ "InvalidValue" SG_ 1156 APA_Currentfunction "7h";
BA_ "GenSigTimeoutTime_ALL" SG_ 1156 APA_MHU_Status 500;
BA_ "InvalidValue" SG_ 1156 APA_MHU_Status "7h";
BA_ "InvalidValue" SG_ 1157 TBOX_RPADirSel "Fh";
BA_ "GenSigTimeoutTime_ALL" SG_ 1158 CHKSM_TirePressAlarm 500;
BA_ "GenSigTimeoutTime_ALL" SG_ 1158 ALV_TirePressAlarm 500;
BA_ "InvalidValue" SG_ 1158 ALV_TirePressAlarm "Fh";
BA_ "GenSigTimeoutTime_ALL" SG_ 1158 TPMS_FLTirePressAlarm2 500;
BA_ "GenSigTimeoutTime_ALL" SG_ 1158 TPMS_FRTirePressAlarm2 500;
BA_ "GenSigTimeoutTime_ALL" SG_ 1158 TPMS_RLTirePressAlarm2 500;
BA_ "GenSigTimeoutTime_ALL" SG_ 1158 TPMS_RRTirePressAlarm2 500;
BA_ "GenSigSendType" SG_ 1160 CHKSM_ACM_WARNING_MSG 3;
BA_ "GenSigTimeoutTime_ALL" SG_ 1160 CHKSM_ACM_WARNING_MSG 5000;
BA_ "InvalidValue" SG_ 1160 CHKSM_ACM_WARNING_MSG "null";
BA_ "GenSigSendType" SG_ 1160 ALV_ACM_WARNING_MSG 3;
BA_ "GenSigTimeoutTime_ALL" SG_ 1160 ALV_ACM_WARNING_MSG 5000;
BA_ "InvalidValue" SG_ 1160 ALV_ACM_WARNING_MSG "Fh";
BA_ "GenSigSendType" SG_ 1160 ACM_Malfunction 4;
BA_ "GenSigTimeoutTime_ALL" SG_ 1160 ACM_Malfunction 5000;
BA_ "InvalidValue" SG_ 1160 ACM_Malfunction "null";
BA_ "GenSigSendType" SG_ 1160 ACM_Pre_Drive_Check 4;
BA_ "GenSigTimeoutTime_ALL" SG_ 1160 ACM_Pre_Drive_Check 5000;
BA_ "InvalidValue" SG_ 1160 ACM_Pre_Drive_Check "null";
BA_ "GenSigSendType" SG_ 1160 ACM_in_Plant_Mode 4;
BA_ "GenSigTimeoutTime_ALL" SG_ 1160 ACM_in_Plant_Mode 5000;
BA_ "InvalidValue" SG_ 1160 ACM_in_Plant_Mode "null";
BA_ "GenSigSendType" SG_ 1160 ACM_PAB_Suppression 4;
BA_ "GenSigTimeoutTime_ALL" SG_ 1160 ACM_PAB_Suppression 5000;
BA_ "InvalidValue" SG_ 1160 ACM_PAB_Suppression "3h";
BA_ "GenSigSendType" SG_ 1160 ACM_Airbag_Disabled 4;
BA_ "GenSigTimeoutTime_ALL" SG_ 1160 ACM_Airbag_Disabled 5000;
BA_ "InvalidValue" SG_ 1160 ACM_Airbag_Disabled "null";
BA_ "GenSigSendType" SG_ 1160 ACM_Development_Calibration 4;
BA_ "GenSigTimeoutTime_ALL" SG_ 1160 ACM_Development_Calibration 5000;
BA_ "InvalidValue" SG_ 1160 ACM_Development_Calibration "null";
BA_ "GenSigSendType" SG_ 1160 ACM_In_Disposal_Mode 4;
BA_ "GenSigTimeoutTime_ALL" SG_ 1160 ACM_In_Disposal_Mode 5000;
BA_ "InvalidValue" SG_ 1160 ACM_In_Disposal_Mode "null";
BA_ "GenSigSendType" SG_ 1160 ACM_Seatbelt_Reminder_Request 4;
BA_ "GenSigTimeoutTime_ALL" SG_ 1160 ACM_Seatbelt_Reminder_Request 5000;
BA_ "InvalidValue" SG_ 1160 ACM_Seatbelt_Reminder_Request "null";
BA_ "GenSigSendType" SG_ 1160 ACM_SBR_Chime_Req 4;
BA_ "GenSigTimeoutTime_ALL" SG_ 1160 ACM_SBR_Chime_Req 5000;
BA_ "InvalidValue" SG_ 1160 ACM_SBR_Chime_Req "null";
BA_ "GenSigSendType" SG_ 1160 ACM_SBR_Blinking_Req 4;
BA_ "GenSigTimeoutTime_ALL" SG_ 1160 ACM_SBR_Blinking_Req 5000;
BA_ "InvalidValue" SG_ 1160 ACM_SBR_Blinking_Req "null";
BA_ "GenSigTimeoutTime_ALL" SG_ 1161 CHSKM_CCU_WarnMsg 500;
BA_ "InvalidValue" SG_ 1161 CHSKM_CCU_WarnMsg "null";
BA_ "GenSigTimeoutTime_ALL" SG_ 1161 ALV_CCU_WarnMsg 500;
BA_ "InvalidValue" SG_ 1161 ALV_CCU_WarnMsg "Fh";
BA_ "GenSigTimeoutTime_ALL" SG_ 1161 CCU_Malfunction 500;
BA_ "InvalidValue" SG_ 1161 CCU_Malfunction "null";
BA_ "GenSigTimeoutTime_ALL" SG_ 1161 CCU_Warning_Flag_2 500;
BA_ "InvalidValue" SG_ 1161 CCU_Warning_Flag_2 "null";
BA_ "GenSigTimeoutTime_ALL" SG_ 1161 CCU_Warning_Flag_3 500;
BA_ "InvalidValue" SG_ 1161 CCU_Warning_Flag_3 "null";
BA_ "GenSigTimeoutTime_ALL" SG_ 1161 CCU_Warning_Flag_4 500;
BA_ "InvalidValue" SG_ 1161 CCU_Warning_Flag_4 "null";
BA_ "GenSigTimeoutTime_ALL" SG_ 1161 CCU_Warning_Flag_5 500;
BA_ "InvalidValue" SG_ 1161 CCU_Warning_Flag_5 "null";
BA_ "GenSigTimeoutTime_ALL" SG_ 1161 CCU_Warning_Flag_6 500;
BA_ "InvalidValue" SG_ 1161 CCU_Warning_Flag_6 "null";
BA_ "GenSigTimeoutTime_ALL" SG_ 1161 CCU_Warning_Flag_7 500;
BA_ "InvalidValue" SG_ 1161 CCU_Warning_Flag_7 "null";
BA_ "GenSigTimeoutTime_ALL" SG_ 1161 CCU_Warning_Flag_8 500;
BA_ "InvalidValue" SG_ 1161 CCU_Warning_Flag_8 "null";
BA_ "GenSigTimeoutTime_ALL" SG_ 1161 CCU_Warning_Flag_9 500;
BA_ "InvalidValue" SG_ 1161 CCU_Warning_Flag_9 "null";
BA_ "GenSigTimeoutTime_ALL" SG_ 1161 CCU_Warning_Flag_10 500;
BA_ "InvalidValue" SG_ 1161 CCU_Warning_Flag_10 "null";
BA_ "GenSigTimeoutTime_ALL" SG_ 1161 CCU_Warning_Flag_11 500;
BA_ "InvalidValue" SG_ 1161 CCU_Warning_Flag_11 "null";
BA_ "GenSigTimeoutTime_ALL" SG_ 1161 CCU_Warning_Flag_12 500;
BA_ "InvalidValue" SG_ 1161 CCU_Warning_Flag_12 "null";
BA_ "GenSigSendType" SG_ 1165 CHSKM_HUD_WarnMsg 3;
BA_ "GenSigTimeoutTime_ALL" SG_ 1165 CHSKM_HUD_WarnMsg 5000;
BA_ "GenSigSendType" SG_ 1165 ALV_HUD_WarnMsg 3;
BA_ "GenSigTimeoutTime_ALL" SG_ 1165 ALV_HUD_WarnMsg 5000;
BA_ "InvalidValue" SG_ 1165 ALV_HUD_WarnMsg "Fh";
BA_ "GenSigSendType" SG_ 1165 HUD_Malfunction 4;
BA_ "GenSigTimeoutTime_ALL" SG_ 1165 HUD_Malfunction 5000;
BA_ "GenSigSendType" SG_ 1165 HUD_Failed_Temporary 4;
BA_ "GenSigTimeoutTime_ALL" SG_ 1165 HUD_Failed_Temporary 5000;
BA_ "GenSigSendType" SG_ 1165 HUD_Overheating 4;
BA_ "GenSigTimeoutTime_ALL" SG_ 1165 HUD_Overheating 5000;
BA_ "GenSigSendType" SG_ 1165 HUD_Warning_Flag_4 4;
BA_ "GenSigTimeoutTime_ALL" SG_ 1165 HUD_Warning_Flag_4 5000;
BA_ "GenSigSendType" SG_ 1165 HUD_Warning_Flag_5 4;
BA_ "GenSigTimeoutTime_ALL" SG_ 1165 HUD_Warning_Flag_5 5000;
BA_ "GenSigSendType" SG_ 1165 HUD_Warning_Flag_6 4;
BA_ "GenSigTimeoutTime_ALL" SG_ 1165 HUD_Warning_Flag_6 5000;
BA_ "GenSigSendType" SG_ 1165 HUD_Warning_Flag_7 4;
BA_ "GenSigTimeoutTime_ALL" SG_ 1165 HUD_Warning_Flag_7 5000;
BA_ "GenSigSendType" SG_ 1165 HUD_Warning_Flag_8 4;
BA_ "GenSigTimeoutTime_ALL" SG_ 1165 HUD_Warning_Flag_8 5000;
BA_ "GenSigSendType" SG_ 1165 HUD_Warning_Flag_9 4;
BA_ "GenSigTimeoutTime_ALL" SG_ 1165 HUD_Warning_Flag_9 5000;
BA_ "GenSigSendType" SG_ 1165 HUD_Warning_Flag_10 4;
BA_ "GenSigTimeoutTime_ALL" SG_ 1165 HUD_Warning_Flag_10 5000;
BA_ "GenSigSendType" SG_ 1165 HUD_Warning_Flag_11 4;
BA_ "GenSigTimeoutTime_ALL" SG_ 1165 HUD_Warning_Flag_11 5000;
BA_ "GenSigSendType" SG_ 1165 HUD_Warning_Flag_12 4;
BA_ "GenSigTimeoutTime_ALL" SG_ 1165 HUD_Warning_Flag_12 5000;
BA_ "GenSigSendType" SG_ 1165 SECCAN_HUDWarn 3;
BA_ "GenSigTimeoutTime_ALL" SG_ 1165 SECCAN_HUDWarn 5000;
BA_ "GenSigTimeoutTime_ALL" SG_ 1166 CHSKM_ETG_WarnMsg 500;
BA_ "InvalidValue" SG_ 1166 CHSKM_ETG_WarnMsg "null";
BA_ "GenSigTimeoutTime_ALL" SG_ 1166 ALV_ETG_WarnMsg 500;
BA_ "InvalidValue" SG_ 1166 ALV_ETG_WarnMsg "Fh";
BA_ "GenSigTimeoutTime_ALL" SG_ 1166 ETG_Malfunction 500;
BA_ "InvalidValue" SG_ 1166 ETG_Malfunction "null";
BA_ "GenSigTimeoutTime_ALL" SG_ 1166 ETG_Warning_Flag_2 500;
BA_ "InvalidValue" SG_ 1166 ETG_Warning_Flag_2 "null";
BA_ "GenSigTimeoutTime_ALL" SG_ 1166 ETG_Warning_Flag_3 500;
BA_ "InvalidValue" SG_ 1166 ETG_Warning_Flag_3 "null";
BA_ "GenSigTimeoutTime_ALL" SG_ 1166 ETG_Warning_Flag_4 500;
BA_ "InvalidValue" SG_ 1166 ETG_Warning_Flag_4 "null";
BA_ "GenSigTimeoutTime_ALL" SG_ 1166 ETG_Warning_Flag_5 500;
BA_ "InvalidValue" SG_ 1166 ETG_Warning_Flag_5 "null";
BA_ "GenSigTimeoutTime_ALL" SG_ 1166 ETG_Warning_Flag_6 500;
BA_ "InvalidValue" SG_ 1166 ETG_Warning_Flag_6 "null";
BA_ "GenSigTimeoutTime_ALL" SG_ 1166 ETG_Warning_Flag_7 500;
BA_ "InvalidValue" SG_ 1166 ETG_Warning_Flag_7 "null";
BA_ "GenSigTimeoutTime_ALL" SG_ 1166 ETG_Warning_Flag_8 500;
BA_ "InvalidValue" SG_ 1166 ETG_Warning_Flag_8 "null";
BA_ "GenSigTimeoutTime_ALL" SG_ 1166 ETG_Warning_Flag_9 500;
BA_ "InvalidValue" SG_ 1166 ETG_Warning_Flag_9 "null";
BA_ "GenSigTimeoutTime_ALL" SG_ 1166 ETG_Warning_Flag_10 500;
BA_ "InvalidValue" SG_ 1166 ETG_Warning_Flag_10 "null";
BA_ "GenSigTimeoutTime_ALL" SG_ 1166 ETG_Warning_Flag_11 500;
BA_ "InvalidValue" SG_ 1166 ETG_Warning_Flag_11 "null";
BA_ "GenSigTimeoutTime_ALL" SG_ 1166 ETG_Warning_Flag_12 500;
BA_ "InvalidValue" SG_ 1166 ETG_Warning_Flag_12 "null";
BA_ "GenSigSendType" SG_ 1168 CHSKM_GS_WarnMsg 3;
BA_ "GenSigTimeoutTime_ALL" SG_ 1168 CHSKM_GS_WarnMsg 5000;
BA_ "InvalidValue" SG_ 1168 CHSKM_GS_WarnMsg "null";
BA_ "GenSigSendType" SG_ 1168 ALV_GS_WarnMsg 3;
BA_ "GenSigTimeoutTime_ALL" SG_ 1168 ALV_GS_WarnMsg 5000;
BA_ "InvalidValue" SG_ 1168 ALV_GS_WarnMsg "Fh";
BA_ "GenSigSendType" SG_ 1168 GS_Warning_Flag_1 4;
BA_ "GenSigTimeoutTime_ALL" SG_ 1168 GS_Warning_Flag_1 5000;
BA_ "InvalidValue" SG_ 1168 GS_Warning_Flag_1 "null";
BA_ "GenSigSendType" SG_ 1168 GS_Warning_Flag_2 4;
BA_ "GenSigTimeoutTime_ALL" SG_ 1168 GS_Warning_Flag_2 5000;
BA_ "InvalidValue" SG_ 1168 GS_Warning_Flag_2 "null";
BA_ "GenSigSendType" SG_ 1168 GS_Warning_Flag_3 4;
BA_ "GenSigTimeoutTime_ALL" SG_ 1168 GS_Warning_Flag_3 5000;
BA_ "InvalidValue" SG_ 1168 GS_Warning_Flag_3 "null";
BA_ "GenSigSendType" SG_ 1168 GS_Warning_Flag_4 4;
BA_ "GenSigTimeoutTime_ALL" SG_ 1168 GS_Warning_Flag_4 5000;
BA_ "InvalidValue" SG_ 1168 GS_Warning_Flag_4 "null";
BA_ "GenSigSendType" SG_ 1168 GS_Warning_Flag_5 4;
BA_ "GenSigTimeoutTime_ALL" SG_ 1168 GS_Warning_Flag_5 5000;
BA_ "InvalidValue" SG_ 1168 GS_Warning_Flag_5 "null";
BA_ "GenSigSendType" SG_ 1168 GS_Warning_Flag_6 4;
BA_ "GenSigTimeoutTime_ALL" SG_ 1168 GS_Warning_Flag_6 5000;
BA_ "InvalidValue" SG_ 1168 GS_Warning_Flag_6 "null";
BA_ "GenSigSendType" SG_ 1168 GS_Warning_Flag_7 4;
BA_ "GenSigTimeoutTime_ALL" SG_ 1168 GS_Warning_Flag_7 5000;
BA_ "InvalidValue" SG_ 1168 GS_Warning_Flag_7 "null";
BA_ "GenSigSendType" SG_ 1168 GS_Warning_Flag_8 4;
BA_ "GenSigTimeoutTime_ALL" SG_ 1168 GS_Warning_Flag_8 5000;
BA_ "InvalidValue" SG_ 1168 GS_Warning_Flag_8 "null";
BA_ "GenSigSendType" SG_ 1168 GS_Warning_Flag_9 4;
BA_ "GenSigTimeoutTime_ALL" SG_ 1168 GS_Warning_Flag_9 5000;
BA_ "InvalidValue" SG_ 1168 GS_Warning_Flag_9 "null";
BA_ "GenSigSendType" SG_ 1168 GS_Warning_Flag_10 4;
BA_ "GenSigTimeoutTime_ALL" SG_ 1168 GS_Warning_Flag_10 5000;
BA_ "InvalidValue" SG_ 1168 GS_Warning_Flag_10 "null";
BA_ "GenSigSendType" SG_ 1168 GS_Warning_Flag_11 4;
BA_ "GenSigTimeoutTime_ALL" SG_ 1168 GS_Warning_Flag_11 5000;
BA_ "InvalidValue" SG_ 1168 GS_Warning_Flag_11 "null";
BA_ "GenSigSendType" SG_ 1168 GS_Warning_Flag_12 4;
BA_ "GenSigTimeoutTime_ALL" SG_ 1168 GS_Warning_Flag_12 5000;
BA_ "InvalidValue" SG_ 1168 GS_Warning_Flag_12 "null";
BA_ "GenSigSendType" SG_ 1168 GS_Reserved_signal1 4;
BA_ "GenSigTimeoutTime_ALL" SG_ 1168 GS_Reserved_signal1 5000;
BA_ "InvalidValue" SG_ 1168 GS_Reserved_signal1 "null";
BA_ "GenSigSendType" SG_ 1168 GS_Reserved_signal2 4;
BA_ "GenSigTimeoutTime_ALL" SG_ 1168 GS_Reserved_signal2 5000;
BA_ "InvalidValue" SG_ 1168 GS_Reserved_signal2 "null";
BA_ "GenSigSendType" SG_ 1168 GS_Reserved_signal3 4;
BA_ "GenSigTimeoutTime_ALL" SG_ 1168 GS_Reserved_signal3 5000;
BA_ "InvalidValue" SG_ 1168 GS_Reserved_signal3 "null";
BA_ "GenSigSendType" SG_ 1168 GS_Reserved_signal4 4;
BA_ "GenSigTimeoutTime_ALL" SG_ 1168 GS_Reserved_signal4 5000;
BA_ "InvalidValue" SG_ 1168 GS_Reserved_signal4 "null";
BA_ "GenSigSendType" SG_ 1168 GS_Reserved_signal5 4;
BA_ "GenSigTimeoutTime_ALL" SG_ 1168 GS_Reserved_signal5 5000;
BA_ "InvalidValue" SG_ 1168 GS_Reserved_signal5 "null";
BA_ "GenSigSendType" SG_ 1171 CHSKM_BMS_WarnMsg 3;
BA_ "GenSigTimeoutTime_ALL" SG_ 1171 CHSKM_BMS_WarnMsg 5000;
BA_ "InvalidValue" SG_ 1171 CHSKM_BMS_WarnMsg "null";
BA_ "GenSigSendType" SG_ 1171 ALV_BMS_WarnMsg 3;
BA_ "GenSigTimeoutTime_ALL" SG_ 1171 ALV_BMS_WarnMsg 5000;
BA_ "InvalidValue" SG_ 1171 ALV_BMS_WarnMsg "Fh";
BA_ "GenSigSendType" SG_ 1171 BMS_PackTempSts 4;
BA_ "GenSigTimeoutTime_ALL" SG_ 1171 BMS_PackTempSts 5000;
BA_ "InvalidValue" SG_ 1171 BMS_PackTempSts "null";
BA_ "GenSigSendType" SG_ 1171 BMS_ThermalRunaway 4;
BA_ "GenSigTimeoutTime_ALL" SG_ 1171 BMS_ThermalRunaway 5000;
BA_ "InvalidValue" SG_ 1171 BMS_ThermalRunaway "null";
BA_ "GenSigSendType" SG_ 1171 BMS_BatteryReplacement 4;
BA_ "GenSigTimeoutTime_ALL" SG_ 1171 BMS_BatteryReplacement 5000;
BA_ "InvalidValue" SG_ 1171 BMS_BatteryReplacement "null";
BA_ "GenSigSendType" SG_ 1171 BMS_Warning_PowerDegrade 4;
BA_ "GenSigTimeoutTime_ALL" SG_ 1171 BMS_Warning_PowerDegrade 5000;
BA_ "InvalidValue" SG_ 1171 BMS_Warning_PowerDegrade "null";
BA_ "GenSigSendType" SG_ 1171 BMS_Warning_DeltaSoC 4;
BA_ "GenSigTimeoutTime_ALL" SG_ 1171 BMS_Warning_DeltaSoC 5000;
BA_ "InvalidValue" SG_ 1171 BMS_Warning_DeltaSoC "null";
BA_ "GenSigSendType" SG_ 1171 BMS_Warning_HVILSts 4;
BA_ "GenSigTimeoutTime_ALL" SG_ 1171 BMS_Warning_HVILSts 5000;
BA_ "InvalidValue" SG_ 1171 BMS_Warning_HVILSts "null";
BA_ "GenSigSendType" SG_ 1171 BMS_Warning_Isolation 4;
BA_ "GenSigTimeoutTime_ALL" SG_ 1171 BMS_Warning_Isolation 5000;
BA_ "InvalidValue" SG_ 1171 BMS_Warning_Isolation "null";
BA_ "GenSigSendType" SG_ 1171 BMS_Warning_CoolantLeakage 4;
BA_ "GenSigTimeoutTime_ALL" SG_ 1171 BMS_Warning_CoolantLeakage 5000;
BA_ "InvalidValue" SG_ 1171 BMS_Warning_CoolantLeakage "null";
BA_ "GenSigSendType" SG_ 1171 BMS_MalfunctionSts 4;
BA_ "GenSigTimeoutTime_ALL" SG_ 1171 BMS_MalfunctionSts 5000;
BA_ "InvalidValue" SG_ 1171 BMS_MalfunctionSts "null";
BA_ "GenSigSendType" SG_ 1171 BMS_LowBattery 4;
BA_ "GenSigTimeoutTime_ALL" SG_ 1171 BMS_LowBattery 5000;
BA_ "InvalidValue" SG_ 1171 BMS_LowBattery "null";
BA_ "GenSigSendType" SG_ 1171 BMS_Warning_DeltaTemperature 4;
BA_ "GenSigTimeoutTime_ALL" SG_ 1171 BMS_Warning_DeltaTemperature 5000;
BA_ "InvalidValue" SG_ 1171 BMS_Warning_DeltaTemperature "null";
BA_ "GenSigSendType" SG_ 1171 BMS_Warning_BDUTemperatureSts 4;
BA_ "GenSigTimeoutTime_ALL" SG_ 1171 BMS_Warning_BDUTemperatureSts 5000;
BA_ "InvalidValue" SG_ 1171 BMS_Warning_BDUTemperatureSts "null";
BA_ "GenSigSendType" SG_ 1171 BMS_Warning_Contactor_Aging 4;
BA_ "GenSigTimeoutTime_ALL" SG_ 1171 BMS_Warning_Contactor_Aging 5000;
BA_ "InvalidValue" SG_ 1171 BMS_Warning_Contactor_Aging "null";
BA_ "GenSigSendType" SG_ 1171 BMS_Reserved_signal4 4;
BA_ "GenSigTimeoutTime_ALL" SG_ 1171 BMS_Reserved_signal4 5000;
BA_ "InvalidValue" SG_ 1171 BMS_Reserved_signal4 "null";
BA_ "GenSigSendType" SG_ 1171 BMS_Reserved_signal5 4;
BA_ "GenSigTimeoutTime_ALL" SG_ 1171 BMS_Reserved_signal5 5000;
BA_ "InvalidValue" SG_ 1171 BMS_Reserved_signal5 "null";
BA_ "GenSigSendType" SG_ 1178 CHSKM_EDS_R_WarnMsg 3;
BA_ "GenSigTimeoutTime_ALL" SG_ 1178 CHSKM_EDS_R_WarnMsg 5000;
BA_ "InvalidValue" SG_ 1178 CHSKM_EDS_R_WarnMsg "null";
BA_ "GenSigSendType" SG_ 1178 ALV_EDS_R_WarnMsg 3;
BA_ "GenSigTimeoutTime_ALL" SG_ 1178 ALV_EDS_R_WarnMsg 5000;
BA_ "InvalidValue" SG_ 1178 ALV_EDS_R_WarnMsg "Fh";
BA_ "GenSigSendType" SG_ 1178 EDS_R_Warning_Flag_1 4;
BA_ "GenSigTimeoutTime_ALL" SG_ 1178 EDS_R_Warning_Flag_1 5000;
BA_ "InvalidValue" SG_ 1178 EDS_R_Warning_Flag_1 "null";
BA_ "GenSigSendType" SG_ 1178 EDS_R_Warning_Flag_2 4;
BA_ "GenSigTimeoutTime_ALL" SG_ 1178 EDS_R_Warning_Flag_2 5000;
BA_ "InvalidValue" SG_ 1178 EDS_R_Warning_Flag_2 "null";
BA_ "GenSigSendType" SG_ 1178 EDS_R_Warning_Flag_3 4;
BA_ "GenSigTimeoutTime_ALL" SG_ 1178 EDS_R_Warning_Flag_3 5000;
BA_ "InvalidValue" SG_ 1178 EDS_R_Warning_Flag_3 "null";
BA_ "GenSigSendType" SG_ 1178 EDS_R_Warning_Flag_4 4;
BA_ "GenSigTimeoutTime_ALL" SG_ 1178 EDS_R_Warning_Flag_4 5000;
BA_ "InvalidValue" SG_ 1178 EDS_R_Warning_Flag_4 "null";
BA_ "GenSigSendType" SG_ 1178 EDS_R_Warning_Flag_5 4;
BA_ "GenSigTimeoutTime_ALL" SG_ 1178 EDS_R_Warning_Flag_5 5000;
BA_ "InvalidValue" SG_ 1178 EDS_R_Warning_Flag_5 "null";
BA_ "GenSigSendType" SG_ 1178 EDS_R_Warning_Flag_6 4;
BA_ "GenSigTimeoutTime_ALL" SG_ 1178 EDS_R_Warning_Flag_6 5000;
BA_ "InvalidValue" SG_ 1178 EDS_R_Warning_Flag_6 "null";
BA_ "GenSigSendType" SG_ 1178 EDS_R_Warning_Flag_7 4;
BA_ "GenSigTimeoutTime_ALL" SG_ 1178 EDS_R_Warning_Flag_7 5000;
BA_ "InvalidValue" SG_ 1178 EDS_R_Warning_Flag_7 "null";
BA_ "GenSigSendType" SG_ 1178 EDS_R_Warning_Flag_8 4;
BA_ "GenSigTimeoutTime_ALL" SG_ 1178 EDS_R_Warning_Flag_8 5000;
BA_ "InvalidValue" SG_ 1178 EDS_R_Warning_Flag_8 "null";
BA_ "GenSigSendType" SG_ 1178 EDS_R_Warning_Flag_9 4;
BA_ "GenSigTimeoutTime_ALL" SG_ 1178 EDS_R_Warning_Flag_9 5000;
BA_ "InvalidValue" SG_ 1178 EDS_R_Warning_Flag_9 "null";
BA_ "GenSigSendType" SG_ 1178 EDS_R_Warning_Flag_10 4;
BA_ "GenSigTimeoutTime_ALL" SG_ 1178 EDS_R_Warning_Flag_10 5000;
BA_ "InvalidValue" SG_ 1178 EDS_R_Warning_Flag_10 "null";
BA_ "GenSigSendType" SG_ 1178 EDS_R_Warning_Flag_11 4;
BA_ "GenSigTimeoutTime_ALL" SG_ 1178 EDS_R_Warning_Flag_11 5000;
BA_ "InvalidValue" SG_ 1178 EDS_R_Warning_Flag_11 "null";
BA_ "GenSigSendType" SG_ 1178 EDS_R_Warning_Flag_12 4;
BA_ "GenSigTimeoutTime_ALL" SG_ 1178 EDS_R_Warning_Flag_12 5000;
BA_ "InvalidValue" SG_ 1178 EDS_R_Warning_Flag_12 "null";
BA_ "GenSigSendType" SG_ 1178 EDS_R_Reserved_signal1 4;
BA_ "GenSigTimeoutTime_ALL" SG_ 1178 EDS_R_Reserved_signal1 5000;
BA_ "InvalidValue" SG_ 1178 EDS_R_Reserved_signal1 "null";
BA_ "GenSigSendType" SG_ 1178 EDS_R_Reserved_signal2 4;
BA_ "GenSigTimeoutTime_ALL" SG_ 1178 EDS_R_Reserved_signal2 5000;
BA_ "InvalidValue" SG_ 1178 EDS_R_Reserved_signal2 "null";
BA_ "GenSigSendType" SG_ 1178 EDS_R_Reserved_signal3 4;
BA_ "GenSigTimeoutTime_ALL" SG_ 1178 EDS_R_Reserved_signal3 5000;
BA_ "InvalidValue" SG_ 1178 EDS_R_Reserved_signal3 "null";
BA_ "GenSigSendType" SG_ 1178 EDS_R_Reserved_signal4 4;
BA_ "GenSigTimeoutTime_ALL" SG_ 1178 EDS_R_Reserved_signal4 5000;
BA_ "InvalidValue" SG_ 1178 EDS_R_Reserved_signal4 "null";
BA_ "GenSigSendType" SG_ 1178 EDS_R_Reserved_signal5 4;
BA_ "GenSigTimeoutTime_ALL" SG_ 1178 EDS_R_Reserved_signal5 5000;
BA_ "InvalidValue" SG_ 1178 EDS_R_Reserved_signal5 "null";
BA_ "GenSigSendType" SG_ 1179 CHSKM_EDS_F_WarnMsg 3;
BA_ "GenSigTimeoutTime_ALL" SG_ 1179 CHSKM_EDS_F_WarnMsg 5000;
BA_ "InvalidValue" SG_ 1179 CHSKM_EDS_F_WarnMsg "null";
BA_ "GenSigSendType" SG_ 1179 ALV_EDS_F_WarnMsg 3;
BA_ "GenSigTimeoutTime_ALL" SG_ 1179 ALV_EDS_F_WarnMsg 5000;
BA_ "InvalidValue" SG_ 1179 ALV_EDS_F_WarnMsg "Fh";
BA_ "GenSigSendType" SG_ 1179 EDS_F_Warning_Flag_1 4;
BA_ "GenSigTimeoutTime_ALL" SG_ 1179 EDS_F_Warning_Flag_1 5000;
BA_ "InvalidValue" SG_ 1179 EDS_F_Warning_Flag_1 "null";
BA_ "GenSigSendType" SG_ 1179 EDS_F_Warning_Flag_2 4;
BA_ "GenSigTimeoutTime_ALL" SG_ 1179 EDS_F_Warning_Flag_2 5000;
BA_ "InvalidValue" SG_ 1179 EDS_F_Warning_Flag_2 "null";
BA_ "GenSigSendType" SG_ 1179 EDS_F_Warning_Flag_3 4;
BA_ "GenSigTimeoutTime_ALL" SG_ 1179 EDS_F_Warning_Flag_3 5000;
BA_ "InvalidValue" SG_ 1179 EDS_F_Warning_Flag_3 "null";
BA_ "GenSigSendType" SG_ 1179 EDS_F_Warning_Flag_4 4;
BA_ "GenSigTimeoutTime_ALL" SG_ 1179 EDS_F_Warning_Flag_4 5000;
BA_ "InvalidValue" SG_ 1179 EDS_F_Warning_Flag_4 "null";
BA_ "GenSigSendType" SG_ 1179 EDS_F_Warning_Flag_5 4;
BA_ "GenSigTimeoutTime_ALL" SG_ 1179 EDS_F_Warning_Flag_5 5000;
BA_ "InvalidValue" SG_ 1179 EDS_F_Warning_Flag_5 "null";
BA_ "GenSigSendType" SG_ 1179 EDS_F_Warning_Flag_6 4;
BA_ "GenSigTimeoutTime_ALL" SG_ 1179 EDS_F_Warning_Flag_6 5000;
BA_ "InvalidValue" SG_ 1179 EDS_F_Warning_Flag_6 "null";
BA_ "GenSigSendType" SG_ 1179 EDS_F_Warning_Flag_7 4;
BA_ "GenSigTimeoutTime_ALL" SG_ 1179 EDS_F_Warning_Flag_7 5000;
BA_ "InvalidValue" SG_ 1179 EDS_F_Warning_Flag_7 "null";
BA_ "GenSigSendType" SG_ 1179 EDS_F_Warning_Flag_8 4;
BA_ "GenSigTimeoutTime_ALL" SG_ 1179 EDS_F_Warning_Flag_8 5000;
BA_ "InvalidValue" SG_ 1179 EDS_F_Warning_Flag_8 "null";
BA_ "GenSigSendType" SG_ 1179 EDS_F_Warning_Flag_9 4;
BA_ "GenSigTimeoutTime_ALL" SG_ 1179 EDS_F_Warning_Flag_9 5000;
BA_ "InvalidValue" SG_ 1179 EDS_F_Warning_Flag_9 "null";
BA_ "GenSigSendType" SG_ 1179 EDS_F_Warning_Flag_10 4;
BA_ "GenSigTimeoutTime_ALL" SG_ 1179 EDS_F_Warning_Flag_10 5000;
BA_ "InvalidValue" SG_ 1179 EDS_F_Warning_Flag_10 "null";
BA_ "GenSigSendType" SG_ 1179 EDS_F_Warning_Flag_11 4;
BA_ "GenSigTimeoutTime_ALL" SG_ 1179 EDS_F_Warning_Flag_11 5000;
BA_ "InvalidValue" SG_ 1179 EDS_F_Warning_Flag_11 "null";
BA_ "GenSigSendType" SG_ 1179 EDS_F_Warning_Flag_12 4;
BA_ "GenSigTimeoutTime_ALL" SG_ 1179 EDS_F_Warning_Flag_12 5000;
BA_ "InvalidValue" SG_ 1179 EDS_F_Warning_Flag_12 "null";
BA_ "GenSigSendType" SG_ 1179 EDS_F_Reserved_signal1 4;
BA_ "GenSigTimeoutTime_ALL" SG_ 1179 EDS_F_Reserved_signal1 5000;
BA_ "InvalidValue" SG_ 1179 EDS_F_Reserved_signal1 "null";
BA_ "GenSigSendType" SG_ 1179 EDS_F_Reserved_signal2 4;
BA_ "GenSigTimeoutTime_ALL" SG_ 1179 EDS_F_Reserved_signal2 5000;
BA_ "InvalidValue" SG_ 1179 EDS_F_Reserved_signal2 "null";
BA_ "GenSigSendType" SG_ 1179 EDS_F_Reserved_signal3 4;
BA_ "GenSigTimeoutTime_ALL" SG_ 1179 EDS_F_Reserved_signal3 5000;
BA_ "InvalidValue" SG_ 1179 EDS_F_Reserved_signal3 "null";
BA_ "GenSigSendType" SG_ 1179 EDS_F_Reserved_signal4 4;
BA_ "GenSigTimeoutTime_ALL" SG_ 1179 EDS_F_Reserved_signal4 5000;
BA_ "InvalidValue" SG_ 1179 EDS_F_Reserved_signal4 "null";
BA_ "GenSigSendType" SG_ 1179 EDS_F_Reserved_signal5 4;
BA_ "GenSigTimeoutTime_ALL" SG_ 1179 EDS_F_Reserved_signal5 5000;
BA_ "InvalidValue" SG_ 1179 EDS_F_Reserved_signal5 "null";
BA_ "GenSigSendType" SG_ 1191 CHSKM_RCU_WarnMsg 3;
BA_ "GenSigTimeoutTime_ALL" SG_ 1191 CHSKM_RCU_WarnMsg 5000;
BA_ "GenSigSendType" SG_ 1191 ALV_RCU_WarnMsg 3;
BA_ "GenSigTimeoutTime_ALL" SG_ 1191 ALV_RCU_WarnMsg 5000;
BA_ "InvalidValue" SG_ 1191 ALV_RCU_WarnMsg "Fh";
BA_ "GenSigSendType" SG_ 1191 RCU_DAA_NoOpDoorOpen 4;
BA_ "GenSigTimeoutTime_ALL" SG_ 1191 RCU_DAA_NoOpDoorOpen 5000;
BA_ "GenSigSendType" SG_ 1191 RCU_EHandBrk_fault 4;
BA_ "GenSigTimeoutTime_ALL" SG_ 1191 RCU_EHandBrk_fault 5000;
BA_ "GenSigSendType" SG_ 1191 RCU_EOL_NotDone 4;
BA_ "GenSigTimeoutTime_ALL" SG_ 1191 RCU_EOL_NotDone 5000;
BA_ "GenSigSendType" SG_ 1191 RCU_ECD_RWU_active 4;
BA_ "GenSigTimeoutTime_ALL" SG_ 1191 RCU_ECD_RWU_active 5000;
BA_ "GenSigSendType" SG_ 1191 RCU_ParkOnSteepInclination 4;
BA_ "GenSigTimeoutTime_ALL" SG_ 1191 RCU_ParkOnSteepInclination 5000;
BA_ "GenSigSendType" SG_ 1191 RCU_BrkForceNotEnough 4;
BA_ "GenSigTimeoutTime_ALL" SG_ 1191 RCU_BrkForceNotEnough 5000;
BA_ "GenSigSendType" SG_ 1191 RCU_ReleaseEPB_Wo_PressBrk 4;
BA_ "GenSigTimeoutTime_ALL" SG_ 1191 RCU_ReleaseEPB_Wo_PressBrk 5000;
BA_ "GenSigSendType" SG_ 1191 RCU_ParkBrkApplied 4;
BA_ "GenSigTimeoutTime_ALL" SG_ 1191 RCU_ParkBrkApplied 5000;
BA_ "GenSigSendType" SG_ 1191 RCU_Swch_Mafnc 4;
BA_ "GenSigTimeoutTime_ALL" SG_ 1191 RCU_Swch_Mafnc 5000;
BA_ "GenSigSendType" SG_ 1191 RCU_DAA_NoOpBeltUnbuckled 4;
BA_ "GenSigTimeoutTime_ALL" SG_ 1191 RCU_DAA_NoOpBeltUnbuckled 5000;
BA_ "GenSigSendType" SG_ 1191 RCU_RollerBenchMode 4;
BA_ "GenSigTimeoutTime_ALL" SG_ 1191 RCU_RollerBenchMode 5000;
BA_ "GenSigSendType" SG_ 1191 RCU_EPB_ParkLampState 4;
BA_ "GenSigTimeoutTime_ALL" SG_ 1191 RCU_EPB_ParkLampState 5000;
BA_ "GenSigSendType" SG_ 1191 RCU_EPB_WarnLampState 4;
BA_ "GenSigTimeoutTime_ALL" SG_ 1191 RCU_EPB_WarnLampState 5000;
BA_ "GenSigSendType" SG_ 1191 RCU_WflagRes36 4;
BA_ "GenSigTimeoutTime_ALL" SG_ 1191 RCU_WflagRes36 5000;
BA_ "InvalidValue" SG_ 1191 RCU_WflagRes36 "null";
BA_ "GenSigSendType" SG_ 1191 RCU_WflagRes37 4;
BA_ "GenSigTimeoutTime_ALL" SG_ 1191 RCU_WflagRes37 5000;
BA_ "InvalidValue" SG_ 1191 RCU_WflagRes37 "null";
BA_ "GenSigSendType" SG_ 1191 RCU_WflagRes38 4;
BA_ "GenSigTimeoutTime_ALL" SG_ 1191 RCU_WflagRes38 5000;
BA_ "InvalidValue" SG_ 1191 RCU_WflagRes38 "null";
BA_ "GenSigSendType" SG_ 1191 RCU_WflagRes39 4;
BA_ "GenSigTimeoutTime_ALL" SG_ 1191 RCU_WflagRes39 5000;
BA_ "InvalidValue" SG_ 1191 RCU_WflagRes39 "null";
BA_ "GenSigSendType" SG_ 1191 RCU_WflagRes40 4;
BA_ "GenSigTimeoutTime_ALL" SG_ 1191 RCU_WflagRes40 5000;
BA_ "InvalidValue" SG_ 1191 RCU_WflagRes40 "null";
BA_ "GenSigSendType" SG_ 1191 RCU_WflagRes41 4;
BA_ "GenSigTimeoutTime_ALL" SG_ 1191 RCU_WflagRes41 5000;
BA_ "InvalidValue" SG_ 1191 RCU_WflagRes41 "null";
BA_ "GenSigSendType" SG_ 1191 RCU_WflagRes42 4;
BA_ "GenSigTimeoutTime_ALL" SG_ 1191 RCU_WflagRes42 5000;
BA_ "InvalidValue" SG_ 1191 RCU_WflagRes42 "null";
BA_ "GenSigSendType" SG_ 1191 RCU_WflagRes43 4;
BA_ "GenSigTimeoutTime_ALL" SG_ 1191 RCU_WflagRes43 5000;
BA_ "GenSigSendType" SG_ 1191 RCU_WflagRes44 4;
BA_ "GenSigTimeoutTime_ALL" SG_ 1191 RCU_WflagRes44 5000;
BA_ "GenSigSendType" SG_ 1191 RCU_WflagRes45 4;
BA_ "GenSigTimeoutTime_ALL" SG_ 1191 RCU_WflagRes45 5000;
BA_ "GenSigSendType" SG_ 1191 RCU_WflagRes46 4;
BA_ "GenSigTimeoutTime_ALL" SG_ 1191 RCU_WflagRes46 5000;
BA_ "GenSigSendType" SG_ 1191 RCU_WflagRes47 4;
BA_ "GenSigTimeoutTime_ALL" SG_ 1191 RCU_WflagRes47 5000;
BA_ "GenSigSendType" SG_ 1191 RCU_Reserved_signal1 4;
BA_ "GenSigTimeoutTime_ALL" SG_ 1191 RCU_Reserved_signal1 5000;
BA_ "InvalidValue" SG_ 1191 RCU_Reserved_signal1 "null";
BA_ "GenSigSendType" SG_ 1192 CHSKM_EPS_WarnMsg 3;
BA_ "GenSigTimeoutTime_ALL" SG_ 1192 CHSKM_EPS_WarnMsg 5000;
BA_ "InvalidValue" SG_ 1192 CHSKM_EPS_WarnMsg "null";
BA_ "GenSigSendType" SG_ 1192 ALV_EPS_WarnMsg 3;
BA_ "GenSigTimeoutTime_ALL" SG_ 1192 ALV_EPS_WarnMsg 5000;
BA_ "InvalidValue" SG_ 1192 ALV_EPS_WarnMsg "Fh";
BA_ "GenSigSendType" SG_ 1192 EPS_Malfunction 4;
BA_ "GenSigTimeoutTime_ALL" SG_ 1192 EPS_Malfunction 5000;
BA_ "InvalidValue" SG_ 1192 EPS_Malfunction "null";
BA_ "GenSigSendType" SG_ 1192 EPS_Reduced 4;
BA_ "GenSigTimeoutTime_ALL" SG_ 1192 EPS_Reduced 5000;
BA_ "InvalidValue" SG_ 1192 EPS_Reduced "null";
BA_ "GenSigSendType" SG_ 1192 EPS_Overheat 4;
BA_ "GenSigTimeoutTime_ALL" SG_ 1192 EPS_Overheat 5000;
BA_ "InvalidValue" SG_ 1192 EPS_Overheat "null";
BA_ "GenSigSendType" SG_ 1192 EPS_NotReady 4;
BA_ "GenSigTimeoutTime_ALL" SG_ 1192 EPS_NotReady 5000;
BA_ "InvalidValue" SG_ 1192 EPS_NotReady "null";
BA_ "GenSigSendType" SG_ 1192 EPS_Warning_Flag_5 4;
BA_ "GenSigTimeoutTime_ALL" SG_ 1192 EPS_Warning_Flag_5 5000;
BA_ "InvalidValue" SG_ 1192 EPS_Warning_Flag_5 "null";
BA_ "GenSigSendType" SG_ 1192 EPS_Warning_Flag_6 4;
BA_ "GenSigTimeoutTime_ALL" SG_ 1192 EPS_Warning_Flag_6 5000;
BA_ "InvalidValue" SG_ 1192 EPS_Warning_Flag_6 "null";
BA_ "GenSigSendType" SG_ 1192 EPS_Warning_Flag_7 4;
BA_ "GenSigTimeoutTime_ALL" SG_ 1192 EPS_Warning_Flag_7 5000;
BA_ "InvalidValue" SG_ 1192 EPS_Warning_Flag_7 "null";
BA_ "GenSigSendType" SG_ 1192 EPS_Warning_Flag_8 4;
BA_ "GenSigTimeoutTime_ALL" SG_ 1192 EPS_Warning_Flag_8 5000;
BA_ "InvalidValue" SG_ 1192 EPS_Warning_Flag_8 "null";
BA_ "GenSigSendType" SG_ 1192 EPS_Warning_Flag_9 4;
BA_ "GenSigTimeoutTime_ALL" SG_ 1192 EPS_Warning_Flag_9 5000;
BA_ "InvalidValue" SG_ 1192 EPS_Warning_Flag_9 "null";
BA_ "GenSigSendType" SG_ 1192 EPS_Warning_Flag_10 4;
BA_ "GenSigTimeoutTime_ALL" SG_ 1192 EPS_Warning_Flag_10 5000;
BA_ "InvalidValue" SG_ 1192 EPS_Warning_Flag_10 "null";
BA_ "GenSigSendType" SG_ 1192 EPS_Warning_Flag_11 4;
BA_ "GenSigTimeoutTime_ALL" SG_ 1192 EPS_Warning_Flag_11 5000;
BA_ "InvalidValue" SG_ 1192 EPS_Warning_Flag_11 "null";
BA_ "GenSigSendType" SG_ 1192 EPS_Warning_Flag_12 4;
BA_ "GenSigTimeoutTime_ALL" SG_ 1192 EPS_Warning_Flag_12 5000;
BA_ "InvalidValue" SG_ 1192 EPS_Warning_Flag_12 "null";
BA_ "GenSigSendType" SG_ 1192 EPS_Reserved_signal1 4;
BA_ "GenSigTimeoutTime_ALL" SG_ 1192 EPS_Reserved_signal1 5000;
BA_ "InvalidValue" SG_ 1192 EPS_Reserved_signal1 "null";
BA_ "GenSigSendType" SG_ 1192 EPS_Reserved_signal2 4;
BA_ "GenSigTimeoutTime_ALL" SG_ 1192 EPS_Reserved_signal2 5000;
BA_ "InvalidValue" SG_ 1192 EPS_Reserved_signal2 "null";
BA_ "GenSigSendType" SG_ 1192 EPS_Reserved_signal3 4;
BA_ "GenSigTimeoutTime_ALL" SG_ 1192 EPS_Reserved_signal3 5000;
BA_ "InvalidValue" SG_ 1192 EPS_Reserved_signal3 "null";
BA_ "GenSigSendType" SG_ 1192 EPS_Reserved_signal4 4;
BA_ "GenSigTimeoutTime_ALL" SG_ 1192 EPS_Reserved_signal4 5000;
BA_ "InvalidValue" SG_ 1192 EPS_Reserved_signal4 "null";
BA_ "GenSigSendType" SG_ 1192 EPS_Reserved_signal5 4;
BA_ "GenSigTimeoutTime_ALL" SG_ 1192 EPS_Reserved_signal5 5000;
BA_ "InvalidValue" SG_ 1192 EPS_Reserved_signal5 "null";
BA_ "GenSigSendType" SG_ 1193 CHSKM_IDB_WarnMsg 3;
BA_ "GenSigTimeoutTime_ALL" SG_ 1193 CHSKM_IDB_WarnMsg 5000;
BA_ "InvalidValue" SG_ 1193 CHSKM_IDB_WarnMsg "null";
BA_ "GenSigSendType" SG_ 1193 ALV_IDB_WarnMsg 3;
BA_ "GenSigTimeoutTime_ALL" SG_ 1193 ALV_IDB_WarnMsg 5000;
BA_ "InvalidValue" SG_ 1193 ALV_IDB_WarnMsg "Fh";
BA_ "GenSigSendType" SG_ 1193 IDB_ESC_fault 4;
BA_ "GenSigTimeoutTime_ALL" SG_ 1193 IDB_ESC_fault 5000;
BA_ "InvalidValue" SG_ 1193 IDB_ESC_fault "null";
BA_ "GenSigSendType" SG_ 1193 IDB_ABS_fault 4;
BA_ "GenSigTimeoutTime_ALL" SG_ 1193 IDB_ABS_fault 5000;
BA_ "InvalidValue" SG_ 1193 IDB_ABS_fault "null";
BA_ "GenSigSendType" SG_ 1193 IDB_BrkLowFluid 4;
BA_ "GenSigTimeoutTime_ALL" SG_ 1193 IDB_BrkLowFluid 5000;
BA_ "InvalidValue" SG_ 1193 IDB_BrkLowFluid "null";
BA_ "GenSigSendType" SG_ 1193 IDB_BrkSysFault 4;
BA_ "GenSigTimeoutTime_ALL" SG_ 1193 IDB_BrkSysFault 5000;
BA_ "InvalidValue" SG_ 1193 IDB_BrkSysFault "null";
BA_ "GenSigSendType" SG_ 1193 IDB_fault 4;
BA_ "GenSigTimeoutTime_ALL" SG_ 1193 IDB_fault 5000;
BA_ "InvalidValue" SG_ 1193 IDB_fault "null";
BA_ "GenSigSendType" SG_ 1193 IDB_HydraulicBrkAssist_Fault 4;
BA_ "GenSigTimeoutTime_ALL" SG_ 1193 IDB_HydraulicBrkAssist_Fault 5000;
BA_ "InvalidValue" SG_ 1193 IDB_HydraulicBrkAssist_Fault "null";
BA_ "GenSigSendType" SG_ 1193 IDB_HAS_Fault 4;
BA_ "GenSigTimeoutTime_ALL" SG_ 1193 IDB_HAS_Fault 5000;
BA_ "InvalidValue" SG_ 1193 IDB_HAS_Fault "null";
BA_ "GenSigSendType" SG_ 1193 IDB_TSM_Fault 4;
BA_ "GenSigTimeoutTime_ALL" SG_ 1193 IDB_TSM_Fault 5000;
BA_ "InvalidValue" SG_ 1193 IDB_TSM_Fault "null";
BA_ "GenSigSendType" SG_ 1193 IDB_Reserved_signal2 4;
BA_ "GenSigTimeoutTime_ALL" SG_ 1193 IDB_Reserved_signal2 5000;
BA_ "InvalidValue" SG_ 1193 IDB_Reserved_signal2 "null";
BA_ "GenSigSendType" SG_ 1193 IDB_Reserved_signal3 4;
BA_ "GenSigTimeoutTime_ALL" SG_ 1193 IDB_Reserved_signal3 5000;
BA_ "InvalidValue" SG_ 1193 IDB_Reserved_signal3 "null";
BA_ "GenSigSendType" SG_ 1193 IDB_Reserved_signal4 4;
BA_ "GenSigTimeoutTime_ALL" SG_ 1193 IDB_Reserved_signal4 5000;
BA_ "InvalidValue" SG_ 1193 IDB_Reserved_signal4 "null";
BA_ "GenSigSendType" SG_ 1193 IDB_Reserved_signal5 4;
BA_ "GenSigTimeoutTime_ALL" SG_ 1193 IDB_Reserved_signal5 5000;
BA_ "InvalidValue" SG_ 1193 IDB_Reserved_signal5 "null";
BA_ "GenSigSendType" SG_ 1196 CHSKM_VCU_WarnMsg 3;
BA_ "GenSigTimeoutTime_ALL" SG_ 1196 CHSKM_VCU_WarnMsg 5000;
BA_ "GenSigSendType" SG_ 1196 ALV_VCU_WarnMsg 3;
BA_ "GenSigTimeoutTime_ALL" SG_ 1196 ALV_VCU_WarnMsg 5000;
BA_ "InvalidValue" SG_ 1196 ALV_VCU_WarnMsg "Fh";
BA_ "GenSigSendType" SG_ 1196 VCU_GearPOnlyAtStationaryAlert 4;
BA_ "GenSigTimeoutTime_ALL" SG_ 1196 VCU_GearPOnlyAtStationaryAlert 5000;
BA_ "GenSigSendType" SG_ 1196 VCU_GearP_NotPossibleAlert 4;
BA_ "GenSigTimeoutTime_ALL" SG_ 1196 VCU_GearP_NotPossibleAlert 5000;
BA_ "GenSigSendType" SG_ 1196 VCU_PressBrakeToEngageGear 4;
BA_ "GenSigTimeoutTime_ALL" SG_ 1196 VCU_PressBrakeToEngageGear 5000;
BA_ "GenSigSendType" SG_ 1196 VCU_CantChangeGear 4;
BA_ "GenSigTimeoutTime_ALL" SG_ 1196 VCU_CantChangeGear 5000;
BA_ "GenSigSendType" SG_ 1196 VCU_GearMalfunction 4;
BA_ "GenSigTimeoutTime_ALL" SG_ 1196 VCU_GearMalfunction 5000;
BA_ "GenSigSendType" SG_ 1196 VCU_RangeAlert 4;
BA_ "GenSigTimeoutTime_ALL" SG_ 1196 VCU_RangeAlert 5000;
BA_ "GenSigSendType" SG_ 1196 VCU_HVSystemReduced 4;
BA_ "GenSigTimeoutTime_ALL" SG_ 1196 VCU_HVSystemReduced 5000;
BA_ "GenSigSendType" SG_ 1196 VCU_FrontEDSReduced 4;
BA_ "GenSigTimeoutTime_ALL" SG_ 1196 VCU_FrontEDSReduced 5000;
BA_ "GenSigSendType" SG_ 1196 VCU_FrontEDS_Malfunc 4;
BA_ "GenSigTimeoutTime_ALL" SG_ 1196 VCU_FrontEDS_Malfunc 5000;
BA_ "GenSigSendType" SG_ 1196 VCU_RearEDSReduced 4;
BA_ "GenSigTimeoutTime_ALL" SG_ 1196 VCU_RearEDSReduced 5000;
BA_ "GenSigSendType" SG_ 1196 VCU_RearEDS_Malfunc 4;
BA_ "GenSigTimeoutTime_ALL" SG_ 1196 VCU_RearEDS_Malfunc 5000;
BA_ "GenSigSendType" SG_ 1196 VCU_CoolingSystem_Malfunc 4;
BA_ "GenSigTimeoutTime_ALL" SG_ 1196 VCU_CoolingSystem_Malfunc 5000;
BA_ "GenSigSendType" SG_ 1196 VCU_NeutralRequest 4;
BA_ "GenSigTimeoutTime_ALL" SG_ 1196 VCU_NeutralRequest 5000;
BA_ "GenSigSendType" SG_ 1196 VCU_SoftShutdown 4;
BA_ "GenSigTimeoutTime_ALL" SG_ 1196 VCU_SoftShutdown 5000;
BA_ "GenSigSendType" SG_ 1196 VCU_EmergencyShutdown 4;
BA_ "GenSigTimeoutTime_ALL" SG_ 1196 VCU_EmergencyShutdown 5000;
BA_ "GenSigSendType" SG_ 1196 VCU_ChgPortDoorSys_Malfunc 4;
BA_ "GenSigTimeoutTime_ALL" SG_ 1196 VCU_ChgPortDoorSys_Malfunc 5000;
BA_ "GenSigSendType" SG_ 1196 VCU_Gearchange_NotPossible 4;
BA_ "GenSigTimeoutTime_ALL" SG_ 1196 VCU_Gearchange_NotPossible 5000;
BA_ "GenSigSendType" SG_ 1196 VCU_12v_Warning 4;
BA_ "GenSigTimeoutTime_ALL" SG_ 1196 VCU_12v_Warning 5000;
BA_ "GenSigSendType" SG_ 1196 VCU_WflagRes19 4;
BA_ "GenSigTimeoutTime_ALL" SG_ 1196 VCU_WflagRes19 5000;
BA_ "GenSigSendType" SG_ 1196 VCU_WflagRes20 4;
BA_ "GenSigTimeoutTime_ALL" SG_ 1196 VCU_WflagRes20 5000;
BA_ "GenSigSendType" SG_ 1196 VCU_WflagRes21 4;
BA_ "GenSigTimeoutTime_ALL" SG_ 1196 VCU_WflagRes21 5000;
BA_ "GenSigSendType" SG_ 1196 VCU_WflagRes22 4;
BA_ "GenSigTimeoutTime_ALL" SG_ 1196 VCU_WflagRes22 5000;
BA_ "GenSigSendType" SG_ 1196 VCU_WflagRes23 4;
BA_ "GenSigTimeoutTime_ALL" SG_ 1196 VCU_WflagRes23 5000;
BA_ "GenSigSendType" SG_ 1196 VCU_WflagRes24 4;
BA_ "GenSigTimeoutTime_ALL" SG_ 1196 VCU_WflagRes24 5000;
BA_ "GenSigSendType" SG_ 1196 VCU_WflagRes25 4;
BA_ "GenSigTimeoutTime_ALL" SG_ 1196 VCU_WflagRes25 5000;
BA_ "GenSigSendType" SG_ 1196 VCU_WflagRes26 4;
BA_ "GenSigTimeoutTime_ALL" SG_ 1196 VCU_WflagRes26 5000;
BA_ "GenSigSendType" SG_ 1196 VCU_WflagRes27 4;
BA_ "GenSigTimeoutTime_ALL" SG_ 1196 VCU_WflagRes27 5000;
BA_ "GenSigSendType" SG_ 1196 VCU_SuperFastCharge_longer 4;
BA_ "GenSigTimeoutTime_ALL" SG_ 1196 VCU_SuperFastCharge_longer 5000;
BA_ "GenSigSendType" SG_ 1196 VCU_InvalidLimitSpeed 4;
BA_ "GenSigTimeoutTime_ALL" SG_ 1196 VCU_InvalidLimitSpeed 5000;
BA_ "GenSigSendType" SG_ 1196 VCU_InvalidCruiseSpeed 4;
BA_ "GenSigTimeoutTime_ALL" SG_ 1196 VCU_InvalidCruiseSpeed 5000;
BA_ "GenSigSendType" SG_ 1196 VCU_Reserved_signal2 4;
BA_ "GenSigTimeoutTime_ALL" SG_ 1196 VCU_Reserved_signal2 5000;
BA_ "GenSigSendType" SG_ 1196 VCU_Reserved_signal3 4;
BA_ "GenSigTimeoutTime_ALL" SG_ 1196 VCU_Reserved_signal3 5000;
BA_ "GenSigSendType" SG_ 1198 CHSKM_EASC_WarnMsg 3;
BA_ "GenSigTimeoutTime_ALL" SG_ 1198 CHSKM_EASC_WarnMsg 5000;
BA_ "GenSigSendType" SG_ 1198 ALV_EASC_WarnMsg 3;
BA_ "GenSigTimeoutTime_ALL" SG_ 1198 ALV_EASC_WarnMsg 5000;
BA_ "InvalidValue" SG_ 1198 ALV_EASC_WarnMsg "Fh";
BA_ "GenSigSendType" SG_ 1198 EASC_Warning_Flag_1 4;
BA_ "GenSigTimeoutTime_ALL" SG_ 1198 EASC_Warning_Flag_1 5000;
BA_ "GenSigSendType" SG_ 1198 EASC_Warning_Flag_2 4;
BA_ "GenSigTimeoutTime_ALL" SG_ 1198 EASC_Warning_Flag_2 5000;
BA_ "GenSigSendType" SG_ 1198 EASC_Warning_Flag_3 4;
BA_ "GenSigTimeoutTime_ALL" SG_ 1198 EASC_Warning_Flag_3 5000;
BA_ "GenSigSendType" SG_ 1198 EASC_Warning_Flag_4 4;
BA_ "GenSigTimeoutTime_ALL" SG_ 1198 EASC_Warning_Flag_4 5000;
BA_ "GenSigSendType" SG_ 1198 EASC_Warning_Flag_5 4;
BA_ "GenSigTimeoutTime_ALL" SG_ 1198 EASC_Warning_Flag_5 5000;
BA_ "GenSigSendType" SG_ 1198 EASC_Warning_Flag_6 4;
BA_ "GenSigTimeoutTime_ALL" SG_ 1198 EASC_Warning_Flag_6 5000;
BA_ "GenSigSendType" SG_ 1198 EASC_Warning_Flag_7 4;
BA_ "GenSigTimeoutTime_ALL" SG_ 1198 EASC_Warning_Flag_7 5000;
BA_ "GenSigSendType" SG_ 1198 EASC_Warning_Flag_8 4;
BA_ "GenSigTimeoutTime_ALL" SG_ 1198 EASC_Warning_Flag_8 5000;
BA_ "GenSigSendType" SG_ 1198 EASC_Warning_Flag_9 4;
BA_ "GenSigTimeoutTime_ALL" SG_ 1198 EASC_Warning_Flag_9 5000;
BA_ "GenSigSendType" SG_ 1198 EASC_Warning_Flag_10 4;
BA_ "GenSigTimeoutTime_ALL" SG_ 1198 EASC_Warning_Flag_10 5000;
BA_ "GenSigSendType" SG_ 1198 EASC_Warning_Flag_11 4;
BA_ "GenSigTimeoutTime_ALL" SG_ 1198 EASC_Warning_Flag_11 5000;
BA_ "GenSigSendType" SG_ 1198 EASC_Warning_Flag_12 4;
BA_ "GenSigTimeoutTime_ALL" SG_ 1198 EASC_Warning_Flag_12 5000;
BA_ "GenSigSendType" SG_ 1198 EASC_Reserved_signal1 4;
BA_ "GenSigTimeoutTime_ALL" SG_ 1198 EASC_Reserved_signal1 5000;
BA_ "GenSigSendType" SG_ 1198 EASC_Reserved_signal2 4;
BA_ "GenSigTimeoutTime_ALL" SG_ 1198 EASC_Reserved_signal2 5000;
BA_ "GenSigSendType" SG_ 1198 EASC_Reserved_signal3 4;
BA_ "GenSigTimeoutTime_ALL" SG_ 1198 EASC_Reserved_signal3 5000;
BA_ "GenSigSendType" SG_ 1198 EASC_Reserved_signal4 4;
BA_ "GenSigTimeoutTime_ALL" SG_ 1198 EASC_Reserved_signal4 5000;
BA_ "GenSigSendType" SG_ 1198 EASC_Reserved_signal5 4;
BA_ "GenSigTimeoutTime_ALL" SG_ 1198 EASC_Reserved_signal5 5000;
BA_ "GenSigSendType" SG_ 1199 CHSKM_CPD_WarnMsg 3;
BA_ "GenSigTimeoutTime_ALL" SG_ 1199 CHSKM_CPD_WarnMsg 5000;
BA_ "GenSigSendType" SG_ 1199 ALV_CPD_WarnMsg 3;
BA_ "GenSigTimeoutTime_ALL" SG_ 1199 ALV_CPD_WarnMsg 5000;
BA_ "InvalidValue" SG_ 1199 ALV_CPD_WarnMsg "Fh";
BA_ "GenSigSendType" SG_ 1199 CPD_Malfunction 4;
BA_ "GenSigTimeoutTime_ALL" SG_ 1199 CPD_Malfunction 5000;
BA_ "GenSigSendType" SG_ 1199 CPD_SensorFault 4;
BA_ "GenSigTimeoutTime_ALL" SG_ 1199 CPD_SensorFault 5000;
BA_ "InvalidValue" SG_ 1199 CPD_SensorFault "3h";
BA_ "GenSigSendType" SG_ 1199 CPD_Warning_Flag_4 4;
BA_ "GenSigTimeoutTime_ALL" SG_ 1199 CPD_Warning_Flag_4 5000;
BA_ "GenSigSendType" SG_ 1199 CPD_Warning_Flag_5 4;
BA_ "GenSigTimeoutTime_ALL" SG_ 1199 CPD_Warning_Flag_5 5000;
BA_ "GenSigSendType" SG_ 1199 CPD_Warning_Flag_6 4;
BA_ "GenSigTimeoutTime_ALL" SG_ 1199 CPD_Warning_Flag_6 5000;
BA_ "GenSigSendType" SG_ 1199 CPD_Warning_Flag_7 4;
BA_ "GenSigTimeoutTime_ALL" SG_ 1199 CPD_Warning_Flag_7 5000;
BA_ "GenSigSendType" SG_ 1199 CPD_Warning_Flag_8 4;
BA_ "GenSigTimeoutTime_ALL" SG_ 1199 CPD_Warning_Flag_8 5000;
BA_ "GenSigSendType" SG_ 1199 CPD_Warning_Flag_9 4;
BA_ "GenSigTimeoutTime_ALL" SG_ 1199 CPD_Warning_Flag_9 5000;
BA_ "GenSigSendType" SG_ 1199 CPD_Warning_Flag_10 4;
BA_ "GenSigTimeoutTime_ALL" SG_ 1199 CPD_Warning_Flag_10 5000;
BA_ "GenSigSendType" SG_ 1199 CPD_Warning_Flag_11 4;
BA_ "GenSigTimeoutTime_ALL" SG_ 1199 CPD_Warning_Flag_11 5000;
BA_ "GenSigSendType" SG_ 1199 CPD_Warning_Flag_12 4;
BA_ "GenSigTimeoutTime_ALL" SG_ 1199 CPD_Warning_Flag_12 5000;
BA_ "GenSigSendType" SG_ 1199 CPD_Reserved_signal1 4;
BA_ "GenSigTimeoutTime_ALL" SG_ 1199 CPD_Reserved_signal1 5000;
BA_ "GenSigSendType" SG_ 1199 CPD_Reserved_signal2 4;
BA_ "GenSigTimeoutTime_ALL" SG_ 1199 CPD_Reserved_signal2 5000;
BA_ "GenSigSendType" SG_ 1199 CPD_Reserved_signal3 4;
BA_ "GenSigTimeoutTime_ALL" SG_ 1199 CPD_Reserved_signal3 5000;
BA_ "GenSigSendType" SG_ 1199 CPD_Reserved_signal4 4;
BA_ "GenSigTimeoutTime_ALL" SG_ 1199 CPD_Reserved_signal4 5000;
BA_ "GenSigSendType" SG_ 1199 CPD_Reserved_signal5 4;
BA_ "GenSigTimeoutTime_ALL" SG_ 1199 CPD_Reserved_signal5 5000;
BA_ "GenSigTimeoutTime_ALL" SG_ 1209 Checksum_0x4B9 5000;
BA_ "InvalidValue" SG_ 1209 Checksum_0x4B9 "0";
BA_ "GenSigTimeoutTime_ALL" SG_ 1209 Rolling_Counter_0x4B9 5000;
BA_ "InvalidValue" SG_ 1209 Rolling_Counter_0x4B9 "Fh";
BA_ "GenSigTimeoutTime_ALL" SG_ 1209 BSD_Warning_Flag_7 5000;
BA_ "InvalidValue" SG_ 1209 BSD_Warning_Flag_7 "0";
BA_ "GenSigTimeoutTime_ALL" SG_ 1209 BSD_Warning_Flag_8 5000;
BA_ "InvalidValue" SG_ 1209 BSD_Warning_Flag_8 "0";
BA_ "GenSigTimeoutTime_ALL" SG_ 1209 BSD_Warning_Flag_9 5000;
BA_ "InvalidValue" SG_ 1209 BSD_Warning_Flag_9 "0";
BA_ "GenSigTimeoutTime_ALL" SG_ 1209 BSD_Warning_Flag_10 5000;
BA_ "InvalidValue" SG_ 1209 BSD_Warning_Flag_10 "0";
BA_ "GenSigTimeoutTime_ALL" SG_ 1209 BSD_Warning_Flag_14 5000;
BA_ "InvalidValue" SG_ 1209 BSD_Warning_Flag_14 "0";
BA_ "GenSigTimeoutTime_ALL" SG_ 1209 BSD_Warning_Flag_21 5000;
BA_ "InvalidValue" SG_ 1209 BSD_Warning_Flag_21 "0";
BA_ "GenSigTimeoutTime_ALL" SG_ 1209 BSD_Warning_Flag_22 5000;
BA_ "InvalidValue" SG_ 1209 BSD_Warning_Flag_22 "0";
BA_ "GenSigTimeoutTime_ALL" SG_ 1209 BSD_Warning_Flag_23 5000;
BA_ "InvalidValue" SG_ 1209 BSD_Warning_Flag_23 "0";
BA_ "GenSigTimeoutTime_ALL" SG_ 1209 BSD_Warning_Flag_24 5000;
BA_ "InvalidValue" SG_ 1209 BSD_Warning_Flag_24 "0";
BA_ "GenSigSendType" SG_ 1211 CHSKM_TRM_WarnMsg 4;
BA_ "GenSigTimeoutTime_ALL" SG_ 1211 CHSKM_TRM_WarnMsg 500;
BA_ "InvalidValue" SG_ 1211 CHSKM_TRM_WarnMsg "null";
BA_ "GenSigSendType" SG_ 1211 ALV_TRM_WarnMsg 4;
BA_ "GenSigTimeoutTime_ALL" SG_ 1211 ALV_TRM_WarnMsg 500;
BA_ "InvalidValue" SG_ 1211 ALV_TRM_WarnMsg "Fh";
BA_ "GenSigSendType" SG_ 1211 TRM_LightMalfnc 4;
BA_ "GenSigTimeoutTime_ALL" SG_ 1211 TRM_LightMalfnc 500;
BA_ "InvalidValue" SG_ 1211 TRM_LightMalfnc "null";
BA_ "GenSigSendType" SG_ 1211 TRM_TurnLeftMafnc 4;
BA_ "GenSigTimeoutTime_ALL" SG_ 1211 TRM_TurnLeftMafnc 500;
BA_ "InvalidValue" SG_ 1211 TRM_TurnLeftMafnc "null";
BA_ "GenSigSendType" SG_ 1211 TRM_TurnRightMafnc 4;
BA_ "GenSigTimeoutTime_ALL" SG_ 1211 TRM_TurnRightMafnc 500;
BA_ "InvalidValue" SG_ 1211 TRM_TurnRightMafnc "null";
BA_ "GenSigSendType" SG_ 1211 TRM_TrailerMalfnc 4;
BA_ "GenSigTimeoutTime_ALL" SG_ 1211 TRM_TrailerMalfnc 500;
BA_ "InvalidValue" SG_ 1211 TRM_TrailerMalfnc "null";
BA_ "GenSigSendType" SG_ 1211 TRM_Warning_Flag_5 4;
BA_ "GenSigTimeoutTime_ALL" SG_ 1211 TRM_Warning_Flag_5 500;
BA_ "InvalidValue" SG_ 1211 TRM_Warning_Flag_5 "null";
BA_ "GenSigSendType" SG_ 1211 TRM_Warning_Flag_6 4;
BA_ "GenSigTimeoutTime_ALL" SG_ 1211 TRM_Warning_Flag_6 500;
BA_ "InvalidValue" SG_ 1211 TRM_Warning_Flag_6 "null";
BA_ "GenSigSendType" SG_ 1211 TRM_Warning_Flag_7 4;
BA_ "GenSigTimeoutTime_ALL" SG_ 1211 TRM_Warning_Flag_7 500;
BA_ "InvalidValue" SG_ 1211 TRM_Warning_Flag_7 "null";
BA_ "GenSigSendType" SG_ 1211 TRM_Warning_Flag_8 4;
BA_ "GenSigTimeoutTime_ALL" SG_ 1211 TRM_Warning_Flag_8 500;
BA_ "InvalidValue" SG_ 1211 TRM_Warning_Flag_8 "null";
BA_ "GenSigSendType" SG_ 1211 TRM_Warning_Flag_9 4;
BA_ "GenSigTimeoutTime_ALL" SG_ 1211 TRM_Warning_Flag_9 500;
BA_ "InvalidValue" SG_ 1211 TRM_Warning_Flag_9 "null";
BA_ "GenSigSendType" SG_ 1211 TRM_Warning_Flag_10 4;
BA_ "GenSigTimeoutTime_ALL" SG_ 1211 TRM_Warning_Flag_10 500;
BA_ "InvalidValue" SG_ 1211 TRM_Warning_Flag_10 "null";
BA_ "GenSigSendType" SG_ 1211 TRM_Warning_Flag_11 4;
BA_ "GenSigTimeoutTime_ALL" SG_ 1211 TRM_Warning_Flag_11 500;
BA_ "InvalidValue" SG_ 1211 TRM_Warning_Flag_11 "null";
BA_ "GenSigSendType" SG_ 1211 TRM_Warning_Flag_12 4;
BA_ "GenSigTimeoutTime_ALL" SG_ 1211 TRM_Warning_Flag_12 500;
BA_ "InvalidValue" SG_ 1211 TRM_Warning_Flag_12 "null";
BA_ "GenSigSendType" SG_ 1213 CHSKM_POD_WarnMsg 3;
BA_ "GenSigTimeoutTime_ALL" SG_ 1213 CHSKM_POD_WarnMsg 5000;
BA_ "GenSigSendType" SG_ 1213 ALV_POD_WarnMsg 3;
BA_ "GenSigTimeoutTime_ALL" SG_ 1213 ALV_POD_WarnMsg 5000;
BA_ "InvalidValue" SG_ 1213 ALV_POD_WarnMsg "Fh";
BA_ "GenSigSendType" SG_ 1213 POD_Warning_Flag_1 4;
BA_ "GenSigTimeoutTime_ALL" SG_ 1213 POD_Warning_Flag_1 5000;
BA_ "GenSigSendType" SG_ 1213 POD_Warning_Flag_2 4;
BA_ "GenSigTimeoutTime_ALL" SG_ 1213 POD_Warning_Flag_2 5000;
BA_ "GenSigSendType" SG_ 1213 POD_Warning_Flag_3 4;
BA_ "GenSigTimeoutTime_ALL" SG_ 1213 POD_Warning_Flag_3 5000;
BA_ "GenSigSendType" SG_ 1213 POD_Warning_Flag_4 4;
BA_ "GenSigTimeoutTime_ALL" SG_ 1213 POD_Warning_Flag_4 5000;
BA_ "GenSigSendType" SG_ 1213 POD_Warning_Flag_5 4;
BA_ "GenSigTimeoutTime_ALL" SG_ 1213 POD_Warning_Flag_5 5000;
BA_ "GenSigSendType" SG_ 1213 POD_Warning_Flag_6 4;
BA_ "GenSigTimeoutTime_ALL" SG_ 1213 POD_Warning_Flag_6 5000;
BA_ "GenSigSendType" SG_ 1213 POD_Warning_Flag_7 4;
BA_ "GenSigTimeoutTime_ALL" SG_ 1213 POD_Warning_Flag_7 5000;
BA_ "GenSigSendType" SG_ 1213 POD_Warning_Flag_8 4;
BA_ "GenSigTimeoutTime_ALL" SG_ 1213 POD_Warning_Flag_8 5000;
BA_ "GenSigSendType" SG_ 1213 POD_Warning_Flag_9 4;
BA_ "GenSigTimeoutTime_ALL" SG_ 1213 POD_Warning_Flag_9 5000;
BA_ "GenSigSendType" SG_ 1213 POD_Warning_Flag_10 4;
BA_ "GenSigTimeoutTime_ALL" SG_ 1213 POD_Warning_Flag_10 5000;
BA_ "GenSigSendType" SG_ 1213 POD_Warning_Flag_11 4;
BA_ "GenSigTimeoutTime_ALL" SG_ 1213 POD_Warning_Flag_11 5000;
BA_ "GenSigSendType" SG_ 1213 POD_Warning_Flag_12 4;
BA_ "GenSigTimeoutTime_ALL" SG_ 1213 POD_Warning_Flag_12 5000;
BA_ "GenSigSendType" SG_ 1213 POD_Warning_Flag_13 4;
BA_ "GenSigTimeoutTime_ALL" SG_ 1213 POD_Warning_Flag_13 5000;
BA_ "GenSigSendType" SG_ 1213 POD_Warning_Flag_14 4;
BA_ "GenSigTimeoutTime_ALL" SG_ 1213 POD_Warning_Flag_14 5000;
BA_ "GenSigSendType" SG_ 1213 POD_Warning_Flag_15 4;
BA_ "GenSigTimeoutTime_ALL" SG_ 1213 POD_Warning_Flag_15 5000;
BA_ "GenSigSendType" SG_ 1213 POD_Warning_Flag_16 4;
BA_ "GenSigTimeoutTime_ALL" SG_ 1213 POD_Warning_Flag_16 5000;
BA_ "GenSigSendType" SG_ 1213 POD_Warning_Flag_17 4;
BA_ "GenSigTimeoutTime_ALL" SG_ 1213 POD_Warning_Flag_17 5000;
BA_ "GenSigSendType" SG_ 1213 POD_Warning_Flag_18 4;
BA_ "GenSigTimeoutTime_ALL" SG_ 1213 POD_Warning_Flag_18 5000;
BA_ "GenSigSendType" SG_ 1213 POD_Warning_Flag_19 4;
BA_ "GenSigTimeoutTime_ALL" SG_ 1213 POD_Warning_Flag_19 5000;
BA_ "GenSigSendType" SG_ 1213 POD_Warning_Flag_20 4;
BA_ "GenSigTimeoutTime_ALL" SG_ 1213 POD_Warning_Flag_20 5000;
BA_ "GenSigSendType" SG_ 1213 POD_Warning_Flag_21 4;
BA_ "GenSigTimeoutTime_ALL" SG_ 1213 POD_Warning_Flag_21 5000;
BA_ "GenSigSendType" SG_ 1213 POD_Warning_Flag_22 4;
BA_ "GenSigTimeoutTime_ALL" SG_ 1213 POD_Warning_Flag_22 5000;
BA_ "GenSigSendType" SG_ 1213 POD_Warning_Flag_23 4;
BA_ "GenSigTimeoutTime_ALL" SG_ 1213 POD_Warning_Flag_23 5000;
BA_ "GenSigSendType" SG_ 1213 POD_Warning_Flag_24 4;
BA_ "GenSigTimeoutTime_ALL" SG_ 1213 POD_Warning_Flag_24 5000;
BA_ "GenSigSendType" SG_ 1213 POD_Warning_Flag_25 4;
BA_ "GenSigTimeoutTime_ALL" SG_ 1213 POD_Warning_Flag_25 5000;
BA_ "GenSigSendType" SG_ 1213 POD_Warning_Flag_26 4;
BA_ "GenSigTimeoutTime_ALL" SG_ 1213 POD_Warning_Flag_26 5000;
BA_ "GenSigSendType" SG_ 1213 POD_Warning_Flag_27 4;
BA_ "GenSigTimeoutTime_ALL" SG_ 1213 POD_Warning_Flag_27 5000;
BA_ "GenSigSendType" SG_ 1213 POD_Warning_Flag_28 4;
BA_ "GenSigTimeoutTime_ALL" SG_ 1213 POD_Warning_Flag_28 5000;
BA_ "GenSigSendType" SG_ 1213 POD_Reserved_signal3 4;
BA_ "GenSigTimeoutTime_ALL" SG_ 1213 POD_Reserved_signal3 5000;
BA_ "GenSigSendType" SG_ 1213 POD_Reserved_signal4 4;
BA_ "GenSigTimeoutTime_ALL" SG_ 1213 POD_Reserved_signal4 5000;
BA_ "GenSigSendType" SG_ 1213 POD_Reserved_signal5 4;
BA_ "GenSigTimeoutTime_ALL" SG_ 1213 POD_Reserved_signal5 5000;
BA_ "GenSigSendType" SG_ 1217 CHSKM_APM_WarnMsg 3;
BA_ "GenSigTimeoutTime_ALL" SG_ 1217 CHSKM_APM_WarnMsg 5000;
BA_ "GenSigSendType" SG_ 1217 ALV_APM_WarnMsg 3;
BA_ "GenSigTimeoutTime_ALL" SG_ 1217 ALV_APM_WarnMsg 5000;
BA_ "InvalidValue" SG_ 1217 ALV_APM_WarnMsg "Fh";
BA_ "GenSigSendType" SG_ 1217 APM_Malfunction 4;
BA_ "GenSigTimeoutTime_ALL" SG_ 1217 APM_Malfunction 5000;
BA_ "InvalidValue" SG_ 1217 APM_Malfunction "null";
BA_ "GenSigSendType" SG_ 1217 ChildWindowLockStS 4;
BA_ "GenSigTimeoutTime_ALL" SG_ 1217 ChildWindowLockStS 5000;
BA_ "GenSigSendType" SG_ 1217 APM_Warning_Flag_3 4;
BA_ "GenSigTimeoutTime_ALL" SG_ 1217 APM_Warning_Flag_3 5000;
BA_ "GenSigSendType" SG_ 1217 APM_Warning_Flag_4 4;
BA_ "GenSigTimeoutTime_ALL" SG_ 1217 APM_Warning_Flag_4 5000;
BA_ "GenSigSendType" SG_ 1217 APM_Warning_Flag_5 4;
BA_ "GenSigTimeoutTime_ALL" SG_ 1217 APM_Warning_Flag_5 5000;
BA_ "GenSigSendType" SG_ 1217 APM_Warning_Flag_6 4;
BA_ "GenSigTimeoutTime_ALL" SG_ 1217 APM_Warning_Flag_6 5000;
BA_ "GenSigSendType" SG_ 1217 APM_Warning_Flag_7 4;
BA_ "GenSigTimeoutTime_ALL" SG_ 1217 APM_Warning_Flag_7 5000;
BA_ "GenSigSendType" SG_ 1217 APM_Warning_Flag_8 4;
BA_ "GenSigTimeoutTime_ALL" SG_ 1217 APM_Warning_Flag_8 5000;
BA_ "GenSigSendType" SG_ 1217 APM_Warning_Flag_9 4;
BA_ "GenSigTimeoutTime_ALL" SG_ 1217 APM_Warning_Flag_9 5000;
BA_ "GenSigSendType" SG_ 1217 APM_Warning_Flag_10 4;
BA_ "GenSigTimeoutTime_ALL" SG_ 1217 APM_Warning_Flag_10 5000;
BA_ "GenSigSendType" SG_ 1217 APM_Warning_Flag_11 4;
BA_ "GenSigTimeoutTime_ALL" SG_ 1217 APM_Warning_Flag_11 5000;
BA_ "GenSigSendType" SG_ 1217 APM_Warning_Flag_12 4;
BA_ "GenSigTimeoutTime_ALL" SG_ 1217 APM_Warning_Flag_12 5000;
BA_ "GenSigTimeoutTime_ALL" SG_ 1218 Checksum_0x4C2 1000;
BA_ "GenSigTimeoutTime_ALL" SG_ 1218 Rolling_Counter_0x4C2 1000;
BA_ "InvalidValue" SG_ 1218 Rolling_Counter_0x4C2 "Fh";
BA_ "GenSigTimeoutTime_ALL" SG_ 1218 Event_Counter 1000;
BA_ "GenSigTimeoutTime_ALL" SG_ 1218 Event_type 1000;
BA_ "GenSigTimeoutTime_ALL" SG_ 1282 XGW_srcNodeID 2000;
BA_ "InvalidValue" SG_ 1282 XGW_srcNodeID "FFh";
BA_ "GenSigTimeoutTime_ALL" SG_ 1282 XGW_CtrlBitVector 2000;
BA_ "InvalidValue" SG_ 1282 XGW_CtrlBitVector "null";
BA_ "GenSigStartValue" SG_ 1282 XGW_usrData0 255;
BA_ "GenSigTimeoutTime_ALL" SG_ 1282 XGW_usrData0 2000;
BA_ "InvalidValue" SG_ 1282 XGW_usrData0 "null";
BA_ "GenSigStartValue" SG_ 1282 XGW_usrData1 255;
BA_ "GenSigTimeoutTime_ALL" SG_ 1282 XGW_usrData1 2000;
BA_ "InvalidValue" SG_ 1282 XGW_usrData1 "null";
BA_ "GenSigStartValue" SG_ 1282 XGW_usrData2 255;
BA_ "GenSigTimeoutTime_ALL" SG_ 1282 XGW_usrData2 2000;
BA_ "InvalidValue" SG_ 1282 XGW_usrData2 "null";
BA_ "GenSigStartValue" SG_ 1282 XGW_usrData3 255;
BA_ "GenSigTimeoutTime_ALL" SG_ 1282 XGW_usrData3 2000;
BA_ "InvalidValue" SG_ 1282 XGW_usrData3 "null";
BA_ "GenSigStartValue" SG_ 1282 XGW_usrData4 255;
BA_ "GenSigTimeoutTime_ALL" SG_ 1282 XGW_usrData4 2000;
BA_ "InvalidValue" SG_ 1282 XGW_usrData4 "null";
BA_ "GenSigStartValue" SG_ 1282 XGW_usrData5 255;
BA_ "GenSigTimeoutTime_ALL" SG_ 1282 XGW_usrData5 2000;
BA_ "InvalidValue" SG_ 1282 XGW_usrData5 "null";
BA_ "GenSigTimeoutTime_ALL" SG_ 1284 MHU_srcNodeID 2000;
BA_ "InvalidValue" SG_ 1284 MHU_srcNodeID "FFh";
BA_ "GenSigTimeoutTime_ALL" SG_ 1284 MHU_CtrlBitVector 2000;
BA_ "GenSigStartValue" SG_ 1284 MHU_usrData0 255;
BA_ "GenSigTimeoutTime_ALL" SG_ 1284 MHU_usrData0 2000;
BA_ "GenSigStartValue" SG_ 1284 MHU_usrData1 255;
BA_ "GenSigTimeoutTime_ALL" SG_ 1284 MHU_usrData1 2000;
BA_ "GenSigStartValue" SG_ 1284 MHU_usrData2 255;
BA_ "GenSigTimeoutTime_ALL" SG_ 1284 MHU_usrData2 2000;
BA_ "GenSigStartValue" SG_ 1284 MHU_usrData3 255;
BA_ "GenSigTimeoutTime_ALL" SG_ 1284 MHU_usrData3 2000;
BA_ "GenSigStartValue" SG_ 1284 MHU_usrData4 255;
BA_ "GenSigTimeoutTime_ALL" SG_ 1284 MHU_usrData4 2000;
BA_ "GenSigStartValue" SG_ 1284 MHU_usrData5 255;
BA_ "GenSigTimeoutTime_ALL" SG_ 1284 MHU_usrData5 2000;
BA_ "GenSigTimeoutTime_ALL" SG_ 1293 HUD_srcNodeID 2000;
BA_ "InvalidValue" SG_ 1293 HUD_srcNodeID "FFh";
BA_ "GenSigTimeoutTime_ALL" SG_ 1293 HUD_CtrlBitVector 2000;
BA_ "GenSigStartValue" SG_ 1293 HUD_usrData0 255;
BA_ "GenSigTimeoutTime_ALL" SG_ 1293 HUD_usrData0 2000;
BA_ "GenSigStartValue" SG_ 1293 HUD_usrData1 255;
BA_ "GenSigTimeoutTime_ALL" SG_ 1293 HUD_usrData1 2000;
BA_ "GenSigStartValue" SG_ 1293 HUD_usrData2 255;
BA_ "GenSigTimeoutTime_ALL" SG_ 1293 HUD_usrData2 2000;
BA_ "GenSigStartValue" SG_ 1293 HUD_usrData3 255;
BA_ "GenSigTimeoutTime_ALL" SG_ 1293 HUD_usrData3 2000;
BA_ "GenSigStartValue" SG_ 1293 HUD_usrData4 255;
BA_ "GenSigTimeoutTime_ALL" SG_ 1293 HUD_usrData4 2000;
BA_ "GenSigStartValue" SG_ 1293 HUD_usrData5 255;
BA_ "GenSigTimeoutTime_ALL" SG_ 1293 HUD_usrData5 2000;
BA_ "GenSigTimeoutTime_ALL" SG_ 1302 FCAM_srcNodeID 2000;
BA_ "InvalidValue" SG_ 1302 FCAM_srcNodeID "FFh";
BA_ "GenSigTimeoutTime_ALL" SG_ 1302 FCAM_CtrlBitVector 2000;
BA_ "InvalidValue" SG_ 1302 FCAM_CtrlBitVector "null";
BA_ "GenSigStartValue" SG_ 1302 FCAM_usrData0 255;
BA_ "GenSigTimeoutTime_ALL" SG_ 1302 FCAM_usrData0 2000;
BA_ "InvalidValue" SG_ 1302 FCAM_usrData0 "null";
BA_ "GenSigStartValue" SG_ 1302 FCAM_usrData1 255;
BA_ "GenSigTimeoutTime_ALL" SG_ 1302 FCAM_usrData1 2000;
BA_ "InvalidValue" SG_ 1302 FCAM_usrData1 "null";
BA_ "GenSigStartValue" SG_ 1302 FCAM_usrData2 255;
BA_ "GenSigTimeoutTime_ALL" SG_ 1302 FCAM_usrData2 2000;
BA_ "InvalidValue" SG_ 1302 FCAM_usrData2 "null";
BA_ "GenSigStartValue" SG_ 1302 FCAM_usrData3 255;
BA_ "GenSigTimeoutTime_ALL" SG_ 1302 FCAM_usrData3 2000;
BA_ "InvalidValue" SG_ 1302 FCAM_usrData3 "null";
BA_ "GenSigStartValue" SG_ 1302 FCAM_usrData4 255;
BA_ "GenSigTimeoutTime_ALL" SG_ 1302 FCAM_usrData4 2000;
BA_ "InvalidValue" SG_ 1302 FCAM_usrData4 "null";
BA_ "GenSigStartValue" SG_ 1302 FCAM_usrData5 255;
BA_ "GenSigTimeoutTime_ALL" SG_ 1302 FCAM_usrData5 2000;
BA_ "InvalidValue" SG_ 1302 FCAM_usrData5 "null";
BA_ "GenSigTimeoutTime_ALL" SG_ 1303 PAS_srcNodeID 2000;
BA_ "InvalidValue" SG_ 1303 PAS_srcNodeID "FFh";
BA_ "GenSigTimeoutTime_ALL" SG_ 1303 PAS_CtrlBitVector 2000;
BA_ "GenSigTimeoutTime_ALL" SG_ 1303 PAS_usrData0 2000;
BA_ "GenSigStartValue" SG_ 1303 PAS_usrData0 255;
BA_ "GenSigTimeoutTime_ALL" SG_ 1303 PAS_usrData1 2000;
BA_ "GenSigStartValue" SG_ 1303 PAS_usrData1 255;
BA_ "GenSigTimeoutTime_ALL" SG_ 1303 PAS_usrData2 2000;
BA_ "GenSigStartValue" SG_ 1303 PAS_usrData2 255;
BA_ "GenSigTimeoutTime_ALL" SG_ 1303 PAS_usrData3 2000;
BA_ "GenSigStartValue" SG_ 1303 PAS_usrData3 255;
BA_ "GenSigTimeoutTime_ALL" SG_ 1303 PAS_usrData4 2000;
BA_ "GenSigStartValue" SG_ 1303 PAS_usrData4 255;
BA_ "GenSigTimeoutTime_ALL" SG_ 1303 PAS_usrData5 2000;
BA_ "GenSigStartValue" SG_ 1303 PAS_usrData5 255;
BA_ "GenSigTimeoutTime_ALL" SG_ 1326 EASC_srcNodeID 2000;
BA_ "InvalidValue" SG_ 1326 EASC_srcNodeID "FFh";
BA_ "GenSigTimeoutTime_ALL" SG_ 1326 EASC_CtrlBitVector 2000;
BA_ "GenSigStartValue" SG_ 1326 EASC_usrData0 255;
BA_ "GenSigTimeoutTime_ALL" SG_ 1326 EASC_usrData0 2000;
BA_ "GenSigStartValue" SG_ 1326 EASC_usrData1 255;
BA_ "GenSigTimeoutTime_ALL" SG_ 1326 EASC_usrData1 2000;
BA_ "GenSigStartValue" SG_ 1326 EASC_usrData2 255;
BA_ "GenSigTimeoutTime_ALL" SG_ 1326 EASC_usrData2 2000;
BA_ "GenSigStartValue" SG_ 1326 EASC_usrData3 255;
BA_ "GenSigTimeoutTime_ALL" SG_ 1326 EASC_usrData3 2000;
BA_ "GenSigStartValue" SG_ 1326 EASC_usrData4 255;
BA_ "GenSigTimeoutTime_ALL" SG_ 1326 EASC_usrData4 2000;
BA_ "GenSigStartValue" SG_ 1326 EASC_usrData5 255;
BA_ "GenSigTimeoutTime_ALL" SG_ 1326 EASC_usrData5 2000;
BA_ "GenSigTimeoutTime_ALL" SG_ 1327 CPD_srcNodeID 2000;
BA_ "InvalidValue" SG_ 1327 CPD_srcNodeID "FFh";
BA_ "GenSigTimeoutTime_ALL" SG_ 1327 CPD_CtrlBitVector 2000;
BA_ "GenSigStartValue" SG_ 1327 CPD_usrData0 255;
BA_ "GenSigTimeoutTime_ALL" SG_ 1327 CPD_usrData0 2000;
BA_ "GenSigStartValue" SG_ 1327 CPD_usrData1 255;
BA_ "GenSigTimeoutTime_ALL" SG_ 1327 CPD_usrData1 2000;
BA_ "GenSigStartValue" SG_ 1327 CPD_usrData2 255;
BA_ "GenSigTimeoutTime_ALL" SG_ 1327 CPD_usrData2 2000;
BA_ "GenSigStartValue" SG_ 1327 CPD_usrData3 255;
BA_ "GenSigTimeoutTime_ALL" SG_ 1327 CPD_usrData3 2000;
BA_ "GenSigStartValue" SG_ 1327 CPD_usrData4 255;
BA_ "GenSigTimeoutTime_ALL" SG_ 1327 CPD_usrData4 2000;
BA_ "GenSigStartValue" SG_ 1327 CPD_usrData5 255;
BA_ "GenSigTimeoutTime_ALL" SG_ 1327 CPD_usrData5 2000;
BA_ "GenSigSendType" SG_ 1537 BCM_DiagRespData0 7;
BA_ "InvalidValue" SG_ 1537 BCM_DiagRespData0 "null";
BA_ "GenSigSendType" SG_ 1537 BCM_DiagRespData1 7;
BA_ "InvalidValue" SG_ 1537 BCM_DiagRespData1 "null";
BA_ "GenSigSendType" SG_ 1537 BCM_DiagRespData2 7;
BA_ "InvalidValue" SG_ 1537 BCM_DiagRespData2 "null";
BA_ "GenSigSendType" SG_ 1537 BCM_DiagRespData3 7;
BA_ "InvalidValue" SG_ 1537 BCM_DiagRespData3 "null";
BA_ "GenSigSendType" SG_ 1537 BCM_DiagRespData4 7;
BA_ "InvalidValue" SG_ 1537 BCM_DiagRespData4 "null";
BA_ "GenSigSendType" SG_ 1537 BCM_DiagRespData5 7;
BA_ "InvalidValue" SG_ 1537 BCM_DiagRespData5 "null";
BA_ "GenSigSendType" SG_ 1537 BCM_DiagRespData6 7;
BA_ "InvalidValue" SG_ 1537 BCM_DiagRespData6 "null";
BA_ "GenSigSendType" SG_ 1537 BCM_DiagRespData7 7;
BA_ "InvalidValue" SG_ 1537 BCM_DiagRespData7 "null";
BA_ "GenSigSendType" SG_ 1538 XGW_DiagRespData0 7;
BA_ "InvalidValue" SG_ 1538 XGW_DiagRespData0 "null";
BA_ "GenSigSendType" SG_ 1538 XGW_DiagRespData1 7;
BA_ "InvalidValue" SG_ 1538 XGW_DiagRespData1 "null";
BA_ "GenSigSendType" SG_ 1538 XGW_DiagRespData2 7;
BA_ "InvalidValue" SG_ 1538 XGW_DiagRespData2 "null";
BA_ "GenSigSendType" SG_ 1538 XGW_DiagRespData3 7;
BA_ "InvalidValue" SG_ 1538 XGW_DiagRespData3 "null";
BA_ "GenSigSendType" SG_ 1538 XGW_DiagRespData4 7;
BA_ "InvalidValue" SG_ 1538 XGW_DiagRespData4 "null";
BA_ "GenSigSendType" SG_ 1538 XGW_DiagRespData5 7;
BA_ "InvalidValue" SG_ 1538 XGW_DiagRespData5 "null";
BA_ "GenSigSendType" SG_ 1538 XGW_DiagRespData6 7;
BA_ "InvalidValue" SG_ 1538 XGW_DiagRespData6 "null";
BA_ "GenSigSendType" SG_ 1538 XGW_DiagRespData7 7;
BA_ "InvalidValue" SG_ 1538 XGW_DiagRespData7 "null";
BA_ "InvalidValue" SG_ 1540 MHU_DiagRespData0 "null";
BA_ "GenSigSendType" SG_ 1540 MHU_DiagRespData1 7;
BA_ "InvalidValue" SG_ 1540 MHU_DiagRespData1 "null";
BA_ "GenSigSendType" SG_ 1540 MHU_DiagRespData2 7;
BA_ "InvalidValue" SG_ 1540 MHU_DiagRespData2 "null";
BA_ "GenSigSendType" SG_ 1540 MHU_DiagRespData3 7;
BA_ "InvalidValue" SG_ 1540 MHU_DiagRespData3 "null";
BA_ "GenSigSendType" SG_ 1540 MHU_DiagRespData4 7;
BA_ "InvalidValue" SG_ 1540 MHU_DiagRespData4 "null";
BA_ "GenSigSendType" SG_ 1540 MHU_DiagRespData5 7;
BA_ "InvalidValue" SG_ 1540 MHU_DiagRespData5 "null";
BA_ "GenSigSendType" SG_ 1540 MHU_DiagRespData6 7;
BA_ "InvalidValue" SG_ 1540 MHU_DiagRespData6 "null";
BA_ "GenSigSendType" SG_ 1540 MHU_DiagRespData7 7;
BA_ "InvalidValue" SG_ 1540 MHU_DiagRespData7 "null";
BA_ "GenSigSendType" SG_ 1541 AMP_DiagRespData0 7;
BA_ "InvalidValue" SG_ 1541 AMP_DiagRespData0 "null";
BA_ "GenSigSendType" SG_ 1541 AMP_DiagRespData1 7;
BA_ "InvalidValue" SG_ 1541 AMP_DiagRespData1 "null";
BA_ "GenSigSendType" SG_ 1541 AMP_DiagRespData2 7;
BA_ "InvalidValue" SG_ 1541 AMP_DiagRespData2 "null";
BA_ "GenSigSendType" SG_ 1541 AMP_DiagRespData3 7;
BA_ "InvalidValue" SG_ 1541 AMP_DiagRespData3 "null";
BA_ "GenSigSendType" SG_ 1541 AMP_DiagRespData4 7;
BA_ "InvalidValue" SG_ 1541 AMP_DiagRespData4 "null";
BA_ "GenSigSendType" SG_ 1541 AMP_DiagRespData5 7;
BA_ "InvalidValue" SG_ 1541 AMP_DiagRespData5 "null";
BA_ "GenSigSendType" SG_ 1541 AMP_DiagRespData6 7;
BA_ "InvalidValue" SG_ 1541 AMP_DiagRespData6 "null";
BA_ "GenSigSendType" SG_ 1541 AMP_DiagRespData7 7;
BA_ "InvalidValue" SG_ 1541 AMP_DiagRespData7 "null";
BA_ "GenSigSendType" SG_ 1544 ACM_DiagRespData0 7;
BA_ "InvalidValue" SG_ 1544 ACM_DiagRespData0 "null";
BA_ "GenSigSendType" SG_ 1544 ACM_DiagRespData1 7;
BA_ "InvalidValue" SG_ 1544 ACM_DiagRespData1 "null";
BA_ "GenSigSendType" SG_ 1544 ACM_DiagRespData2 7;
BA_ "InvalidValue" SG_ 1544 ACM_DiagRespData2 "null";
BA_ "GenSigSendType" SG_ 1544 ACM_DiagRespData3 7;
BA_ "InvalidValue" SG_ 1544 ACM_DiagRespData3 "null";
BA_ "GenSigSendType" SG_ 1544 ACM_DiagRespData4 7;
BA_ "InvalidValue" SG_ 1544 ACM_DiagRespData4 "null";
BA_ "GenSigSendType" SG_ 1544 ACM_DiagRespData5 7;
BA_ "InvalidValue" SG_ 1544 ACM_DiagRespData5 "null";
BA_ "GenSigSendType" SG_ 1544 ACM_DiagRespData6 7;
BA_ "InvalidValue" SG_ 1544 ACM_DiagRespData6 "null";
BA_ "GenSigSendType" SG_ 1544 ACM_DiagRespData7 7;
BA_ "InvalidValue" SG_ 1544 ACM_DiagRespData7 "null";
BA_ "GenSigSendType" SG_ 1545 CCUF_DiagRespData0 7;
BA_ "InvalidValue" SG_ 1545 CCUF_DiagRespData0 "null";
BA_ "GenSigSendType" SG_ 1545 CCUF_DiagRespData1 7;
BA_ "InvalidValue" SG_ 1545 CCUF_DiagRespData1 "null";
BA_ "GenSigSendType" SG_ 1545 CCUF_DiagRespData2 7;
BA_ "InvalidValue" SG_ 1545 CCUF_DiagRespData2 "null";
BA_ "GenSigSendType" SG_ 1545 CCUF_DiagRespData3 7;
BA_ "InvalidValue" SG_ 1545 CCUF_DiagRespData3 "null";
BA_ "GenSigSendType" SG_ 1545 CCUF_DiagRespData4 7;
BA_ "InvalidValue" SG_ 1545 CCUF_DiagRespData4 "null";
BA_ "GenSigSendType" SG_ 1545 CCUF_DiagRespData5 7;
BA_ "InvalidValue" SG_ 1545 CCUF_DiagRespData5 "null";
BA_ "GenSigSendType" SG_ 1545 CCUF_DiagRespData6 7;
BA_ "InvalidValue" SG_ 1545 CCUF_DiagRespData6 "null";
BA_ "GenSigSendType" SG_ 1545 CCUF_DiagRespData7 7;
BA_ "InvalidValue" SG_ 1545 CCUF_DiagRespData7 "null";
BA_ "GenSigSendType" SG_ 1549 HUD_DiagRespData0 7;
BA_ "InvalidValue" SG_ 1549 HUD_DiagRespData0 "null";
BA_ "GenSigSendType" SG_ 1549 HUD_DiagRespData1 7;
BA_ "InvalidValue" SG_ 1549 HUD_DiagRespData1 "null";
BA_ "GenSigSendType" SG_ 1549 HUD_DiagRespData2 7;
BA_ "InvalidValue" SG_ 1549 HUD_DiagRespData2 "null";
BA_ "GenSigSendType" SG_ 1549 HUD_DiagRespData3 7;
BA_ "InvalidValue" SG_ 1549 HUD_DiagRespData3 "null";
BA_ "GenSigSendType" SG_ 1549 HUD_DiagRespData4 7;
BA_ "InvalidValue" SG_ 1549 HUD_DiagRespData4 "null";
BA_ "GenSigSendType" SG_ 1549 HUD_DiagRespData5 7;
BA_ "InvalidValue" SG_ 1549 HUD_DiagRespData5 "null";
BA_ "GenSigSendType" SG_ 1549 HUD_DiagRespData6 7;
BA_ "InvalidValue" SG_ 1549 HUD_DiagRespData6 "null";
BA_ "GenSigSendType" SG_ 1549 HUD_DiagRespData7 7;
BA_ "InvalidValue" SG_ 1549 HUD_DiagRespData7 "null";
BA_ "GenSigSendType" SG_ 1550 ETG_DiagRespData0 7;
BA_ "InvalidValue" SG_ 1550 ETG_DiagRespData0 "null";
BA_ "GenSigSendType" SG_ 1550 ETG_DiagRespData1 7;
BA_ "InvalidValue" SG_ 1550 ETG_DiagRespData1 "null";
BA_ "GenSigSendType" SG_ 1550 ETG_DiagRespData2 7;
BA_ "InvalidValue" SG_ 1550 ETG_DiagRespData2 "null";
BA_ "GenSigSendType" SG_ 1550 ETG_DiagRespData3 7;
BA_ "InvalidValue" SG_ 1550 ETG_DiagRespData3 "null";
BA_ "GenSigSendType" SG_ 1550 ETG_DiagRespData4 7;
BA_ "InvalidValue" SG_ 1550 ETG_DiagRespData4 "null";
BA_ "GenSigSendType" SG_ 1550 ETG_DiagRespData5 7;
BA_ "InvalidValue" SG_ 1550 ETG_DiagRespData5 "null";
BA_ "GenSigSendType" SG_ 1550 ETG_DiagRespData6 7;
BA_ "InvalidValue" SG_ 1550 ETG_DiagRespData6 "null";
BA_ "GenSigSendType" SG_ 1550 ETG_DiagRespData7 7;
BA_ "InvalidValue" SG_ 1550 ETG_DiagRespData7 "null";
BA_ "GenSigSendType" SG_ 1551 YSS_DiagRespData0 7;
BA_ "InvalidValue" SG_ 1551 YSS_DiagRespData0 "null";
BA_ "GenSigSendType" SG_ 1551 YSS_DiagRespData1 7;
BA_ "InvalidValue" SG_ 1551 YSS_DiagRespData1 "null";
BA_ "GenSigSendType" SG_ 1551 YSS_DiagRespData2 7;
BA_ "InvalidValue" SG_ 1551 YSS_DiagRespData2 "null";
BA_ "GenSigSendType" SG_ 1551 YSS_DiagRespData3 7;
BA_ "InvalidValue" SG_ 1551 YSS_DiagRespData3 "null";
BA_ "GenSigSendType" SG_ 1551 YSS_DiagRespData4 7;
BA_ "InvalidValue" SG_ 1551 YSS_DiagRespData4 "null";
BA_ "GenSigSendType" SG_ 1551 YSS_DiagRespData5 7;
BA_ "InvalidValue" SG_ 1551 YSS_DiagRespData5 "null";
BA_ "GenSigSendType" SG_ 1551 YSS_DiagRespData6 7;
BA_ "InvalidValue" SG_ 1551 YSS_DiagRespData6 "null";
BA_ "GenSigSendType" SG_ 1551 YSS_DiagRespData7 7;
BA_ "InvalidValue" SG_ 1551 YSS_DiagRespData7 "null";
BA_ "GenSigSendType" SG_ 1552 GS_DiagRespData0 7;
BA_ "InvalidValue" SG_ 1552 GS_DiagRespData0 "null";
BA_ "GenSigSendType" SG_ 1552 GS_DiagRespData1 7;
BA_ "InvalidValue" SG_ 1552 GS_DiagRespData1 "null";
BA_ "GenSigSendType" SG_ 1552 GS_DiagRespData2 7;
BA_ "InvalidValue" SG_ 1552 GS_DiagRespData2 "null";
BA_ "GenSigSendType" SG_ 1552 GS_DiagRespData3 7;
BA_ "InvalidValue" SG_ 1552 GS_DiagRespData3 "null";
BA_ "GenSigSendType" SG_ 1552 GS_DiagRespData4 7;
BA_ "InvalidValue" SG_ 1552 GS_DiagRespData4 "null";
BA_ "GenSigSendType" SG_ 1552 GS_DiagRespData5 7;
BA_ "InvalidValue" SG_ 1552 GS_DiagRespData5 "null";
BA_ "GenSigSendType" SG_ 1552 GS_DiagRespData6 7;
BA_ "InvalidValue" SG_ 1552 GS_DiagRespData6 "null";
BA_ "GenSigSendType" SG_ 1552 GS_DiagRespData7 7;
BA_ "InvalidValue" SG_ 1552 GS_DiagRespData7 "null";
VAL_ 1153 BCM_NoValidKey_1 0 "None" 1 "Alert";
VAL_ 1153 BCM_SSB_defect 0 "None" 1 "Alert";
VAL_ 1153 BCM_WrongGearPosToStart 0 "None" 1 "Alert";
VAL_ 1153 BCM_NoValidKey_2 0 "None" 1 "Alert";
VAL_ 1153 BCM_PressBrakeToStart 0 "None" 1 "Alert";
VAL_ 1153 BCM_TurnOffPosLightRemindr 0 "None" 1 "Alert";
VAL_ 1153 BCM_KeyFob_LowBattery 0 "None" 1 "Alert";
VAL_ 1153 BCM_StopLightDefect 0 "None" 1 "Alert";
VAL_ 1153 BCM_LowBeamDefect 0 "None" 1 "Alert";
VAL_ 1153 BCM_HighBeamDefect 0 "None" 1 "Alert";
VAL_ 1153 BCM_PositionLightDefect 0 "None" 1 "Alert";
VAL_ 1153 BCM_CHMLS_Defect 0 "None" 1 "Alert";
VAL_ 1153 BCM_LicencePlateLight_Defect 0 "None" 1 "Alert";
VAL_ 1153 BCM_FrontFog_Defect 0 "None" 1 "Alert";
VAL_ 1153 BCM_RearFog_Defect 0 "None" 1 "Alert";
VAL_ 1153 BCM_ReverseLightDefect 0 "None" 1 "Alert";
VAL_ 1153 BCM_RLS_Malfunction 0 "None" 1 "Alert";
VAL_ 1153 BCM_12VBattery_LowLevel 0 "None" 1 "Alert";
VAL_ 1153 BCM_ForgetKeyFOBInCar 0 "None" 1 "Alert";
VAL_ 1153 BCM_12VBattery_Discharging 0 "None" 1 "Alert";
VAL_ 1153 BCM_TurnIndicatorDefect 0 "None" 1 "Alert";
VAL_ 1153 BCM_dTPMS_Malfunc 0 "None" 1 "Alert";
VAL_ 1153 BCM_dTPMS_Malfunc_LostSensor 0 "None" 1 "Alert";
VAL_ 1153 BCM_dTPMS_LowPressure 0 "None" 1 "Alert";
VAL_ 1153 BCM_dTPMS_RapidLeak 0 "None" 1 "Alert";
VAL_ 1153 BCM_dTPMS_HighTemperature 0 "None" 1 "Alert";
VAL_ 1153 BCM_dTPMS_HighPressure 0 "None" 1 "Alert";
VAL_ 1153 BCM_dTPMS_LowBattery 0 "None" 1 "Alert";
VAL_ 1153 BCM_Keyfob_Leftcar 0 "None" 1 "Alert";
VAL_ 1153 BCM_IDB_Brakelight_Malfunction 0 "None" 1 "Alert";
VAL_ 1153 BCM_VCU_Brakelight_Malfunction 0 "None" 1 "Alert";
VAL_ 1153 BCM_ADAS_Turnlight_Malfunction 0 "None" 1 "Alert";
VAL_ 1153 BCM_ADAS_Highbeam_Malfunction 0 "None" 1 "Alert";
VAL_ 1153 BCM_ADAS_LowBeam_Malfunction 0 "None" 1 "Alert";
VAL_ 1153 BCM_MHU_Malfunction 0 "None" 1 "Alert";
VAL_ 1153 BCM_BCM_Malfunction 0 "None" 1 "Alert";
VAL_ 1153 BCM_SCM_Malfunction 0 "None" 1 "Alert";
VAL_ 1153 BCM_CrashSignalDefect 0 "None" 1 "Alert";
VAL_ 1153 BCM_FrontWiperDefect 0 "None" 1 "Alert";
VAL_ 1153 BCM_Rear_RightDoorLockDefect 0 "None" 1 "Alert";
VAL_ 1153 BCM_RearLeftDoorLockDefect 0 "None" 1 "Alert";
VAL_ 1153 BCM_Front_RightDoorLockDefect 0 "None" 1 "Alert";
VAL_ 1153 BCM_FrontLeftDoorLockDefect 0 "None" 1 "Alert";
VAL_ 1153 BCM_LDML_Malfunction 0 "None" 1 "Alert";
VAL_ 1153 BCM_LDMR_Malfunction 0 "None" 1 "Alert";
VAL_ 1153 BCM_RLBL_Malfunction 0 "None" 1 "Alert";
VAL_ 1153 BCM_RLBR_Malfunction 0 "None" 1 "Alert";
VAL_ 1153 BCM_RLT_Malfunction 0 "None" 1 "Alert";
VAL_ 1153 BCM_BCM_POWER_Malfunction 0 "None" 1 "Alert";
VAL_ 1153 BCM_IDB_AutoHazardBlinking_Malf 0 "None" 1 "Alert";
VAL_ 1153 BCM_AutoHLLevelingFault 0 "None" 1 "Alert";
VAL_ 1154 XGW_AutoHLLevelingFault 0 "No Error" 1 "Error";
VAL_ 1154 XGW_WasherFluidLvlSw 0 "No Error" 1 "Error";
VAL_ 1154 XGW_Warning_Flag_3 0 "No Error" 1 "Error";
VAL_ 1154 XGW_Warning_Flag_4 0 "No Error" 1 "Error";
VAL_ 1154 XGW_Warning_Flag_5 0 "No Error" 1 "Error";
VAL_ 1154 XGW_Warning_Flag_6 0 "No Error" 1 "Error";
VAL_ 1154 XGW_Warning_Flag_7 0 "No Error" 1 "Error";
VAL_ 1154 XGW_Warning_Flag_8 0 "No Error" 1 "Error";
VAL_ 1154 XGW_Warning_Flag_9 0 "No Error" 1 "Error";
VAL_ 1154 XGW_Warning_Flag_10 0 "No Error" 1 "Error";
VAL_ 1154 XGW_Warning_Flag_11 0 "No Error" 1 "Error";
VAL_ 1154 XGW_Warning_Flag_12 0 "No Error" 1 "Error";
VAL_ 1155 TPMS_FLTirePress 255 "Invalid";
VAL_ 1155 TPMS_FRTirePress 255 "Invalid";
VAL_ 1155 TPMS_RLTirePress 255 "Invalid";
VAL_ 1155 TPMS_RRTirePress 255 "Invalid";
VAL_ 1155 TPMS_FLTirePressAlarm 0 "No warning" 1 "High pressure warning" 2 "Low pressure warning" 3 "Quick leakage" 4 "Lost Sensor" 5 "Sensor battery low" 6 "Sensor failure" 7 "Reserved";
VAL_ 1155 TPMS_FRTirePressAlarm 0 "No warning" 1 "High pressure warning" 2 "Low pressure warning" 3 "Quick leakage" 4 "Lost Sensor" 5 "Sensor battery low" 6 "Sensor failure" 7 "Reserved";
VAL_ 1155 TPMS_RLTirePressAlarm 0 "No warning" 1 "High pressure warning" 2 "Low pressure warning" 3 "Quick leakage" 4 "Lost Sensor" 5 "Sensor battery low" 6 "Sensor failure" 7 "Reserved";
VAL_ 1155 TPMS_RRTirePressAlarm 0 "No warning" 1 "High pressure warning" 2 "Low pressure warning" 3 "Quick leakage" 4 "Lost Sensor" 5 "Sensor battery low" 6 "Sensor failure" 7 "Reserved";
VAL_ 1155 TPMS_TirePosition 0 "No any sensor" 1 "Left Front tire" 2 "Right Front tire" 3 "Right Rear tire" 4 "Left Rear tire" 5 "reseved" 6 "reseved" 7 "reserved";
VAL_ 1155 TPMS_ready2learning 0 "Invalid" 1 "Ready";
VAL_ 1155 TPMS_TireTempAlarm 0 "No warning" 1 "High Temperature Warning";
VAL_ 1155 TPMS_LearningStatus 0 "invalid" 1 "Left Front tire done" 2 "Right Front tire done" 3 "Right Rear tire done" 4 "Left Rear tire done" 5 "All completed" 6 "Failure" 7 "reserved";
VAL_ 1155 TPMS_TireTemp 255 "Invalid";
VAL_ 1156 APA_ReqInfoDispTxt3 0 "No request" 1 "Timeout, parking exit" 2 "gear intervention, parking exit" 3 "throttle intervention, parking exit" 4 "steering wheel intervention, parking exit" 5 "Electronic handbrake intervention, parking exit'" 6 "The main driving door is opened and parking is suspended" 7 "The number of parking times exceeds the limit, and the parking is exited" 8 "The road slope is too big, parking exit" 9 "The number of resumable interruptions exceeds the limit, and the parking is exited" 10 "Associated ECU failure, parking exit" 11 "Parking speed exceeds limit, parking exit" 12 "Parking system failure, parking exit" 13 "The gear can't be switched normally, parking exit" 14 "The driver takes the initiative to exit" 15 "The vehicle cannot move, parking exit" 16 "When an obstacle is detected, parking is suspended" 17 "The main driver's seat belt is loosened and parking is suspended" 18 "The co-drive door is opened and parking is suspended" 19 "The parking space is limited, and the parking function is exited" 20 "The tailgate is opened and parking is suspended" 21 "The right rear door is opened and parking is suspended" 22 "The left rear door is opened and parking is suspended" 23 "The front hatch door is opened and parking is suspended" 24 "parking is completed" 25 "parking failed" 26 "Remote connection is interrupted" 27 "Please hang in the P gear" 28 "Remote parking has started" 29 "noise interference causing parking termination";
VAL_ 1156 APA_ReqInfoDispTxt4 0 "No request" 1 "The main driver's door is open" 2 "passenger door is open" 3 "left passenger area is open" 4 " passenger area on the right is open" 5 "The front hatch door is open" 6 "The tailgate is open" 7 "APA parking assist system failure, parking exit" 8 "APA related actuator failure" 9 "ACC/ICC function cannot be activated" 10 "vehicle speed is too fast" 11 "slope is too large to activate";
VAL_ 1156 APA_ReqInfoDispTxt2 0 "No request" 1 "drive forward" 2 "parking space has been found" 3 "Parking starts" 4 " Auto parking in progress" 5 "please put the gear into P please release the brake and steering" 6 "please release the brake and steering" 7 "If you need to continue parking please click the Continue button";
VAL_ 1156 APA_ReqInfoDispTxt1 0 "No request" 1 "APA parking assist system is faulty and the parking function cannot be opened" 2 "APA related actuator failure, unable to open the parking function" 3 "The ACC/ICA function is activated, and the parking function cannot be turned on" 4 "The ESC auxiliary function is activated, and the parking function cannot be turned on" 5 "The slope is too large to activate the parking function" 6 "The trailer is detected, the FAPA/RP function cannot be turned on";
VAL_ 1156 APA_MHU_Displayparkingtype 0 "No Request" 1 "Request";
VAL_ 1156 APA_FuncModeFdbck 0 "No Function" 1 "parking in" 2 "parking out" 3 "drag parking";
VAL_ 1156 APA_Currentfunction 0 "No function" 1 "Auto Parking in" 2 "Auto Parking out" 3 "Auto drag parking in" 4 "Remote Parking in" 5 "Remote Parking out'" 6 "Straight Parking";
VAL_ 1156 APA_MHU_Status 0 "Off" 1 "Standby" 2 "Enable" 3 "Active" 4 "Finished" 5 "Suspend" 6 "abort" 7 "Failed";
VAL_ 1157 TBOX_RPADirSel 0 "No Park Slot" 1 "FrntLeCrss" 2 "FrntLePrl" 3 "Frnt" 4 "FrntRiCrss" 5 "FrntRiPrl" 6 "Bck" 7 "BckLe" 8 "BckRi" 9 "Reserved" 10 "Reserved" 11 "Reserved" 12 "Reserved" 13 "Reserved" 14 "Reserved" 15 "SNA" ;
VAL_ 1158 TPMS_FLTirePressAlarm2 0 "No warning" 1 "High pressure warning" 2 "Low pressure warning" 3 "Quick leakage" 4 "Lost Sensor" 5 "Sensor battery low" 6 "Sensor failure" 7 "Reserved" ;
VAL_ 1158 TPMS_FRTirePressAlarm2 0 "No warning" 1 "High pressure warning" 2 "Low pressure warning" 3 "Quick leakage" 4 "Lost Sensor" 5 "Sensor battery low" 6 "Sensor failure" 7 "Reserved" ;
VAL_ 1158 TPMS_RLTirePressAlarm2 0 "No warning" 1 "High pressure warning" 2 "Low pressure warning" 3 "Quick leakage" 4 "Lost Sensor" 5 "Sensor battery low" 6 "Sensor failure" 7 "Reserved" ;
VAL_ 1158 TPMS_RRTirePressAlarm2 0 "No warning" 1 "High pressure warning" 2 "Low pressure warning" 3 "Quick leakage" 4 "Lost Sensor" 5 "Sensor battery low" 6 "Sensor failure" 7 "Reserved" ;
VAL_ 1160 ACM_Malfunction 0 "ACM_Failure" 1 "ACM_Normal_Operation";
VAL_ 1160 ACM_Pre_Drive_Check 0 "ACM_Pre_Drive_Check" 1 "ACM_Normal_Operation";
VAL_ 1160 ACM_in_Plant_Mode 0 "ACM_in_Plant_Mode" 1 "ACM_in_Normal_Mode";
VAL_ 1160 ACM_PAB_Suppression 0 "Not_Suppressed" 1 "Suppressed" 2 "Function Failure" 3 "Invalid_Value";
VAL_ 1160 ACM_Airbag_Disabled 0 "ACM_AirBag_Disabled" 1 "ACM_Normal_Operation";
VAL_ 1160 ACM_Development_Calibration 0 "ACM_Dev_Calibrated" 1 "ACM_Normal_Operation";
VAL_ 1160 ACM_In_Disposal_Mode 0 "ACM_In_Disposal_Mode" 1 "ACM_Normal_Operation";
VAL_ 1160 ACM_Seatbelt_Reminder_Request 0 "Seatbelt reminder NOT activated" 1 "Seatbelt reminder activated";
VAL_ 1160 ACM_SBR_Chime_Req 0 "No Active Chime" 1 "Active Chime";
VAL_ 1160 ACM_SBR_Blinking_Req 0 "No Blinking" 1 "Blinking 1Hz";
VAL_ 1161 CCU_Malfunction 0 "No Error" 1 "Error";
VAL_ 1161 CCU_Warning_Flag_2 0 "No Error" 1 "Error";
VAL_ 1161 CCU_Warning_Flag_3 0 "No Error" 1 "Error";
VAL_ 1161 CCU_Warning_Flag_4 0 "No Error" 1 "Error";
VAL_ 1161 CCU_Warning_Flag_5 0 "No Error" 1 "Error";
VAL_ 1161 CCU_Warning_Flag_6 0 "No Error" 1 "Error";
VAL_ 1161 CCU_Warning_Flag_7 0 "No Error" 1 "Error";
VAL_ 1161 CCU_Warning_Flag_8 0 "No Error" 1 "Error";
VAL_ 1161 CCU_Warning_Flag_9 0 "No Error" 1 "Error";
VAL_ 1161 CCU_Warning_Flag_10 0 "No Error" 1 "Error";
VAL_ 1161 CCU_Warning_Flag_11 0 "No Error" 1 "Error";
VAL_ 1161 CCU_Warning_Flag_12 0 "No Error" 1 "Error";
VAL_ 1165 HUD_Malfunction 0 "No Error" 1 "Error";
VAL_ 1165 HUD_Failed_Temporary 0 "No Error" 1 "Error";
VAL_ 1165 HUD_Overheating 0 "No Error" 1 "Error";
VAL_ 1165 HUD_Warning_Flag_4 0 "No Error" 1 "Error";
VAL_ 1165 HUD_Warning_Flag_5 0 "No Error" 1 "Error";
VAL_ 1165 HUD_Warning_Flag_6 0 "No Error" 1 "Error";
VAL_ 1165 HUD_Warning_Flag_7 0 "No Error" 1 "Error";
VAL_ 1165 HUD_Warning_Flag_8 0 "No Error" 1 "Error";
VAL_ 1165 HUD_Warning_Flag_9 0 "No Error" 1 "Error";
VAL_ 1165 HUD_Warning_Flag_10 0 "No Error" 1 "Error";
VAL_ 1165 HUD_Warning_Flag_11 0 "No Error" 1 "Error";
VAL_ 1165 HUD_Warning_Flag_12 0 "No Error" 1 "Error";
VAL_ 1166 ETG_Malfunction 0 "No Error" 1 "Error";
VAL_ 1166 ETG_Warning_Flag_2 0 "No Error" 1 "Error";
VAL_ 1166 ETG_Warning_Flag_3 0 "No Error" 1 "Error";
VAL_ 1166 ETG_Warning_Flag_4 0 "No Error" 1 "Error";
VAL_ 1166 ETG_Warning_Flag_5 0 "No Error" 1 "Error";
VAL_ 1166 ETG_Warning_Flag_6 0 "No Error" 1 "Error";
VAL_ 1166 ETG_Warning_Flag_7 0 "No Error" 1 "Error";
VAL_ 1166 ETG_Warning_Flag_8 0 "No Error" 1 "Error";
VAL_ 1166 ETG_Warning_Flag_9 0 "No Error" 1 "Error";
VAL_ 1166 ETG_Warning_Flag_10 0 "No Error" 1 "Error";
VAL_ 1166 ETG_Warning_Flag_11 0 "No Error" 1 "Error";
VAL_ 1166 ETG_Warning_Flag_12 0 "No Error" 1 "Error";
VAL_ 1168 GS_Warning_Flag_1 0 "No Error" 1 "Error";
VAL_ 1168 GS_Warning_Flag_2 0 "No Error" 1 "Error";
VAL_ 1168 GS_Warning_Flag_3 0 "No Error" 1 "Error";
VAL_ 1168 GS_Warning_Flag_4 0 "No Error" 1 "Error";
VAL_ 1168 GS_Warning_Flag_5 0 "No Error" 1 "Error";
VAL_ 1168 GS_Warning_Flag_6 0 "No Error" 1 "Error";
VAL_ 1168 GS_Warning_Flag_7 0 "No Error" 1 "Error";
VAL_ 1168 GS_Warning_Flag_8 0 "No Error" 1 "Error";
VAL_ 1168 GS_Warning_Flag_9 0 "No Error" 1 "Error";
VAL_ 1168 GS_Warning_Flag_10 0 "No Error" 1 "Error";
VAL_ 1168 GS_Warning_Flag_11 0 "No Error" 1 "Error";
VAL_ 1168 GS_Warning_Flag_12 0 "No Error" 1 "Error";
VAL_ 1171 BMS_PackTempSts 0 "No warning" 1 "Over Temperature Warning" 2 "Under Temperature Warning" 3 "Extreme Low Temp Error";
VAL_ 1171 BMS_ThermalRunaway 0 "No Warning" 1 "Warning";
VAL_ 1171 BMS_BatteryReplacement 0 "No Warning" 1 "Warning";
VAL_ 1171 BMS_Warning_PowerDegrade 0 "Normal" 1 "Pack Power Degrade";
VAL_ 1171 BMS_Warning_DeltaSoC 0 "Normal" 1 "Delta SOC high";
VAL_ 1171 BMS_Warning_HVILSts 0 "Normal" 1 "HVIL error detected";
VAL_ 1171 BMS_Warning_Isolation 0 "Normal" 1 "Isolation reached level 3";
VAL_ 1171 BMS_Warning_CoolantLeakage 0 "Normal" 1 "Coolant leakage detected";
VAL_ 1171 BMS_MalfunctionSts 0 "No Warning" 1 "Warning";
VAL_ 1171 BMS_LowBattery 0 "No warning" 1 "Low level" 2 "Extremely low level";
VAL_ 1171 BMS_Warning_DeltaTemperature 0 "Normal" 1 "Level 1 warning" 2 "Level 2 extreme";
VAL_ 1171 BMS_Warning_BDUTemperatureSts 0 "Normal" 1 "BDU temp warning" 2 "BDU hot" 3 "BDU extreme hot";
VAL_ 1171 BMS_Warning_Contactor_Aging 0 "No Warning" 1 "Warning"  ;
VAL_ 1178 EDS_R_Warning_Flag_1 0 "No Error" 1 "Error";
VAL_ 1178 EDS_R_Warning_Flag_2 0 "No Error" 1 "Error";
VAL_ 1178 EDS_R_Warning_Flag_3 0 "No Error" 1 "Error";
VAL_ 1178 EDS_R_Warning_Flag_4 0 "No Error" 1 "Error";
VAL_ 1178 EDS_R_Warning_Flag_5 0 "No Error" 1 "Error";
VAL_ 1178 EDS_R_Warning_Flag_6 0 "No Error" 1 "Error";
VAL_ 1178 EDS_R_Warning_Flag_7 0 "No Error" 1 "Error";
VAL_ 1178 EDS_R_Warning_Flag_8 0 "No Error" 1 "Error";
VAL_ 1178 EDS_R_Warning_Flag_9 0 "No Error" 1 "Error";
VAL_ 1178 EDS_R_Warning_Flag_10 0 "No Error" 1 "Error";
VAL_ 1178 EDS_R_Warning_Flag_11 0 "No Error" 1 "Error";
VAL_ 1178 EDS_R_Warning_Flag_12 0 "No Error" 1 "Error";
VAL_ 1179 EDS_F_Warning_Flag_1 0 "No Error" 1 "Error";
VAL_ 1179 EDS_F_Warning_Flag_2 0 "No Error" 1 "Error";
VAL_ 1179 EDS_F_Warning_Flag_3 0 "No Error" 1 "Error";
VAL_ 1179 EDS_F_Warning_Flag_4 0 "No Error" 1 "Error";
VAL_ 1179 EDS_F_Warning_Flag_5 0 "No Error" 1 "Error";
VAL_ 1179 EDS_F_Warning_Flag_6 0 "No Error" 1 "Error";
VAL_ 1179 EDS_F_Warning_Flag_7 0 "No Error" 1 "Error";
VAL_ 1179 EDS_F_Warning_Flag_8 0 "No Error" 1 "Error";
VAL_ 1179 EDS_F_Warning_Flag_9 0 "No Error" 1 "Error";
VAL_ 1179 EDS_F_Warning_Flag_10 0 "No Error" 1 "Error";
VAL_ 1179 EDS_F_Warning_Flag_11 0 "No Error" 1 "Error";
VAL_ 1179 EDS_F_Warning_Flag_12 0 "No Error" 1 "Error";
VAL_ 1191 RCU_DAA_NoOpDoorOpen 0 "None" 1 "Alert";
VAL_ 1191 RCU_EHandBrk_fault 0 "None" 1 "Alert";
VAL_ 1191 RCU_EOL_NotDone 0 "None" 1 "Alert";
VAL_ 1191 RCU_ECD_RWU_active 0 "None" 1 "Alert";
VAL_ 1191 RCU_ParkOnSteepInclination 0 "None" 1 "Alert";
VAL_ 1191 RCU_BrkForceNotEnough 0 "None" 1 "Alert";
VAL_ 1191 RCU_ReleaseEPB_Wo_PressBrk 0 "None" 1 "Alert";
VAL_ 1191 RCU_ParkBrkApplied 0 "None" 1 "Alert";
VAL_ 1191 RCU_Swch_Mafnc 0 "None" 1 "Alert";
VAL_ 1191 RCU_DAA_NoOpBeltUnbuckled 0 "None" 1 "Alert";
VAL_ 1191 RCU_RollerBenchMode 0 "None" 1 "Alert";
VAL_ 1191 RCU_EPB_ParkLampState 0 "No Indication" 1 "Durable" 2 "Bilinking 1Hz" 3 "Blinking 3Hz";
VAL_ 1191 RCU_EPB_WarnLampState 0 "No Indication" 1 "Durable" 2 "Bilinking 1Hz" 3 "Blinking 3Hz";
VAL_ 1191 RCU_WflagRes36 0 "None" 1 "Alert";
VAL_ 1191 RCU_WflagRes37 0 "None" 1 "Alert";
VAL_ 1191 RCU_WflagRes38 0 "None" 1 "Alert";
VAL_ 1191 RCU_WflagRes39 0 "None" 1 "Alert";
VAL_ 1191 RCU_WflagRes40 0 "None" 1 "Alert";
VAL_ 1191 RCU_WflagRes41 0 "None" 1 "Alert";
VAL_ 1191 RCU_WflagRes42 0 "None" 1 "Alert";
VAL_ 1191 RCU_WflagRes43 0 "None" 1 "Alert";
VAL_ 1191 RCU_WflagRes44 0 "None" 1 "Alert";
VAL_ 1191 RCU_WflagRes45 0 "None" 1 "Alert";
VAL_ 1191 RCU_WflagRes46 0 "None" 1 "Alert";
VAL_ 1191 RCU_WflagRes47 0 "None" 1 "Alert";
VAL_ 1192 EPS_Malfunction 0 "No Error" 1 "Error";
VAL_ 1192 EPS_Reduced 0 "No Error" 1 "Error";
VAL_ 1192 EPS_Overheat 0 "No Error" 1 "Error";
VAL_ 1192 EPS_NotReady 0 "No Error" 1 "Error";
VAL_ 1192 EPS_Warning_Flag_5 0 "No Error" 1 "Error";
VAL_ 1192 EPS_Warning_Flag_6 0 "No Error" 1 "Error";
VAL_ 1192 EPS_Warning_Flag_7 0 "No Error" 1 "Error";
VAL_ 1192 EPS_Warning_Flag_8 0 "No Error" 1 "Error";
VAL_ 1192 EPS_Warning_Flag_9 0 "No Error" 1 "Error";
VAL_ 1192 EPS_Warning_Flag_10 0 "No Error" 1 "Error";
VAL_ 1192 EPS_Warning_Flag_11 0 "No Error" 1 "Error";
VAL_ 1192 EPS_Warning_Flag_12 0 "No Error" 1 "Error";
VAL_ 1193 IDB_ESC_fault 0 "No Error" 1 "Error";
VAL_ 1193 IDB_ABS_fault 0 "No Error" 1 "Error";
VAL_ 1193 IDB_BrkLowFluid 0 "No Error" 1 "Error";
VAL_ 1193 IDB_BrkSysFault 0 "No Error" 1 "Error";
VAL_ 1193 IDB_fault 0 "No Error" 1 "Error";
VAL_ 1193 IDB_HydraulicBrkAssist_Fault 0 "No Error" 1 "Error";
VAL_ 1193 IDB_HAS_Fault 0 "No Error" 1 "Error";
VAL_ 1193 IDB_TSM_Fault 0 "No Error" 1 "Error";
VAL_ 1196 VCU_GearPOnlyAtStationaryAlert 0 "None" 1 "Alert";
VAL_ 1196 VCU_GearP_NotPossibleAlert 0 "None" 1 "Alert";
VAL_ 1196 VCU_PressBrakeToEngageGear 0 "None" 1 "Alert";
VAL_ 1196 VCU_CantChangeGear 0 "None" 1 "Alert";
VAL_ 1196 VCU_GearMalfunction 0 "None" 1 "Alert";
VAL_ 1196 VCU_RangeAlert 0 "None" 1 "Alert";
VAL_ 1196 VCU_HVSystemReduced 0 "None" 1 "Alert";
VAL_ 1196 VCU_FrontEDSReduced 0 "None" 1 "Alert";
VAL_ 1196 VCU_FrontEDS_Malfunc 0 "None" 1 "Alert";
VAL_ 1196 VCU_RearEDSReduced 0 "None" 1 "Alert";
VAL_ 1196 VCU_RearEDS_Malfunc 0 "None" 1 "Alert";
VAL_ 1196 VCU_CoolingSystem_Malfunc 0 "None" 1 "Alert";
VAL_ 1196 VCU_NeutralRequest 0 "None" 1 "Alert";
VAL_ 1196 VCU_SoftShutdown 0 "None" 1 "Alert";
VAL_ 1196 VCU_EmergencyShutdown 0 "None" 1 "Alert";
VAL_ 1196 VCU_ChgPortDoorSys_Malfunc 0 "None" 1 "Alert";
VAL_ 1196 VCU_Gearchange_NotPossible 0 "None" 1 "Alert";
VAL_ 1196 VCU_12v_Warning 0 "None" 1 "Alert";
VAL_ 1196 VCU_WflagRes19 0 "None" 1 "Alert";
VAL_ 1196 VCU_WflagRes20 0 "None" 1 "Alert";
VAL_ 1196 VCU_WflagRes21 0 "None" 1 "Alert";
VAL_ 1196 VCU_WflagRes22 0 "None" 1 "Alert";
VAL_ 1196 VCU_WflagRes23 0 "None" 1 "Alert";
VAL_ 1196 VCU_WflagRes24 0 "None" 1 "Alert";
VAL_ 1196 VCU_WflagRes25 0 "None" 1 "Alert";
VAL_ 1196 VCU_WflagRes26 0 "None" 1 "Alert";
VAL_ 1196 VCU_WflagRes27 0 "None" 1 "Alert";
VAL_ 1196 VCU_SuperFastCharge_longer 0 "None" 1 "Alert";
VAL_ 1196 VCU_InvalidLimitSpeed 0 "None" 1 "Alert";
VAL_ 1196 VCU_InvalidCruiseSpeed 0 "None" 1 "Alert";
VAL_ 1198 EASC_Warning_Flag_1 0 "No Error" 1 "Error";
VAL_ 1198 EASC_Warning_Flag_2 0 "No Error" 1 "Error";
VAL_ 1198 EASC_Warning_Flag_3 0 "No Error" 1 "Error";
VAL_ 1198 EASC_Warning_Flag_4 0 "No Error" 1 "Error";
VAL_ 1198 EASC_Warning_Flag_5 0 "No Error" 1 "Error";
VAL_ 1198 EASC_Warning_Flag_6 0 "No Error" 1 "Error";
VAL_ 1198 EASC_Warning_Flag_7 0 "No Error" 1 "Error";
VAL_ 1198 EASC_Warning_Flag_8 0 "No Error" 1 "Error";
VAL_ 1198 EASC_Warning_Flag_9 0 "No Error" 1 "Error";
VAL_ 1198 EASC_Warning_Flag_10 0 "No Error" 1 "Error";
VAL_ 1198 EASC_Warning_Flag_11 0 "No Error" 1 "Error";
VAL_ 1198 EASC_Warning_Flag_12 0 "No Error" 1 "Error";
VAL_ 1199 CPD_Malfunction 0 "No Error" 1 "Error";
VAL_ 1199 CPD_SensorFault 0 "No error" 1 "Temporarily not available" 2 "Permanently not available";
VAL_ 1199 CPD_Warning_Flag_4 0 "No Error" 1 "Error";
VAL_ 1199 CPD_Warning_Flag_5 0 "No Error" 1 "Error";
VAL_ 1199 CPD_Warning_Flag_6 0 "No Error" 1 "Error";
VAL_ 1199 CPD_Warning_Flag_7 0 "No Error" 1 "Error";
VAL_ 1199 CPD_Warning_Flag_8 0 "No Error" 1 "Error";
VAL_ 1199 CPD_Warning_Flag_9 0 "No Error" 1 "Error";
VAL_ 1199 CPD_Warning_Flag_10 0 "No Error" 1 "Error";
VAL_ 1199 CPD_Warning_Flag_11 0 "No Error" 1 "Error";
VAL_ 1199 CPD_Warning_Flag_12 0 "No Error" 1 "Error";
VAL_ 1209 BSD_Warning_Flag_7 0 "No Error" 1 "Error";
VAL_ 1209 BSD_Warning_Flag_8 0 "No Error" 1 "Error";
VAL_ 1209 BSD_Warning_Flag_9 0 "No Error" 1 "Error";
VAL_ 1209 BSD_Warning_Flag_10 0 "No Error" 1 "Error";
VAL_ 1209 BSD_Warning_Flag_14 0 "No Error" 1 "Error";
VAL_ 1209 BSD_Warning_Flag_21 0 "No Error" 1 "Error";
VAL_ 1209 BSD_Warning_Flag_22 0 "No Error" 1 "Error";
VAL_ 1209 BSD_Warning_Flag_23 0 "No Error" 1 "Error";
VAL_ 1209 BSD_Warning_Flag_24 0 "No Error" 1 "Error";
VAL_ 1211 TRM_LightMalfnc 0 "No Error" 1 "Error";
VAL_ 1211 TRM_TurnLeftMafnc 0 "No Error" 1 "Error";
VAL_ 1211 TRM_TurnRightMafnc 0 "No Error" 1 "Error";
VAL_ 1211 TRM_TrailerMalfnc 0 "No Error" 1 "Error";
VAL_ 1211 TRM_Warning_Flag_5 0 "No Error" 1 "Error";
VAL_ 1211 TRM_Warning_Flag_6 0 "No Error" 1 "Error";
VAL_ 1211 TRM_Warning_Flag_7 0 "No Error" 1 "Error";
VAL_ 1211 TRM_Warning_Flag_8 0 "No Error" 1 "Error";
VAL_ 1211 TRM_Warning_Flag_9 0 "No Error" 1 "Error";
VAL_ 1211 TRM_Warning_Flag_10 0 "No Error" 1 "Error";
VAL_ 1211 TRM_Warning_Flag_11 0 "No Error" 1 "Error";
VAL_ 1211 TRM_Warning_Flag_12 0 "No Error" 1 "Error";
VAL_ 1213 POD_Warning_Flag_1 0 "No Error" 1 "Error";
VAL_ 1213 POD_Warning_Flag_2 0 "No Error" 1 "Error";
VAL_ 1213 POD_Warning_Flag_3 0 "No Error" 1 "Error";
VAL_ 1213 POD_Warning_Flag_4 0 "No Error" 1 "Error";
VAL_ 1213 POD_Warning_Flag_5 0 "No Error" 1 "Error";
VAL_ 1213 POD_Warning_Flag_6 0 "No Error" 1 "Error";
VAL_ 1213 POD_Warning_Flag_7 0 "No Error" 1 "Error";
VAL_ 1213 POD_Warning_Flag_8 0 "No Error" 1 "Error";
VAL_ 1213 POD_Warning_Flag_9 0 "No Error" 1 "Error";
VAL_ 1213 POD_Warning_Flag_10 0 "No Error" 1 "Error";
VAL_ 1213 POD_Warning_Flag_11 0 "No Error" 1 "Error";
VAL_ 1213 POD_Warning_Flag_12 0 "No Error" 1 "Error";
VAL_ 1213 POD_Warning_Flag_13 0 "No Error" 1 "Error";
VAL_ 1213 POD_Warning_Flag_14 0 "No Error" 1 "Error";
VAL_ 1213 POD_Warning_Flag_15 0 "No Error" 1 "Error";
VAL_ 1213 POD_Warning_Flag_16 0 "No Error" 1 "Error";
VAL_ 1213 POD_Warning_Flag_17 0 "No Error" 1 "Error";
VAL_ 1213 POD_Warning_Flag_18 0 "No Error" 1 "Error";
VAL_ 1213 POD_Warning_Flag_19 0 "No Error" 1 "Error";
VAL_ 1213 POD_Warning_Flag_20 0 "No Error" 1 "Error";
VAL_ 1213 POD_Warning_Flag_21 0 "No Error" 1 "Error";
VAL_ 1213 POD_Warning_Flag_22 0 "No Error" 1 "Error";
VAL_ 1213 POD_Warning_Flag_23 0 "No Error" 1 "Error";
VAL_ 1213 POD_Warning_Flag_24 0 "No Error" 1 "Error";
VAL_ 1213 POD_Warning_Flag_25 0 "No Error" 1 "Error";
VAL_ 1213 POD_Warning_Flag_26 0 "No Error" 1 "Error";
VAL_ 1213 POD_Warning_Flag_27 0 "No Error" 1 "Error";
VAL_ 1213 POD_Warning_Flag_28 0 "No Error" 1 "Error";
VAL_ 1217 APM_Malfunction 0 "No Error" 1 "Error";
VAL_ 1217 ChildWindowLockStS 0 "No Error" 1 "Error";
VAL_ 1217 APM_Warning_Flag_3 0 "No Error" 1 "Error";
VAL_ 1217 APM_Warning_Flag_4 0 "No Error" 1 "Error";
VAL_ 1217 APM_Warning_Flag_5 0 "No Error" 1 "Error";
VAL_ 1217 APM_Warning_Flag_6 0 "No Error" 1 "Error";
VAL_ 1217 APM_Warning_Flag_7 0 "No Error" 1 "Error";
VAL_ 1217 APM_Warning_Flag_8 0 "No Error" 1 "Error";
VAL_ 1217 APM_Warning_Flag_9 0 "No Error" 1 "Error";
VAL_ 1217 APM_Warning_Flag_10 0 "No Error" 1 "Error";
VAL_ 1217 APM_Warning_Flag_11 0 "No Error" 1 "Error";
VAL_ 1217 APM_Warning_Flag_12 0 "No Error" 1 "Error";
